VERSION ""

NS_ :

BS_:

BU_: WPC2 PSB SHVU_RR FCS EMCU SLB GW_APSU GW_DLBCU ARS RCM CGW_CCU GW_RLPSU ATS RLHV SGU PFSU ALBCU GW_RRPSU DSAU SWRC SHVU_FR RCS GW_DPSU BLTN_CAM SCM OHCL RWPC RRHV WPC HOD ASAU

BO_ 1941 GST_BLTN_CAM: 8 CGW_CCU
 SG_ GST_BLTN_CAM_Byte : 0|64@1+ (1,0) [0|0] ""  BLTN_CAM

BO_ 2015 GST_ALL: 8 CGW_CCU
 SG_ GST_ALL_Byte : 0|64@1+ (1,0) [0|0] ""  BLTN_CAM

BO_ 1949 BTLN_CAM_GST: 8 BLTN_CAM
 SG_ BLTN_CAM_GST_Byte : 0|64@1+ (1,0) [0|0] ""  CGW_CCU

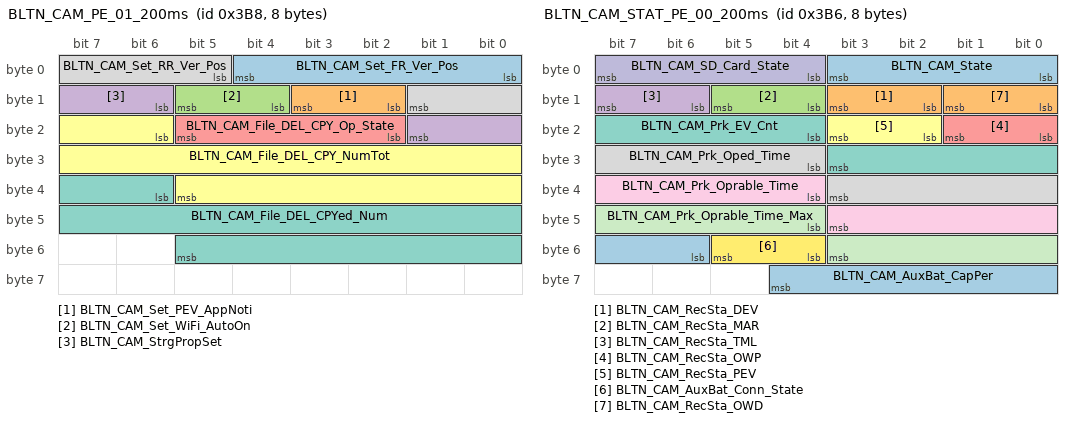
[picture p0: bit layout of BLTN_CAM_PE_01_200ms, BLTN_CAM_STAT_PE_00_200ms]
BO_ 952 BLTN_CAM_PE_01_200ms: 8 BLTN_CAM
 SG_ BLTN_CAM_Set_FR_Ver_Pos : 0|5@1+ (1,0) [0|0] ""  CGW_CCU
 SG_ BLTN_CAM_Set_PEV_AppNoti : 10|2@1+ (1,0) [0|0] ""  CGW_CCU
 SG_ BLTN_CAM_Set_WiFi_AutoOn : 12|2@1+ (1,0) [0|0] ""  CGW_CCU
 SG_ BLTN_CAM_StrgPropSet : 14|4@1+ (1,0) [0|0] ""  CGW_CCU
 SG_ BLTN_CAM_File_DEL_CPY_Op_State : 18|4@1+ (1,0) [0|0] ""  CGW_CCU
 SG_ BLTN_CAM_File_DEL_CPY_NumTot : 22|16@1+ (1,0) [0|0] ""  CGW_CCU
 SG_ BLTN_CAM_File_DEL_CPYed_Num : 38|16@1+ (1,0) [0|0] ""  CGW_CCU
 SG_ BLTN_CAM_Set_RR_Ver_Pos : 5|5@1+ (1,0) [0|0] ""  CGW_CCU

BO_ 1219 HU_BLTN_CAM_E_00: 8 CGW_CCU
 SG_ BLTN_CAM_Rec_OWD_NvalueSet : 0|2@1+ (1,0) [0|0] ""  BLTN_CAM
 SG_ BLTN_CAM_Time_Stm_NvalueSet : 10|2@1+ (1,0) [0|0] ""  BLTN_CAM
 SG_ BLTN_CAM_Spd_Stm_NvalueSet : 12|2@1+ (1,0) [0|0] ""  BLTN_CAM
 SG_ BLTN_CAM_Locatn_Stm_NvalueSet : 14|2@1+ (1,0) [0|0] ""  BLTN_CAM
 SG_ BLTN_CAM_TrnSig_Stm_NvalueSet : 16|2@1+ (1,0) [0|0] ""  BLTN_CAM
 SG_ BLTN_CAM_AclBrk_Stm_NvalueSet : 18|2@1+ (1,0) [0|0] ""  BLTN_CAM
 SG_ BLTN_CAM_Rec_DEV_NvalueSet : 2|2@1+ (1,0) [0|0] ""  BLTN_CAM
 SG_ BLTN_CAM_GearPos_Stm_NvalueSet : 20|2@1+ (1,0) [0|0] ""  BLTN_CAM
 SG_ BLTN_CAM_EVSen_Stm_NvalueSet : 22|2@1+ (1,0) [0|0] ""  BLTN_CAM
 SG_ BLTN_CAM_Strangl_Stm_NvalueSet : 24|2@1+ (1,0) [0|0] ""  BLTN_CAM
 SG_ BLTN_CAM_EV_RecMaxTime_NvalueSet : 26|2@1+ (1,0) [0|0] ""  BLTN_CAM
 SG_ BLTN_CAM_PrkTime_NvalueSet : 30|8@1+ (1,0) [0|0] "Hour"  BLTN_CAM
 SG_ BLTN_CAM_EV_BfrTime_NvalueSet : 38|5@1+ (1,0) [0|0] ""  BLTN_CAM
 SG_ BLTN_CAM_Rec_OWP_NvalueSet : 4|2@1+ (1,0) [0|0] ""  BLTN_CAM
 SG_ BLTN_CAM_EV_AftTime_NvalueSet : 43|5@1+ (1,0) [0|0] ""  BLTN_CAM
 SG_ BLTN_CAM_TML_Int_NvalueSet : 48|4@1+ (1,0) [0|0] ""  BLTN_CAM
 SG_ BLTN_CAM_Sen_DEV_NvalueSet : 52|4@1+ (1,0) [0|0] ""  BLTN_CAM
 SG_ BLTN_CAM_Sen_PEV_NvalueSet : 56|4@1+ (1,0) [0|0] ""  BLTN_CAM
 SG_ BLTN_CAM_Rec_PEV_NvalueSet : 6|2@1+ (1,0) [0|0] ""  BLTN_CAM
 SG_ BLTN_CAM_AudRec_NvalueSet : 8|2@1+ (1,0) [0|0] ""  BLTN_CAM

BO_ 950 BLTN_CAM_STAT_PE_00_200ms: 8 BLTN_CAM
 SG_ BLTN_CAM_State : 0|4@1+ (1,0) [0|0] ""  CGW_CCU
 SG_ BLTN_CAM_RecSta_DEV : 10|2@1+ (1,0) [0|0] ""  CGW_CCU
 SG_ BLTN_CAM_RecSta_MAR : 12|2@1+ (1,0) [0|0] ""  CGW_CCU
 SG_ BLTN_CAM_RecSta_TML : 14|2@1+ (1,0) [0|0] ""  CGW_CCU
 SG_ BLTN_CAM_RecSta_OWP : 16|2@1+ (1,0) [0|0] ""  CGW_CCU
 SG_ BLTN_CAM_RecSta_PEV : 18|2@1+ (1,0) [0|0] ""  CGW_CCU
 SG_ BLTN_CAM_Prk_EV_Cnt : 20|8@1+ (1,0) [0|0] ""  CGW_CCU
 SG_ BLTN_CAM_Prk_Oped_Time : 28|8@1+ (1,0) [0|0] "Hour"  CGW_CCU
 SG_ BLTN_CAM_Prk_Oprable_Time : 36|8@1+ (1,0) [0|0] "Hour"  CGW_CCU
 SG_ BLTN_CAM_SD_Card_State : 4|4@1+ (1,0) [0|0] ""  CGW_CCU
 SG_ BLTN_CAM_Prk_Oprable_Time_Max : 44|8@1+ (1,0) [0|0] "Hour"  CGW_CCU
 SG_ BLTN_CAM_AuxBat_Conn_State : 52|2@1+ (1,0) [0|0] ""  CGW_CCU
 SG_ BLTN_CAM_AuxBat_CapPer : 54|7@1+ (1,0) [0|0] "%"  CGW_CCU
 SG_ BLTN_CAM_RecSta_OWD : 8|2@1+ (1,0) [0|0] ""  CGW_CCU

BO_ 951 BLTN_CAM_PE_00_200ms: 8 BLTN_CAM
 SG_ BLTN_CAM_RecSet_OWD : 0|2@1+ (1,0) [0|0] ""  CGW_CCU
 SG_ BLTN_CAM_Set_Tim_Stm : 10|2@1+ (1,0) [0|0] ""  CGW_CCU
 SG_ BLTN_CAM_Set_Spd_Stm : 12|2@1+ (1,0) [0|0] ""  CGW_CCU
 SG_ BLTN_CAM_Set_Locatn_Stm : 14|2@1+ (1,0) [0|0] ""  CGW_CCU
 SG_ BLTN_CAM_Set_TrnSig_Stm : 16|2@1+ (1,0) [0|0] ""  CGW_CCU
 SG_ BLTN_CAM_Set_AclBrk_Stm : 18|2@1+ (1,0) [0|0] ""  CGW_CCU
 SG_ BLTN_CAM_RecSet_DEV : 2|2@1+ (1,0) [0|0] ""  CGW_CCU
 SG_ BLTN_CAM_Set_GearPos_Stm : 20|2@1+ (1,0) [0|0] ""  CGW_CCU
 SG_ BLTN_CAM_Set_EVSen_Stm : 22|2@1+ (1,0) [0|0] ""  CGW_CCU
 SG_ BLTN_CAM_Set_StrAngl_Stm : 24|2@1+ (1,0) [0|0] ""  CGW_CCU
 SG_ BLTN_CAM_Set_EV_RecMaxTime : 26|2@1+ (1,0) [0|0] ""  CGW_CCU
 SG_ BLTN_CAM_Set_PrkTime : 30|8@1+ (1,0) [0|0] "Hour"  CGW_CCU
 SG_ BLTN_CAM_Set_EV_BfrTime : 38|5@1+ (1,0) [0|0] ""  CGW_CCU
 SG_ BLTN_CAM_RecSet_OWP : 4|2@1+ (1,0) [0|0] ""  CGW_CCU
 SG_ BLTN_CAM_Set_EV_AftTime : 43|5@1+ (1,0) [0|0] ""  CGW_CCU
 SG_ BLTN_CAM_Set_Drv_TML_Int : 48|4@1+ (1,0) [0|0] ""  CGW_CCU
 SG_ BLTN_CAM_SenSet_DEV : 52|4@1+ (1,0) [0|0] ""  CGW_CCU
 SG_ BLTN_CAM_SenSet_PEV : 56|4@1+ (1,0) [0|0] ""  CGW_CCU
 SG_ BLTN_CAM_RecSet_PEV : 6|2@1+ (1,0) [0|0] ""  CGW_CCU
 SG_ BLTN_CAM_AudRec_Set : 8|2@1+ (1,0) [0|0] ""  CGW_CCU

BO_ 2307024129 EMS_08_100ms_1: 8 CGW_CCU
 SG_ HEV_BrkLtSwSta : 62|2@1+ (1,0) [0|0] ""  BLTN_CAM

BO_ 2176872449 HTCU_05_10ms_1: 8 CGW_CCU
 SG_ HDCT_GearSelDis : 60|4@1+ (1,0) [0|0] ""  SWRC,BLTN_CAM

BO_ 1239 HU_Car_PE_01: 8 CGW_CCU
 SG_ HU_PwrState : 16|4@1+ (1,0) [0|0] ""  BLTN_CAM
 SG_ HU_VehiclePwr : 4|4@1+ (1,0) [0|0] ""  BLTN_CAM,SGU

BO_ 1240 HU_GW_PE_01: 8 CGW_CCU
 SG_ HU_ThemeType : 10|6@1+ (1,0) [0|0] ""  ATS,BLTN_CAM
 SG_ CF_AVN_ProfileIDRValue : 40|4@1+ (1,0) [0|0] ""  BLTN_CAM,GW_DLBCU,GW_DPSU,RCM,RWPC,SGU,WPC,WPC2

BO_ 2214659330 EMS_07_10ms_2: 8 CGW_CCU
 SG_ HEV_AccelPdlVal : 39|10@1+ (0.09784,0) [0|0] "%"  BLTN_CAM

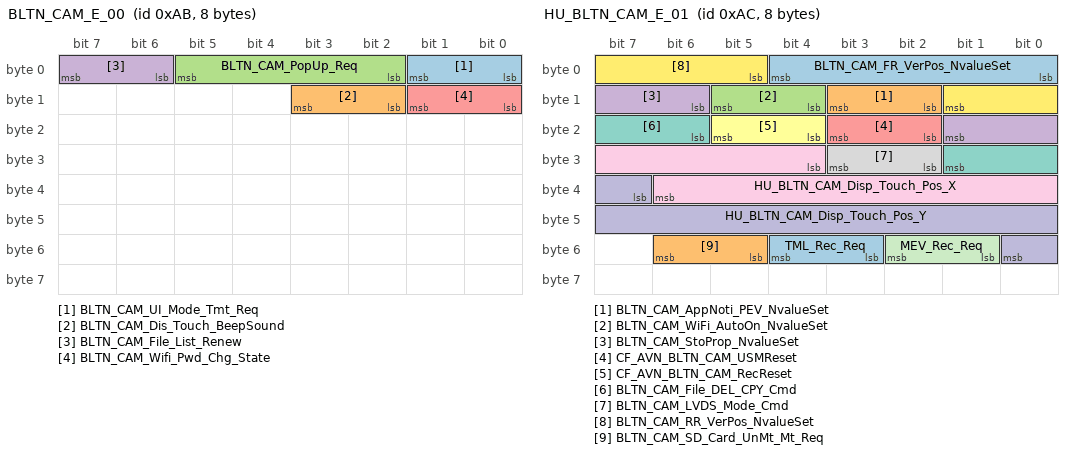
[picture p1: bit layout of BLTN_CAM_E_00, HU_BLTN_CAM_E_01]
BO_ 171 BLTN_CAM_E_00: 8 BLTN_CAM
 SG_ BLTN_CAM_UI_Mode_Tmt_Req : 0|2@1+ (1,0) [0|0] ""  CGW_CCU
 SG_ BLTN_CAM_Dis_Touch_BeepSound : 10|2@1+ (1,0) [0|0] ""  CGW_CCU
 SG_ BLTN_CAM_PopUp_Req : 2|4@1+ (1,0) [0|0] ""  CGW_CCU
 SG_ BLTN_CAM_File_List_Renew : 6|2@1+ (1,0) [0|0] ""  CGW_CCU
 SG_ BLTN_CAM_Wifi_Pwd_Chg_State : 8|2@1+ (1,0) [0|0] ""  CGW_CCU

BO_ 2164277249 TCU_01_10ms_1: 8 CGW_CCU
 SG_ TCU_GearSlctDis : 32|4@1+ (1,0) [0|0] ""  BLTN_CAM,GW_APSU,GW_RLPSU,GW_RRPSU,PFSU,RLHV,RRHV,SWRC

BO_ 2172675329 IEB_01_10ms_1: 8 CGW_CCU
 SG_ IEB_BrkActvSta : 56|2@1+ (1,0) [0|0] ""  BLTN_CAM

BO_ 172 HU_BLTN_CAM_E_01: 8 CGW_CCU
 SG_ BLTN_CAM_FR_VerPos_NvalueSet : 0|5@1+ (1,0) [0|0] ""  BLTN_CAM
 SG_ BLTN_CAM_AppNoti_PEV_NvalueSet : 10|2@1+ (1,0) [0|0] ""  BLTN_CAM
 SG_ BLTN_CAM_WiFi_AutoOn_NvalueSet : 12|2@1+ (1,0) [0|0] ""  BLTN_CAM
 SG_ BLTN_CAM_StoProp_NvalueSet : 14|4@1+ (1,0) [0|0] ""  BLTN_CAM
 SG_ CF_AVN_BLTN_CAM_USMReset : 18|2@1+ (1,0) [0|0] ""  BLTN_CAM
 SG_ CF_AVN_BLTN_CAM_RecReset : 20|2@1+ (1,0) [0|0] ""  BLTN_CAM
 SG_ BLTN_CAM_File_DEL_CPY_Cmd : 22|4@1+ (1,0) [0|0] ""  BLTN_CAM
 SG_ BLTN_CAM_LVDS_Mode_Cmd : 26|2@1+ (1,0) [0|0] ""  BLTN_CAM
 SG_ HU_BLTN_CAM_Disp_Touch_Pos_X : 28|11@1+ (1,0) [0|0] ""  BLTN_CAM
 SG_ HU_BLTN_CAM_Disp_Touch_Pos_Y : 39|10@1+ (1,0) [0|0] ""  BLTN_CAM
 SG_ MEV_Rec_Req : 49|2@1+ (1,0) [0|0] ""  BLTN_CAM
 SG_ BLTN_CAM_RR_VerPos_NvalueSet : 5|5@1+ (1,0) [0|0] ""  BLTN_CAM
 SG_ TML_Rec_Req : 51|2@1+ (1,0) [0|0] ""  BLTN_CAM
 SG_ BLTN_CAM_SD_Card_UnMt_Mt_Req : 53|2@1+ (1,0) [0|0] ""  BLTN_CAM

BO_ 799 SBCM_DRV_01_200ms: 8 CGW_CCU
 SG_ DRV_CrashUnlockCmd : 10|1@1+ (1,0) [0|0] ""  BLTN_CAM
 SG_ Warn_DrvDrSwSta_SBCM : 20|2@1+ (1,0) [0|0] ""  ATS,BLTN_CAM,GW_DPSU,PSB,RWPC,WPC,WPC2

BO_ 2227254529 BAT_01_10ms_1: 8 CGW_CCU
 SG_ BAT_SocVal : 40|8@1+ (1,0) [0|0] "%"  BLTN_CAM

BO_ 912 HU_BLTN_CAM_PE_00_200ms: 8 CGW_CCU
 SG_ HU_BLTN_CAM_UI_Mode : 0|4@1+ (1,0) [0|0] ""  BLTN_CAM
 SG_ HU_BLTN_CAM_Display : 4|3@1+ (1,0) [0|0] ""  BLTN_CAM

BO_ 1266 HU_CLU_PE_05: 8 CGW_CCU
 SG_ HU_LanguageInfo : 0|8@1+ (1,0) [0|0] ""  ATS,BLTN_CAM

BO_ 905 SBCM_RR_01_200ms: 8 CGW_CCU
 SG_ RR_CrashUnlockCmd : 10|1@1+ (1,0) [0|0] ""  BLTN_CAM
 SG_ Warn_RrRtDrSwSta_SBCM : 16|2@1+ (1,0) [0|0] ""  ATS,BLTN_CAM,GW_APSU,GW_RLPSU,GW_RRPSU,RWPC,WPC,WPC2

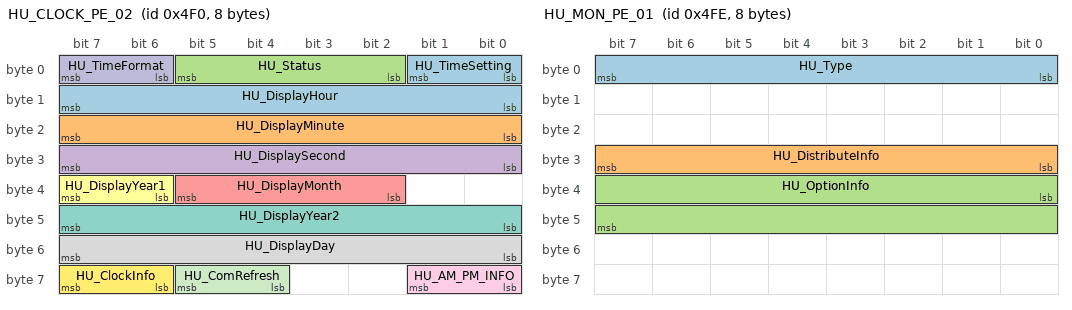
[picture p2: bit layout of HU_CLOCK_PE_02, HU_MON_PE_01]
BO_ 1264 HU_CLOCK_PE_02: 8 CGW_CCU
 SG_ HU_TimeSetting : 0|2@1+ (1,0) [0|0] ""  ATS,BLTN_CAM
 SG_ HU_DisplayMinute : 16|8@1+ (1,0) [0|0] ""  ATS,BLTN_CAM
 SG_ HU_Status : 2|4@1+ (1,0) [0|0] ""  ATS,BLTN_CAM
 SG_ HU_DisplaySecond : 24|8@1+ (1,0) [0|0] ""  ATS,BLTN_CAM
 SG_ HU_DisplayMonth : 34|4@1+ (1,0) [0|0] ""  ATS,BLTN_CAM
 SG_ HU_DisplayYear1 : 38|2@1+ (1,0) [0|0] ""  ATS,BLTN_CAM
 SG_ HU_DisplayYear2 : 40|8@1+ (1,0) [0|0] ""  ATS,BLTN_CAM
 SG_ HU_DisplayDay : 48|8@1+ (1,0) [0|0] ""  ATS,BLTN_CAM
 SG_ HU_AM_PM_INFO : 56|2@1+ (1,0) [0|0] ""  ATS,BLTN_CAM
 SG_ HU_TimeFormat : 6|2@1+ (1,0) [0|0] ""  ATS,BLTN_CAM
 SG_ HU_ComRefresh : 60|2@1+ (1,0) [0|0] ""  ATS,BLTN_CAM
 SG_ HU_ClockInfo : 62|2@1+ (1,0) [0|0] ""  ATS,BLTN_CAM
 SG_ HU_DisplayHour : 8|8@1+ (1,0) [0|0] ""  ATS,BLTN_CAM

BO_ 1265 HU_GW_PE_02: 8 CGW_CCU
 SG_ HU_Background : 18|3@1+ (1,0) [0|0] ""  ATS,BLTN_CAM
 SG_ HU_BackgroundFadeInOut : 24|10@1+ (0.1,0) [0|0] "%"  ATS,BLTN_CAM

BO_ 1278 HU_MON_PE_01: 8 CGW_CCU
 SG_ HU_Type : 0|8@1+ (1,0) [0|0] ""  BLTN_CAM
 SG_ HU_DistributeInfo : 24|8@1+ (1,0) [0|0] ""  BLTN_CAM
 SG_ HU_OptionInfo : 32|16@1+ (1,0) [0|0] ""  RCM,BLTN_CAM,WPC2

BO_ 2256644609 CLU_01_20ms_1: 8 CGW_CCU
 SG_ CLU_SpdUnitTyp : 30|2@1+ (1,0) [0|0] ""  BLTN_CAM,EMCU,GW_DPSU,WPC2
 SG_ CLU_DisSpdVal : 48|10@1+ (0.5,0) [0|0] "km/h or MPH"  BLTN_CAM,EMCU,GW_APSU,GW_DPSU,WPC2

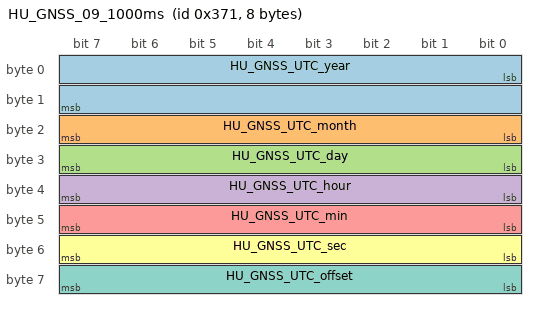
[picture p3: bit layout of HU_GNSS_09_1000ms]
BO_ 881 HU_GNSS_09_1000ms: 8 CGW_CCU
 SG_ HU_GNSS_UTC_year : 0|16@1+ (1,0) [0|0] ""  BLTN_CAM
 SG_ HU_GNSS_UTC_month : 16|8@1+ (1,0) [0|0] ""  BLTN_CAM
 SG_ HU_GNSS_UTC_day : 24|8@1+ (1,0) [0|0] ""  BLTN_CAM
 SG_ HU_GNSS_UTC_hour : 32|8@1+ (1,0) [0|0] ""  BLTN_CAM
 SG_ HU_GNSS_UTC_min : 40|8@1+ (1,0) [0|0] ""  BLTN_CAM
 SG_ HU_GNSS_UTC_sec : 48|8@1+ (1,0) [0|0] ""  BLTN_CAM
 SG_ HU_GNSS_UTC_offset : 56|8@1+ (1,0) [0|0] "Sec"  BLTN_CAM

BO_ 1016 HU_GNSS_14_1000ms: 8 CGW_CCU
 SG_ GNSS_MM_type : 0|4@1+ (1,0) [0|0] ""  BLTN_CAM

BO_ 883 HU_GNSS_11_1000ms: 8 CGW_CCU
 SG_ HU_GNSS_DST : 16|2@1+ (1,0) [0|0] ""  BLTN_CAM
 SG_ HU_GNSS_TimezoneOffset : 26|8@1- (15,0) [0|0] "minute"  BLTN_CAM

BO_ 2256644610 CLU_01_20ms_2: 8 CGW_CCU
 SG_ CLU_AutoBrightSta : 15|8@1+ (1,0) [0|0] ""  ASAU,ATS,BLTN_CAM,DSAU,FCS,GW_APSU,GW_DPSU,GW_RLPSU,GW_RRPSU,OHCL,RCS,RLHV,RRHV,RWPC,SHVU_FR,SHVU_RR,SWRC,WPC,WPC2

BO_ 2214658049 EMS_02_10ms_1: 8 CGW_CCU
 SG_ ENG_BrkSwSta : 32|2@1+ (1,0) [0|0] ""  BLTN_CAM
 SG_ ENG_EngSta : 61|3@1+ (1,0) [0|0] ""  BLTN_CAM,EMCU,GW_APSU,GW_DLBCU,GW_DPSU,GW_RLPSU,GW_RRPSU,HOD,PFSU,PSB,RCM,RLHV,RRHV,RWPC,SCM,SHVU_FR,SHVU_RR,SWRC,WPC,WPC2

BO_ 2223056129 SAS_01_10ms_1: 8 CGW_CCU
 SG_ SAS_AnglVal : 24|16@1- (0.1,0) [0|0] "Deg"  PSB,BLTN_CAM

BO_ 884 HU_GNSS_12_1000ms: 8 CGW_CCU
 SG_ HU_MM_Latitude : 0|32@1- (1E-006,0) [0|0] "˚"  BLTN_CAM
 SG_ HU_MM_Longitude : 32|32@1- (1E-006,0) [0|0] "˚"  BLTN_CAM

CM_ BO_ 952 "[PE] Periodic and On Event";
CM_ SG_ 952 BLTN_CAM_Set_FR_Ver_Pos "Front Camera Vertical position setting value.";
CM_ SG_ 952 BLTN_CAM_Set_PEV_AppNoti "Parked Event notification to Connectivity Phone App. On/Off";
CM_ SG_ 952 BLTN_CAM_Set_WiFi_AutoOn "Wifi On/Off User setting";
CM_ SG_ 952 BLTN_CAM_StrgPropSet "Propotion of built-in Cam SD card Propotion set of the Recording Categories";
CM_ SG_ 952 BLTN_CAM_File_DEL_CPY_Op_State "Bulil in Cam Fily copy and delete operating state.";
CM_ SG_ 952 BLTN_CAM_File_DEL_CPY_NumTot "Number of Copied or Deleted files.";
CM_ SG_ 952 BLTN_CAM_File_DEL_CPYed_Num "Total number of the copy or delete file.";
CM_ SG_ 952 BLTN_CAM_Set_RR_Ver_Pos "Rear Camera Vertical position setting value.";
CM_ BO_ 1219 "[EC] On Event and On Change";
CM_ SG_ 1219 BLTN_CAM_Rec_OWD_NvalueSet "Record On/Off Set of On While Driving";
CM_ SG_ 1219 BLTN_CAM_Time_Stm_NvalueSet "Record Set of Date and Time Stamp";
CM_ SG_ 1219 BLTN_CAM_Spd_Stm_NvalueSet "Record Set of Speed Stamp";
CM_ SG_ 1219 BLTN_CAM_Locatn_Stm_NvalueSet "Record Set of Location Stamp";
CM_ SG_ 1219 BLTN_CAM_TrnSig_Stm_NvalueSet "Record Set of Turn Signal Stamp";
CM_ SG_ 1219 BLTN_CAM_AclBrk_Stm_NvalueSet "Record Set of Accelerator Brake Stamp";
CM_ SG_ 1219 BLTN_CAM_Rec_DEV_NvalueSet "Record On/Off Set of Driving Event";
CM_ SG_ 1219 BLTN_CAM_GearPos_Stm_NvalueSet "Record Set of Gear Position Stamp";
CM_ SG_ 1219 BLTN_CAM_EVSen_Stm_NvalueSet "Record Set of Event Sensitivity Stamp";
CM_ SG_ 1219 BLTN_CAM_Strangl_Stm_NvalueSet "Record Set of Steering Angle Stamp";
CM_ SG_ 1219 BLTN_CAM_EV_RecMaxTime_NvalueSet "Record Set of  EV Parking Rec Max Time On/Off";
CM_ SG_ 1219 BLTN_CAM_PrkTime_NvalueSet "Parking Operation Setting Time, Resolution : hr";
CM_ SG_ 1219 BLTN_CAM_EV_BfrTime_NvalueSet "Driving Event Time Setting - Before, Resolution : sec";
CM_ SG_ 1219 BLTN_CAM_Rec_OWP_NvalueSet "Record On/Off Set of On While Parked, 0x0(Default) : Parking recording function not supported";
CM_ SG_ 1219 BLTN_CAM_EV_AftTime_NvalueSet "Driving Event Time Setting - After, Resolution : sec";
CM_ SG_ 1219 BLTN_CAM_TML_Int_NvalueSet "Record Set of Time-lapse Interval, Resolution : sec";
CM_ SG_ 1219 BLTN_CAM_Sen_DEV_NvalueSet "Set of Event  Detection Sensitivity of Driving Mode";
CM_ SG_ 1219 BLTN_CAM_Sen_PEV_NvalueSet "Set of Event  Detection Sensitivity of Parking Mode";
CM_ SG_ 1219 BLTN_CAM_Rec_PEV_NvalueSet "Record Set of Parked Event, 0x0(Default) : Parking recording function not supported";
CM_ SG_ 1219 BLTN_CAM_AudRec_NvalueSet "Audio Record On/Off Set";
CM_ BO_ 950 "[PE] Periodic and On Event";
CM_ SG_ 950 BLTN_CAM_State "This Signal is for cluster warning popup.";
CM_ SG_ 950 BLTN_CAM_RecSta_DEV "This Signal inform recording status of Driving Event.";
CM_ SG_ 950 BLTN_CAM_RecSta_MAR "This Signal inform recording status of Manual Recording.";
CM_ SG_ 950 BLTN_CAM_RecSta_TML "This Signal inform recording status of Time-lapse.";
CM_ SG_ 950 BLTN_CAM_RecSta_OWP "This Signal inform recording status of On While Parked.";
CM_ SG_ 950 BLTN_CAM_RecSta_PEV "This Signal inform recording status of Parked Event.";
CM_ SG_ 950 BLTN_CAM_Prk_EV_Cnt "The count number of a parked Event.";
CM_ SG_ 950 BLTN_CAM_Prk_Oped_Time "The Parked Opreated time ingormation";
CM_ SG_ 950 BLTN_CAM_Prk_Oprable_Time "The hours of Park Mode Operatable, the time is limited by user max oper. Set.";
CM_ SG_ 950 BLTN_CAM_SD_Card_State "This Signal is for SD card Status in Built-in App menu and CCS Phone App.";
CM_ SG_ 950 BLTN_CAM_Prk_Oprable_Time_Max "The hours of Park Mode Operatable, the time has no limit.";
CM_ SG_ 950 BLTN_CAM_AuxBat_Conn_State "0x0 : Default / 0x1 : Auxiliary Battery is connected.(P-LBM or B-LBM) / 0x2 : Auxiliary Battery Is not connected. - Auxiliary Battery applicable on this vehicle model / 0x3:  Auxiliary Battery is not connected. ? Auxiliary Battery not applicable on this vehicle model";
CM_ SG_ 950 BLTN_CAM_AuxBat_CapPer "The percentage of Aux. Bat.";
CM_ SG_ 950 BLTN_CAM_RecSta_OWD "This Signal inform recording status of On While Driving.";
CM_ BO_ 951 "[PE] Periodic and On Event";
CM_ SG_ 951 BLTN_CAM_RecSet_OWD "Record On/Off Set of On While Driving";
CM_ SG_ 951 BLTN_CAM_Set_Tim_Stm "Record Set of Date and Time Stamp";
CM_ SG_ 951 BLTN_CAM_Set_Spd_Stm "Record Set of Speed Stamp";
CM_ SG_ 951 BLTN_CAM_Set_Locatn_Stm "Record Set of Location Stamp";
CM_ SG_ 951 BLTN_CAM_Set_TrnSig_Stm "Record Set of Turn Signal Stamp";
CM_ SG_ 951 BLTN_CAM_Set_AclBrk_Stm "Record Set of Accelerator Brake Stamp";
CM_ SG_ 951 BLTN_CAM_RecSet_DEV "Record On/Off Set of Driving Event";
CM_ SG_ 951 BLTN_CAM_Set_GearPos_Stm "Record Set of Gear Position Stamp";
CM_ SG_ 951 BLTN_CAM_Set_EVSen_Stm "Record Set of Event Sensitivity Stamp";
CM_ SG_ 951 BLTN_CAM_Set_StrAngl_Stm "Record Set of Steering Angle Stamp";
CM_ SG_ 951 BLTN_CAM_Set_EV_RecMaxTime "Record Set of  EV Parking Rec Max Time On/Off";
CM_ SG_ 951 BLTN_CAM_Set_PrkTime "Parking Operation Setting Time, Resolution : hr";
CM_ SG_ 951 BLTN_CAM_Set_EV_BfrTime "Driving Event Time Setting - Before, Resolution : sec";
CM_ SG_ 951 BLTN_CAM_RecSet_OWP "Record On/Off Set of On While Parked, 0x0(Default) : Parking recording function not supported";
CM_ SG_ 951 BLTN_CAM_Set_EV_AftTime "Driving Event Time Setting - After, Resolution : sec";
CM_ SG_ 951 BLTN_CAM_Set_Drv_TML_Int "Record Set of Time-lapse Interval, Resolution : sec";
CM_ SG_ 951 BLTN_CAM_SenSet_DEV "Set of Event  Detection Sensitivity of Driving Mode";
CM_ SG_ 951 BLTN_CAM_SenSet_PEV "Set of Event  Detection Sensitivity of Parking Mode";
CM_ SG_ 951 BLTN_CAM_RecSet_PEV "Record Set of Parked Event, 0x0(Default) : Parking recording function not supported";
CM_ SG_ 951 BLTN_CAM_AudRec_Set "Audio Record On/Off Set";
CM_ BO_ 2307024129 "[P] Periodic";
CM_ SG_ 2307024129 HEV_BrkLtSwSta "HEV_BrakeLightSwitchStatus";
CM_ BO_ 2176872449 "[P] Periodic";
CM_ SG_ 2176872449 HDCT_GearSelDis "Gear Select Display ## TCU11 - CF_Tcu_GarSelDisp";
CM_ BO_ 1239 "[PE] Periodic and On Event";
CM_ SG_ 1239 HU_VehiclePwr "Information for the H/U power status for ADM(Accessary Delay Mode)";
CM_ BO_ 1240 "[PE] Periodic and On Event";
CM_ SG_ 1240 CF_AVN_ProfileIDRValue "This signal is User ID value in H/Unit.";
CM_ BO_ 2214659330 "[P] Periodic";
CM_ SG_ 2214659330 HEV_AccelPdlVal "HEV_AcceleratorPedalValue";
CM_ BO_ 171 "[EC] On Event and On Change";
CM_ SG_ 171 BLTN_CAM_UI_Mode_Tmt_Req "Built-in Cam UI Mode terminate request.";
CM_ SG_ 171 BLTN_CAM_Dis_Touch_BeepSound "Display Touch Beep Sound of valid space touch.";
CM_ SG_ 171 BLTN_CAM_PopUp_Req "Built-in Cam Operating and SD Card related Popup Request on HU Display.";
CM_ SG_ 171 BLTN_CAM_File_List_Renew "The Storage information is renewed inform to HU.";
CM_ SG_ 171 BLTN_CAM_Wifi_Pwd_Chg_State "The Response, when HU change Wifi Passowrd via SOME/IP";
CM_ BO_ 2164277249 "[P] Periodic";
CM_ SG_ 2164277249 TCU_GearSlctDis "TCU_GearSelectDisplay";
CM_ BO_ 2172675329 "[P] Periodic";
CM_ SG_ 2172675329 IEB_BrkActvSta "IEB_BrakeActiveStatus ##2G##ESC - AHB1 - CF_Esc_BrakeAct";
CM_ BO_ 172 "[EC] On Event and On Change";
CM_ SG_ 172 BLTN_CAM_FR_VerPos_NvalueSet "Front Camera Vertical position setting value.";
CM_ SG_ 172 BLTN_CAM_AppNoti_PEV_NvalueSet "Parked Event notification to Connectivity Phone App. On/Off";
CM_ SG_ 172 BLTN_CAM_WiFi_AutoOn_NvalueSet "Wifi On/Off User setting";
CM_ SG_ 172 BLTN_CAM_StoProp_NvalueSet "Propotion of built-in Cam SD card Propotion set of the Recording Categories";
CM_ SG_ 172 CF_AVN_BLTN_CAM_USMReset "Buit-in Cam USM Reset Request.";
CM_ SG_ 172 CF_AVN_BLTN_CAM_RecReset "Buit-in Cam format(all file delete/Reset) Request.";
CM_ SG_ 172 BLTN_CAM_File_DEL_CPY_Cmd "Buit-in Cam operation control of copying and deleting.";
CM_ SG_ 172 BLTN_CAM_LVDS_Mode_Cmd "This Signal is for LVDS output commend to BLTN_CAM";
CM_ SG_ 172 HU_BLTN_CAM_Disp_Touch_Pos_X "X position of touch of display when BLTN-in CAM Engineer mode in";
CM_ SG_ 172 HU_BLTN_CAM_Disp_Touch_Pos_Y "Y position of touch of display when BLTN-in CAM Engineer mode in";
CM_ SG_ 172 MEV_Rec_Req "0x1(On) : MEV Record Request.";
CM_ SG_ 172 BLTN_CAM_RR_VerPos_NvalueSet "Rear Camera Vertical position setting value.";
CM_ SG_ 172 TML_Rec_Req "0x1 : Start Request, 0x2 : End Request";
CM_ SG_ 172 BLTN_CAM_SD_Card_UnMt_Mt_Req "0x0(Default), 0x1(UnMount Request), 0x2(Mount Request), 0x3(Invalid)";
CM_ BO_ 799 "[PE] Periodic and On Event";
CM_ SG_ 799 Warn_DrvDrSwSta_SBCM "DoorLock_DriverDoorSwitchStatus ##2G## -  - C_DrvDrSw,CF_Gway_DrvDrSw,Warn_DrvDrSwSta";
CM_ BO_ 2227254529 "[P] Periodic";
CM_ SG_ 2227254529 BAT_SocVal "BAT_StateOfChargeValue";
CM_ BO_ 912 "[PE] Periodic and On Event";
CM_ SG_ 912 HU_BLTN_CAM_UI_Mode "Display control of Built-in Cam UI mode. This Signal for Ethernet Type Built-in Cam.";
CM_ SG_ 912 HU_BLTN_CAM_Display "Display control of Built-in Cam UI mode. This Signal for CAN Type Built-in Cam.(with Standard 5th Wide AVNT)";
CM_ BO_ 1266 "[PE] Periodic and On Event";
CM_ SG_ 1266 HU_LanguageInfo "Information for System Language (for Display Font)";
CM_ BO_ 905 "[PE] Periodic and On Event";
CM_ SG_ 905 RR_CrashUnlockCmd "Rear Right Crash Unlock Command";
CM_ SG_ 905 Warn_RrRtDrSwSta_SBCM "Warn_RearRightDoorSwitchStatus ##2G## -  - C_RRDrSw,CF_Gway_RRDrSw,Warn_RrRtDrSwSta";
CM_ BO_ 1264 "[PE] Periodic and On Event";
CM_ SG_ 1264 HU_TimeSetting "Information for current time setting";
CM_ SG_ 1264 HU_DisplayMinute "Information for time display in Minute unit";
CM_ SG_ 1264 HU_Status "Information for H/U status
Transmitted on H/U status changing";
CM_ SG_ 1264 HU_DisplaySecond "Information for time display in Second unit";
CM_ SG_ 1264 HU_DisplayMonth "Information for Month";
CM_ SG_ 1264 HU_DisplayYear1 "Information for Year (XXOO)
XX : HU_DisplayYear1
OO: HU_DisplayYear2";
CM_ SG_ 1264 HU_DisplayYear2 "Information for Year (XXOO)
XX : HU_DisplayYear1
OO: HU_DisplayYear2";
CM_ SG_ 1264 HU_DisplayDay "Information for Day";
CM_ SG_ 1264 HU_AM_PM_INFO "Information for AM/PM";
CM_ SG_ 1264 HU_TimeFormat "Information for time format
Digital CLOCK only";
CM_ SG_ 1264 HU_DisplayHour "Information for time display in Hour unit";
CM_ BO_ 1265 "[PE] Periodic and On Event";
CM_ SG_ 1265 HU_Background "HU Backgound image info";
CM_ SG_ 1265 HU_BackgroundFadeInOut "HU Background Fade in/out info - (HEX * Factor) %";
CM_ BO_ 1278 "[PE] Periodic and On Event";
CM_ SG_ 1278 HU_Type "Information for H/U Platform type
- Integrated AVN 1.0 use different value depends on development company (Mobis:0x68/LG:0x70)
- Integrated AVN 1.0 Mobis is developed based on Display Audio
- Integrated AVN 1.0 LG is developed based on Compact AVN

Information for China OPIO Platform
- 0xFC: China OPIO w/o CLU interface (most of phase1)
- 0xFD: China OPIO w/CLU interface (parts of phase1, phase2)

Information for Audio Platform Type
- 0x43 : Audio 4.0 Value";
CM_ SG_ 1278 HU_DistributeInfo "Region :Europe/North America/
Vehicle Type : RHD/LHD
Positionning information";
CM_ SG_ 1278 HU_OptionInfo "Information of H/U functions";
CM_ BO_ 2256644609 "[P] Periodic";
CM_ SG_ 2256644609 CLU_SpdUnitTyp "CLU_SpeedUnitType";
CM_ SG_ 2256644609 CLU_DisSpdVal "CLU_DisplaySpeedValue";
CM_ BO_ 881 "[P] Periodic";
CM_ SG_ 881 HU_GNSS_UTC_year "UTC year";
CM_ SG_ 881 HU_GNSS_UTC_hour "UTC_HOUR";
CM_ BO_ 1016 "[P] Periodic";
CM_ SG_ 1016 GNSS_MM_type "Map matching type info.";
CM_ BO_ 883 "[P] Periodic";
CM_ SG_ 883 HU_GNSS_DST "DST setting";
CM_ SG_ 883 HU_GNSS_TimezoneOffset "Timezone Offset";
CM_ BO_ 2256644610 "[P] Periodic";
CM_ SG_ 2256644610 CLU_AutoBrightSta "CLU_AutoBrightStatus";
CM_ BO_ 2214658049 "[P] Periodic";
CM_ SG_ 2214658049 ENG_BrkSwSta "ENG_BrakeSwitchStatus ##2G##EMS - EMS12 - BRAKE_ACT";
CM_ SG_ 2214658049 ENG_EngSta "ENG_EngineStatus ##2G##EMS - EMS16 - ENG_STAT";
CM_ BO_ 2223056129 "[P] Periodic";
CM_ SG_ 2223056129 SAS_AnglVal "SAS_AngleValue";
CM_ BO_ 884 "[P] Periodic";
CM_ SG_ 884 HU_MM_Latitude "Map matching Latitude";
CM_ SG_ 884 HU_MM_Longitude "Mapmatching Longitude";
BA_DEF_ BO_  "DiagState" ENUM  "No","Yes";
BA_DEF_ BO_  "DiagResponse" ENUM  "No","Yes";
BA_DEF_ BO_  "DiagRequest" ENUM  "No","Yes";
BA_DEF_ BO_  "TpMessage" ENUM  "No","Yes";
BA_DEF_ BO_  "UsrMsgIDSforwardDeviation" INT 0 100;
BA_DEF_ BO_  "UsrMsgIDSbackwardDeviation" INT 50 1000;
BA_DEF_  "BusType" STRING ;
BA_DEF_  "DBName" STRING ;
BA_DEF_  "Baudrate" INT 50000 1000000;
BA_DEF_  "GenEnvVarEndingDsp" STRING ;
BA_DEF_  "GenEnvVarEndingSnd" STRING ;
BA_DEF_  "GenEnvVarPrefix" STRING ;
BA_DEF_  "GenNWMApBusSleep" STRING ;
BA_DEF_  "GenNWMApCanNormal" STRING ;
BA_DEF_  "GenNWMApCanOff" STRING ;
BA_DEF_  "GenNWMApCanOn" STRING ;
BA_DEF_  "GenNWMApCanSleep" STRING ;
BA_DEF_  "GenNWMApCanWakeUp" STRING ;
BA_DEF_  "GenNWMGotoMode_Awake" STRING ;
BA_DEF_  "GenNWMGotoMode_BusSleep" STRING ;
BA_DEF_  "GenNWMSleepTime" INT 1375 1650;
BA_DEF_  "GenNWMTalkNM" STRING ;
BA_DEF_  "Manufacturer" STRING ;
BA_DEF_  "NmBaseAddress" HEX 0 2047;
BA_DEF_  "NmMessageCount" INT 0 128;
BA_DEF_  "NmType" STRING ;
BA_DEF_  "SamplePointMax" INT 50 85;
BA_DEF_  "SamplePointMin" INT 55 85;
BA_DEF_  "SyncJumpWidthMax" INT 1 8;
BA_DEF_  "SyncJumpWidthMin" INT 1 4;
BA_DEF_  "VersionDay" INT 1 31;
BA_DEF_  "VersionMonth" INT 1 12;
BA_DEF_  "VersionNumber" INT 0 999999;
BA_DEF_  "VersionNumberInternal" INT 0 9999;
BA_DEF_  "VersionWeek" INT 1 53;
BA_DEF_  "VersionYear" INT 0 9999;
BA_DEF_ BU_  "NmStationAddress" HEX 0 127;
BA_DEF_ BU_  "NmNode" ENUM  "No","Yes";
BA_DEF_ BU_  "GenNodSleepTime" INT 1375 1650;
BA_DEF_ BU_  "ILUsed" ENUM  "No","Yes";
BA_DEF_ BU_  "NmCAN" INT 1 2;
BA_DEF_ BU_  "NodeLayerModules" STRING ;
BA_DEF_ BU_  "NWM_Knoten" ENUM  "No","Yes";
BA_DEF_ BO_  "GenMsgCycleTime" INT 0 2000;
BA_DEF_ BO_  "GenMsgStartDelayTime" INT 0 2000;
BA_DEF_ BO_  "GenMsgSendType" ENUM  "Cyclic","NoMsgSendType";
BA_DEF_ BO_  "GenMsgCycleTimeFast" INT 0 500;
BA_DEF_ BO_  "GenMsgDelayTime" INT 0 20;
BA_DEF_ BO_  "GenMsgFastOnStart" INT 0 0;
BA_DEF_ BO_  "GenMsgILSupport" ENUM  "No","Yes";
BA_DEF_ BO_  "GenMsgNrOfRepetition" INT 0 3;
BA_DEF_ BO_  "NmMessage" ENUM  "No","Yes";
BA_DEF_ BO_  "NWM-Botschaft" ENUM  "No","Yes";
BA_DEF_ BO_  "TpTxIndex" INT 0 65535;
BA_DEF_ BO_  "VFrameFormat" ENUM  "StandardCAN","ExtendedCAN","reserved","reserved","reserved","reserved","reserved","reserved","reserved","reserved","reserved","reserved","reserved","reserved","StandardCAN_FD","ExtendedCAN_FD";
BA_DEF_ SG_  "UserSigValidity" ENUM  "B+","ACC","IG","IG1","IG2","IG3","IG1 or IG2","IG1 or IG3","Undef";
BA_DEF_ SG_  "UsrSigPurpose" ENUM  "Undef","FN","DIAG","DIAG(Req)","DIAG(Res)","DIAG(Phy)","DEV","CCP(Req)","CCP(Res)","NM","TP";
BA_DEF_ SG_  "GenSigStartValue" INT 0 1215752192;
BA_DEF_ SG_  "NetworkRequest" ENUM  "Yes","No";
BA_DEF_ SG_  "NetworkRequestHoldingTime" INT 0 65535;
BA_DEF_ SG_  "Description" STRING ;
BA_DEF_ SG_  "Version" STRING ;
BA_DEF_ SG_  "GenSigEnvVarType" ENUM  "Int","Float","Undef";
BA_DEF_ SG_  "GenSigSendType" ENUM  "Cyclic","OnWrite","OnWriteWithRepetition","OnChange","OnChangeWithRepetition","IfActive","IfActiveWithRepetition","NoSigSendType","OnChangeAndIfActive","OnChangeAndIfActiveWithRepetition";
BA_DEF_ SG_  "GwSigLatencyTime" INT 0 65536;
BA_DEF_ SG_  "GwSigMissingSourceType" ENUM  "Undef","OldValue","DefaultValue","InitialValue";
BA_DEF_ SG_  "NWM-WakeupAllowed" ENUM  "<n.a.>";
BA_DEF_ SG_  "RoutingFactor" INT 1 1215752192;
BA_DEF_REL_ BU_SG_REL_  "GenSigTimeoutTime" INT 0 7000;
BA_DEF_DEF_  "DiagState" "No";
BA_DEF_DEF_  "DiagResponse" "No";
BA_DEF_DEF_  "DiagRequest" "No";
BA_DEF_DEF_  "TpMessage" "No";
BA_DEF_DEF_  "UsrMsgIDSforwardDeviation" 10;
BA_DEF_DEF_  "UsrMsgIDSbackwardDeviation" 100;
BA_DEF_DEF_  "BusType" "CAN";
BA_DEF_DEF_  "DBName" "";
BA_DEF_DEF_  "Baudrate" 500000;
BA_DEF_DEF_  "GenEnvVarEndingDsp" "Dsp_";
BA_DEF_DEF_  "GenEnvVarEndingSnd" "_";
BA_DEF_DEF_  "GenEnvVarPrefix" "Env";
BA_DEF_DEF_  "GenNWMApBusSleep" "AppNmCanBusSleep()";
BA_DEF_DEF_  "GenNWMApCanNormal" "AppNmCanNormal()";
BA_DEF_DEF_  "GenNWMApCanOff" "ApplCanOffline()";
BA_DEF_DEF_  "GenNWMApCanOn" "ApplCanOnline()";
BA_DEF_DEF_  "GenNWMApCanSleep" "ApplNmCanSleep()";
BA_DEF_DEF_  "GenNWMApCanWakeUp" "ApplCanWakeUp()";
BA_DEF_DEF_  "GenNWMGotoMode_Awake" "GotoMode_Awake()";
BA_DEF_DEF_  "GenNWMGotoMode_BusSleep" "GotoMode_BusSleep()";
BA_DEF_DEF_  "GenNWMSleepTime" 1500;
BA_DEF_DEF_  "GenNWMTalkNM" "TalkNM()";
BA_DEF_DEF_  "Manufacturer" "HMC";
BA_DEF_DEF_  "NmBaseAddress" 1280;
BA_DEF_DEF_  "NmMessageCount" 128;
BA_DEF_DEF_  "NmType" "Vector";
BA_DEF_DEF_  "SamplePointMax" 80;
BA_DEF_DEF_  "SamplePointMin" 80;
BA_DEF_DEF_  "SyncJumpWidthMax" 3;
BA_DEF_DEF_  "SyncJumpWidthMin" 2;
BA_DEF_DEF_  "VersionDay" 1;
BA_DEF_DEF_  "VersionMonth" 1;
BA_DEF_DEF_  "VersionNumber" 0;
BA_DEF_DEF_  "VersionNumberInternal" 0;
BA_DEF_DEF_  "VersionWeek" 1;
BA_DEF_DEF_  "VersionYear" 0;
BA_DEF_DEF_  "NmStationAddress" 0;
BA_DEF_DEF_  "NmNode" "Yes";
BA_DEF_DEF_  "GenNodSleepTime" 1500;
BA_DEF_DEF_  "ILUsed" "Yes";
BA_DEF_DEF_  "NmCAN" 1;
BA_DEF_DEF_  "NodeLayerModules" "oseknm01.dll,CANoeILNLVector.dll";
BA_DEF_DEF_  "NWM_Knoten" "Yes";
BA_DEF_DEF_  "GenMsgCycleTime" 200;
BA_DEF_DEF_  "GenMsgStartDelayTime" 0;
BA_DEF_DEF_  "GenMsgSendType" "NoMsgSendType";
BA_DEF_DEF_  "GenMsgCycleTimeFast" 40;
BA_DEF_DEF_  "GenMsgDelayTime" 20;
BA_DEF_DEF_  "GenMsgFastOnStart" 0;
BA_DEF_DEF_  "GenMsgILSupport" "Yes";
BA_DEF_DEF_  "GenMsgNrOfRepetition" 3;
BA_DEF_DEF_  "NmMessage" "No";
BA_DEF_DEF_  "NWM-Botschaft" "No";
BA_DEF_DEF_  "TpTxIndex" 0;
BA_DEF_DEF_  "VFrameFormat" "StandardCAN";
BA_DEF_DEF_  "UserSigValidity" "IG";
BA_DEF_DEF_  "UsrSigPurpose" "FN";
BA_DEF_DEF_  "GenSigStartValue" 0;
BA_DEF_DEF_  "NetworkRequest" "No";
BA_DEF_DEF_  "NetworkRequestHoldingTime" 0;
BA_DEF_DEF_  "Description" "";
BA_DEF_DEF_  "Version" "";
BA_DEF_DEF_  "GenSigEnvVarType" "Undef";
BA_DEF_DEF_  "GenSigSendType" "NoSigSendType";
BA_DEF_DEF_  "GwSigLatencyTime" 40;
BA_DEF_DEF_  "GwSigMissingSourceType" "Undef";
BA_DEF_DEF_  "NWM-WakeupAllowed" "<n.a.>";
BA_DEF_DEF_  "RoutingFactor" 1;
BA_DEF_DEF_REL_ "GenSigTimeoutTime" 500;
BA_ "VersionNumber" 230501;
BA_ "VersionYear" 1;
BA_ "DBName" "HS_B2";
BA_ "NmStationAddress" BU_ WPC2 21;
BA_ "NmStationAddress" BU_ PSB 65;
BA_ "NmStationAddress" BU_ SHVU_RR 43;
BA_ "NmStationAddress" BU_ FCS 33;
BA_ "NmStationAddress" BU_ EMCU 17;
BA_ "NmStationAddress" BU_ SLB 27;
BA_ "NmStationAddress" BU_ GW_APSU 49;
BA_ "NmStationAddress" BU_ GW_DLBCU 64;
BA_ "NmStationAddress" BU_ ARS 10;
BA_ "NmStationAddress" BU_ RCM 61;
BA_ "NmStationAddress" BU_ CGW_CCU 112;
BA_ "NmStationAddress" BU_ GW_RLPSU 28;
BA_ "NmStationAddress" BU_ ATS 80;
BA_ "NmStationAddress" BU_ RLHV 52;
BA_ "NmStationAddress" BU_ SGU 62;
BA_ "NmStationAddress" BU_ PFSU 45;
BA_ "NmStationAddress" BU_ ALBCU 68;
BA_ "NmStationAddress" BU_ GW_RRPSU 29;
BA_ "NmStationAddress" BU_ DSAU 89;
BA_ "NmStationAddress" BU_ SWRC 8;
BA_ "NmStationAddress" BU_ SHVU_FR 42;
BA_ "NmStationAddress" BU_ RCS 70;
BA_ "NmStationAddress" BU_ GW_DPSU 56;
BA_ "NmStationAddress" BU_ BLTN_CAM 72;
BA_ "NmStationAddress" BU_ SCM 7;
BA_ "NmStationAddress" BU_ OHCL 84;
BA_ "NmStationAddress" BU_ RWPC 31;
BA_ "NmStationAddress" BU_ RRHV 53;
BA_ "NmStationAddress" BU_ WPC 30;
BA_ "NmStationAddress" BU_ HOD 74;
BA_ "NmStationAddress" BU_ ASAU 83;
BA_ "GenMsgNrOfRepetition" BO_ 1941 0;
BA_ "GenMsgILSupport" BO_ 1941 0;
BA_ "GenMsgCycleTimeFast" BO_ 1941 0;
BA_ "GenMsgCycleTime" BO_ 1941 0;
BA_ "TpMessage" BO_ 1941 1;
BA_ "DiagRequest" BO_ 1941 1;
BA_ "GenMsgNrOfRepetition" BO_ 2015 0;
BA_ "GenMsgILSupport" BO_ 2015 0;
BA_ "GenMsgCycleTimeFast" BO_ 2015 0;
BA_ "GenMsgCycleTime" BO_ 2015 0;
BA_ "TpMessage" BO_ 2015 1;
BA_ "DiagState" BO_ 2015 1;
BA_ "TpTxIndex" BO_ 1949 123;
BA_ "GenMsgNrOfRepetition" BO_ 1949 0;
BA_ "GenMsgILSupport" BO_ 1949 0;
BA_ "GenMsgCycleTimeFast" BO_ 1949 0;
BA_ "GenMsgCycleTime" BO_ 1949 0;
BA_ "TpMessage" BO_ 1949 1;
BA_ "DiagResponse" BO_ 1949 1;
BA_ "GenMsgSendType" BO_ 952 0;
BA_ "GenMsgCycleTime" BO_ 1219 0;
BA_ "GenMsgSendType" BO_ 950 0;
BA_ "GenMsgSendType" BO_ 951 0;
BA_ "VFrameFormat" BO_ 2307024129 1;
BA_ "GenMsgNrOfRepetition" BO_ 2307024129 0;
BA_ "GenMsgCycleTimeFast" BO_ 2307024129 0;
BA_ "GenMsgSendType" BO_ 2307024129 0;
BA_ "VFrameFormat" BO_ 2176872449 1;
BA_ "GenMsgNrOfRepetition" BO_ 2176872449 0;
BA_ "GenMsgCycleTimeFast" BO_ 2176872449 0;
BA_ "GenMsgCycleTime" BO_ 2176872449 50;
BA_ "GenMsgSendType" BO_ 2176872449 0;
BA_ "GenMsgSendType" BO_ 1239 0;
BA_ "GenMsgSendType" BO_ 1240 0;
BA_ "VFrameFormat" BO_ 2214659330 1;
BA_ "GenMsgNrOfRepetition" BO_ 2214659330 0;
BA_ "GenMsgCycleTimeFast" BO_ 2214659330 0;
BA_ "GenMsgCycleTime" BO_ 2214659330 50;
BA_ "GenMsgSendType" BO_ 2214659330 0;
BA_ "GenMsgCycleTime" BO_ 171 0;
BA_ "VFrameFormat" BO_ 2164277249 1;
BA_ "GenMsgNrOfRepetition" BO_ 2164277249 0;
BA_ "GenMsgCycleTimeFast" BO_ 2164277249 0;
BA_ "GenMsgCycleTime" BO_ 2164277249 50;
BA_ "GenMsgSendType" BO_ 2164277249 0;
BA_ "VFrameFormat" BO_ 2172675329 1;
BA_ "GenMsgNrOfRepetition" BO_ 2172675329 0;
BA_ "GenMsgCycleTimeFast" BO_ 2172675329 0;
BA_ "GenMsgCycleTime" BO_ 2172675329 50;
BA_ "GenMsgSendType" BO_ 2172675329 0;
BA_ "GenMsgCycleTime" BO_ 172 0;
BA_ "GenMsgSendType" BO_ 799 0;
BA_ "VFrameFormat" BO_ 2227254529 1;
BA_ "GenMsgNrOfRepetition" BO_ 2227254529 0;
BA_ "GenMsgCycleTimeFast" BO_ 2227254529 0;
BA_ "GenMsgCycleTime" BO_ 2227254529 50;
BA_ "GenMsgSendType" BO_ 2227254529 0;
BA_ "GenMsgSendType" BO_ 912 0;
BA_ "GenMsgCycleTime" BO_ 1266 1000;
BA_ "GenMsgSendType" BO_ 1266 0;
BA_ "GenMsgSendType" BO_ 905 0;
BA_ "GenMsgCycleTime" BO_ 1264 1000;
BA_ "GenMsgSendType" BO_ 1264 0;
BA_ "GenMsgCycleTime" BO_ 1265 1000;
BA_ "GenMsgSendType" BO_ 1265 0;
BA_ "GenMsgCycleTime" BO_ 1278 2000;
BA_ "GenMsgSendType" BO_ 1278 0;
BA_ "VFrameFormat" BO_ 2256644609 1;
BA_ "GenMsgNrOfRepetition" BO_ 2256644609 0;
BA_ "GenMsgCycleTimeFast" BO_ 2256644609 0;
BA_ "GenMsgCycleTime" BO_ 2256644609 100;
BA_ "GenMsgSendType" BO_ 2256644609 0;
BA_ "GenMsgNrOfRepetition" BO_ 881 0;
BA_ "GenMsgCycleTimeFast" BO_ 881 0;
BA_ "GenMsgCycleTime" BO_ 881 1000;
BA_ "GenMsgSendType" BO_ 881 0;
BA_ "GenMsgNrOfRepetition" BO_ 1016 0;
BA_ "GenMsgCycleTimeFast" BO_ 1016 0;
BA_ "GenMsgCycleTime" BO_ 1016 1000;
BA_ "GenMsgSendType" BO_ 1016 0;
BA_ "GenMsgNrOfRepetition" BO_ 883 0;
BA_ "GenMsgCycleTimeFast" BO_ 883 0;
BA_ "GenMsgCycleTime" BO_ 883 1000;
BA_ "GenMsgSendType" BO_ 883 0;
BA_ "VFrameFormat" BO_ 2256644610 1;
BA_ "GenMsgNrOfRepetition" BO_ 2256644610 0;
BA_ "GenMsgCycleTimeFast" BO_ 2256644610 0;
BA_ "GenMsgCycleTime" BO_ 2256644610 100;
BA_ "GenMsgSendType" BO_ 2256644610 0;
BA_ "VFrameFormat" BO_ 2214658049 1;
BA_ "GenMsgNrOfRepetition" BO_ 2214658049 0;
BA_ "GenMsgCycleTimeFast" BO_ 2214658049 0;
BA_ "GenMsgCycleTime" BO_ 2214658049 50;
BA_ "GenMsgSendType" BO_ 2214658049 0;
BA_ "VFrameFormat" BO_ 2223056129 1;
BA_ "GenMsgNrOfRepetition" BO_ 2223056129 0;
BA_ "GenMsgCycleTimeFast" BO_ 2223056129 0;
BA_ "GenMsgCycleTime" BO_ 2223056129 50;
BA_ "GenMsgSendType" BO_ 2223056129 0;
BA_ "GenMsgNrOfRepetition" BO_ 884 0;
BA_ "GenMsgCycleTimeFast" BO_ 884 0;
BA_ "GenMsgCycleTime" BO_ 884 1000;
BA_ "GenMsgSendType" BO_ 884 0;
BA_ "NetworkRequestHoldingTime" SG_ 1941 GST_BLTN_CAM_Byte 5000;
BA_ "NetworkRequest" SG_ 1941 GST_BLTN_CAM_Byte 0;
BA_ "UsrSigPurpose" SG_ 1941 GST_BLTN_CAM_Byte 3;
BA_ "UserSigValidity" SG_ 1941 GST_BLTN_CAM_Byte 0;
BA_ "NetworkRequestHoldingTime" SG_ 2015 GST_ALL_Byte 5000;
BA_ "UsrSigPurpose" SG_ 2015 GST_ALL_Byte 0;
BA_ "UserSigValidity" SG_ 2015 GST_ALL_Byte 0;
BA_ "NetworkRequestHoldingTime" SG_ 1949 BLTN_CAM_GST_Byte 5000;
BA_ "UsrSigPurpose" SG_ 1949 BLTN_CAM_GST_Byte 4;
BA_ "UserSigValidity" SG_ 1949 BLTN_CAM_GST_Byte 0;
BA_ "Version" SG_ 952 BLTN_CAM_Set_FR_Ver_Pos "22.07.06";
BA_ "RoutingFactor" SG_ 952 BLTN_CAM_Set_FR_Ver_Pos 0;
BA_ "UserSigValidity" SG_ 952 BLTN_CAM_Set_FR_Ver_Pos 0;
BA_ "GenSigSendType" SG_ 952 BLTN_CAM_Set_FR_Ver_Pos 4;
BA_ "Description" SG_ 952 BLTN_CAM_Set_FR_Ver_Pos "Front Camera Vertical position setting value.";
BA_ "Version" SG_ 952 BLTN_CAM_Set_PEV_AppNoti "21.05.02";
BA_ "RoutingFactor" SG_ 952 BLTN_CAM_Set_PEV_AppNoti 0;
BA_ "UserSigValidity" SG_ 952 BLTN_CAM_Set_PEV_AppNoti 0;
BA_ "GenSigSendType" SG_ 952 BLTN_CAM_Set_PEV_AppNoti 4;
BA_ "Description" SG_ 952 BLTN_CAM_Set_PEV_AppNoti "Parked Event notification to Connectivity Phone App. On/Off";
BA_ "Version" SG_ 952 BLTN_CAM_Set_WiFi_AutoOn "21.05.02";
BA_ "RoutingFactor" SG_ 952 BLTN_CAM_Set_WiFi_AutoOn 0;
BA_ "UserSigValidity" SG_ 952 BLTN_CAM_Set_WiFi_AutoOn 0;
BA_ "GenSigSendType" SG_ 952 BLTN_CAM_Set_WiFi_AutoOn 4;
BA_ "Description" SG_ 952 BLTN_CAM_Set_WiFi_AutoOn "Wifi On/Off User setting";
BA_ "Version" SG_ 952 BLTN_CAM_StrgPropSet "21.05.02";
BA_ "RoutingFactor" SG_ 952 BLTN_CAM_StrgPropSet 0;
BA_ "UserSigValidity" SG_ 952 BLTN_CAM_StrgPropSet 0;
BA_ "GenSigSendType" SG_ 952 BLTN_CAM_StrgPropSet 4;
BA_ "Description" SG_ 952 BLTN_CAM_StrgPropSet "Propotion of built-in Cam SD card Propotion set of the Recording Categories";
BA_ "Version" SG_ 952 BLTN_CAM_File_DEL_CPY_Op_State "21.05.02";
BA_ "RoutingFactor" SG_ 952 BLTN_CAM_File_DEL_CPY_Op_State 0;
BA_ "UserSigValidity" SG_ 952 BLTN_CAM_File_DEL_CPY_Op_State 0;
BA_ "GenSigSendType" SG_ 952 BLTN_CAM_File_DEL_CPY_Op_State 4;
BA_ "Description" SG_ 952 BLTN_CAM_File_DEL_CPY_Op_State "Bulil in Cam Fily copy and delete operating state.";
BA_ "Version" SG_ 952 BLTN_CAM_File_DEL_CPY_NumTot "21.05.02";
BA_ "RoutingFactor" SG_ 952 BLTN_CAM_File_DEL_CPY_NumTot 0;
BA_ "UserSigValidity" SG_ 952 BLTN_CAM_File_DEL_CPY_NumTot 0;
BA_ "GenSigSendType" SG_ 952 BLTN_CAM_File_DEL_CPY_NumTot 4;
BA_ "Description" SG_ 952 BLTN_CAM_File_DEL_CPY_NumTot "Number of Copied or Deleted files.";
BA_ "Version" SG_ 952 BLTN_CAM_File_DEL_CPYed_Num "21.05.02";
BA_ "RoutingFactor" SG_ 952 BLTN_CAM_File_DEL_CPYed_Num 0;
BA_ "UserSigValidity" SG_ 952 BLTN_CAM_File_DEL_CPYed_Num 0;
BA_ "GenSigSendType" SG_ 952 BLTN_CAM_File_DEL_CPYed_Num 4;
BA_ "Description" SG_ 952 BLTN_CAM_File_DEL_CPYed_Num "Total number of the copy or delete file.";
BA_ "Version" SG_ 952 BLTN_CAM_Set_RR_Ver_Pos "22.07.06";
BA_ "RoutingFactor" SG_ 952 BLTN_CAM_Set_RR_Ver_Pos 0;
BA_ "UserSigValidity" SG_ 952 BLTN_CAM_Set_RR_Ver_Pos 0;
BA_ "GenSigSendType" SG_ 952 BLTN_CAM_Set_RR_Ver_Pos 4;
BA_ "Description" SG_ 952 BLTN_CAM_Set_RR_Ver_Pos "Rear Camera Vertical position setting value.";
BA_ "Version" SG_ 1219 BLTN_CAM_Rec_OWD_NvalueSet "21.05.02";
BA_ "UserSigValidity" SG_ 1219 BLTN_CAM_Rec_OWD_NvalueSet 0;
BA_ "GenSigSendType" SG_ 1219 BLTN_CAM_Rec_OWD_NvalueSet 4;
BA_ "Description" SG_ 1219 BLTN_CAM_Rec_OWD_NvalueSet "Record On/Off Set of On While Driving";
BA_ "Version" SG_ 1219 BLTN_CAM_Time_Stm_NvalueSet "21.05.02";
BA_ "UserSigValidity" SG_ 1219 BLTN_CAM_Time_Stm_NvalueSet 0;
BA_ "GenSigSendType" SG_ 1219 BLTN_CAM_Time_Stm_NvalueSet 4;
BA_ "Description" SG_ 1219 BLTN_CAM_Time_Stm_NvalueSet "Record Set of Date and Time Stamp";
BA_ "Version" SG_ 1219 BLTN_CAM_Spd_Stm_NvalueSet "21.11.07";
BA_ "UserSigValidity" SG_ 1219 BLTN_CAM_Spd_Stm_NvalueSet 0;
BA_ "GenSigSendType" SG_ 1219 BLTN_CAM_Spd_Stm_NvalueSet 4;
BA_ "Description" SG_ 1219 BLTN_CAM_Spd_Stm_NvalueSet "Record Set of Speed Stamp";
BA_ "Version" SG_ 1219 BLTN_CAM_Locatn_Stm_NvalueSet "21.05.02";
BA_ "UserSigValidity" SG_ 1219 BLTN_CAM_Locatn_Stm_NvalueSet 0;
BA_ "GenSigSendType" SG_ 1219 BLTN_CAM_Locatn_Stm_NvalueSet 4;
BA_ "Description" SG_ 1219 BLTN_CAM_Locatn_Stm_NvalueSet "Record Set of Location Stamp";
BA_ "Version" SG_ 1219 BLTN_CAM_TrnSig_Stm_NvalueSet "21.05.02";
BA_ "UserSigValidity" SG_ 1219 BLTN_CAM_TrnSig_Stm_NvalueSet 0;
BA_ "GenSigSendType" SG_ 1219 BLTN_CAM_TrnSig_Stm_NvalueSet 4;
BA_ "Description" SG_ 1219 BLTN_CAM_TrnSig_Stm_NvalueSet "Record Set of Turn Signal Stamp";
BA_ "Version" SG_ 1219 BLTN_CAM_AclBrk_Stm_NvalueSet "21.11.07";
BA_ "UserSigValidity" SG_ 1219 BLTN_CAM_AclBrk_Stm_NvalueSet 0;
BA_ "GenSigSendType" SG_ 1219 BLTN_CAM_AclBrk_Stm_NvalueSet 4;
BA_ "Description" SG_ 1219 BLTN_CAM_AclBrk_Stm_NvalueSet "Record Set of Accelerator Brake Stamp";
BA_ "Version" SG_ 1219 BLTN_CAM_Rec_DEV_NvalueSet "21.05.02";
BA_ "UserSigValidity" SG_ 1219 BLTN_CAM_Rec_DEV_NvalueSet 0;
BA_ "GenSigSendType" SG_ 1219 BLTN_CAM_Rec_DEV_NvalueSet 4;
BA_ "Description" SG_ 1219 BLTN_CAM_Rec_DEV_NvalueSet "Record On/Off Set of Driving Event";
BA_ "Version" SG_ 1219 BLTN_CAM_GearPos_Stm_NvalueSet "21.11.07";
BA_ "UserSigValidity" SG_ 1219 BLTN_CAM_GearPos_Stm_NvalueSet 0;
BA_ "GenSigSendType" SG_ 1219 BLTN_CAM_GearPos_Stm_NvalueSet 4;
BA_ "Description" SG_ 1219 BLTN_CAM_GearPos_Stm_NvalueSet "Record Set of Gear Position Stamp";
BA_ "Version" SG_ 1219 BLTN_CAM_EVSen_Stm_NvalueSet "21.05.02";
BA_ "UserSigValidity" SG_ 1219 BLTN_CAM_EVSen_Stm_NvalueSet 0;
BA_ "GenSigSendType" SG_ 1219 BLTN_CAM_EVSen_Stm_NvalueSet 4;
BA_ "Description" SG_ 1219 BLTN_CAM_EVSen_Stm_NvalueSet "Record Set of Event Sensitivity Stamp";
BA_ "Version" SG_ 1219 BLTN_CAM_Strangl_Stm_NvalueSet "21.07.05";
BA_ "UserSigValidity" SG_ 1219 BLTN_CAM_Strangl_Stm_NvalueSet 0;
BA_ "GenSigSendType" SG_ 1219 BLTN_CAM_Strangl_Stm_NvalueSet 4;
BA_ "Description" SG_ 1219 BLTN_CAM_Strangl_Stm_NvalueSet "Record Set of Steering Angle Stamp";
BA_ "Version" SG_ 1219 BLTN_CAM_EV_RecMaxTime_NvalueSet "23.02.02";
BA_ "UserSigValidity" SG_ 1219 BLTN_CAM_EV_RecMaxTime_NvalueSet 0;
BA_ "GenSigSendType" SG_ 1219 BLTN_CAM_EV_RecMaxTime_NvalueSet 4;
BA_ "Description" SG_ 1219 BLTN_CAM_EV_RecMaxTime_NvalueSet "BLTN_CAM EV Parking Rec Max Time NvalueSet";
BA_ "Version" SG_ 1219 BLTN_CAM_PrkTime_NvalueSet "21.11.07";
BA_ "UserSigValidity" SG_ 1219 BLTN_CAM_PrkTime_NvalueSet 0;
BA_ "GenSigSendType" SG_ 1219 BLTN_CAM_PrkTime_NvalueSet 4;
BA_ "Description" SG_ 1219 BLTN_CAM_PrkTime_NvalueSet "Parking Operation Setting Time, Resolution : hr";
BA_ "Version" SG_ 1219 BLTN_CAM_EV_BfrTime_NvalueSet "23.04.02";
BA_ "UserSigValidity" SG_ 1219 BLTN_CAM_EV_BfrTime_NvalueSet 0;
BA_ "GenSigStartValue" SG_ 1219 BLTN_CAM_EV_BfrTime_NvalueSet 31;
BA_ "GenSigSendType" SG_ 1219 BLTN_CAM_EV_BfrTime_NvalueSet 4;
BA_ "Description" SG_ 1219 BLTN_CAM_EV_BfrTime_NvalueSet "Driving Event Time Setting - Before, Resolution : sec";
BA_ "Version" SG_ 1219 BLTN_CAM_Rec_OWP_NvalueSet "21.05.02";
BA_ "UserSigValidity" SG_ 1219 BLTN_CAM_Rec_OWP_NvalueSet 0;
BA_ "GenSigSendType" SG_ 1219 BLTN_CAM_Rec_OWP_NvalueSet 4;
BA_ "Description" SG_ 1219 BLTN_CAM_Rec_OWP_NvalueSet "Record On/Off Set of On While Parked, 0x0(Default) : Parking recording function not supported";
BA_ "Version" SG_ 1219 BLTN_CAM_EV_AftTime_NvalueSet "23.04.02";
BA_ "UserSigValidity" SG_ 1219 BLTN_CAM_EV_AftTime_NvalueSet 0;
BA_ "GenSigStartValue" SG_ 1219 BLTN_CAM_EV_AftTime_NvalueSet 31;
BA_ "GenSigSendType" SG_ 1219 BLTN_CAM_EV_AftTime_NvalueSet 4;
BA_ "Description" SG_ 1219 BLTN_CAM_EV_AftTime_NvalueSet "Driving Event Time Setting - After, Resolution : sec";
BA_ "Version" SG_ 1219 BLTN_CAM_TML_Int_NvalueSet "21.05.02";
BA_ "UserSigValidity" SG_ 1219 BLTN_CAM_TML_Int_NvalueSet 0;
BA_ "GenSigSendType" SG_ 1219 BLTN_CAM_TML_Int_NvalueSet 4;
BA_ "Description" SG_ 1219 BLTN_CAM_TML_Int_NvalueSet "Record Set of Time-lapse Interval, Resolution : sec";
BA_ "Version" SG_ 1219 BLTN_CAM_Sen_DEV_NvalueSet "21.05.02";
BA_ "UserSigValidity" SG_ 1219 BLTN_CAM_Sen_DEV_NvalueSet 0;
BA_ "GenSigSendType" SG_ 1219 BLTN_CAM_Sen_DEV_NvalueSet 4;
BA_ "Description" SG_ 1219 BLTN_CAM_Sen_DEV_NvalueSet "Set of Event  Detection Sensitivity of Driving Mode";
BA_ "Version" SG_ 1219 BLTN_CAM_Sen_PEV_NvalueSet "21.05.02";
BA_ "UserSigValidity" SG_ 1219 BLTN_CAM_Sen_PEV_NvalueSet 0;
BA_ "GenSigSendType" SG_ 1219 BLTN_CAM_Sen_PEV_NvalueSet 4;
BA_ "Description" SG_ 1219 BLTN_CAM_Sen_PEV_NvalueSet "Set of Event  Detection Sensitivity of Parking Mode";
BA_ "Version" SG_ 1219 BLTN_CAM_Rec_PEV_NvalueSet "21.05.02";
BA_ "UserSigValidity" SG_ 1219 BLTN_CAM_Rec_PEV_NvalueSet 0;
BA_ "GenSigSendType" SG_ 1219 BLTN_CAM_Rec_PEV_NvalueSet 4;
BA_ "Description" SG_ 1219 BLTN_CAM_Rec_PEV_NvalueSet "Record Set of Parked Event, 0x0(Default) : Parking recording function not supported";
BA_ "Version" SG_ 1219 BLTN_CAM_AudRec_NvalueSet "21.06.10";
BA_ "UserSigValidity" SG_ 1219 BLTN_CAM_AudRec_NvalueSet 0;
BA_ "GenSigSendType" SG_ 1219 BLTN_CAM_AudRec_NvalueSet 4;
BA_ "Description" SG_ 1219 BLTN_CAM_AudRec_NvalueSet "Audio Record On/Off Set";
BA_ "Version" SG_ 950 BLTN_CAM_State "21.05.02";
BA_ "RoutingFactor" SG_ 950 BLTN_CAM_State 0;
BA_ "UserSigValidity" SG_ 950 BLTN_CAM_State 1;
BA_ "GenSigSendType" SG_ 950 BLTN_CAM_State 4;
BA_ "UsrSigPurpose" SG_ 950 BLTN_CAM_State 0;
BA_ "Description" SG_ 950 BLTN_CAM_State "This Signal is for cluster warning popup.";
BA_ "Version" SG_ 950 BLTN_CAM_RecSta_DEV "21.05.02";
BA_ "RoutingFactor" SG_ 950 BLTN_CAM_RecSta_DEV 0;
BA_ "UserSigValidity" SG_ 950 BLTN_CAM_RecSta_DEV 1;
BA_ "GenSigSendType" SG_ 950 BLTN_CAM_RecSta_DEV 4;
BA_ "UsrSigPurpose" SG_ 950 BLTN_CAM_RecSta_DEV 0;
BA_ "Description" SG_ 950 BLTN_CAM_RecSta_DEV "This Signal inform recording status of Driving Event.";
BA_ "Version" SG_ 950 BLTN_CAM_RecSta_MAR "21.05.02";
BA_ "RoutingFactor" SG_ 950 BLTN_CAM_RecSta_MAR 0;
BA_ "UserSigValidity" SG_ 950 BLTN_CAM_RecSta_MAR 1;
BA_ "GenSigSendType" SG_ 950 BLTN_CAM_RecSta_MAR 4;
BA_ "UsrSigPurpose" SG_ 950 BLTN_CAM_RecSta_MAR 0;
BA_ "Description" SG_ 950 BLTN_CAM_RecSta_MAR "This Signal inform recording status of Manual Recording.";
BA_ "Version" SG_ 950 BLTN_CAM_RecSta_TML "21.05.02";
BA_ "RoutingFactor" SG_ 950 BLTN_CAM_RecSta_TML 0;
BA_ "UserSigValidity" SG_ 950 BLTN_CAM_RecSta_TML 1;
BA_ "GenSigSendType" SG_ 950 BLTN_CAM_RecSta_TML 4;
BA_ "UsrSigPurpose" SG_ 950 BLTN_CAM_RecSta_TML 0;
BA_ "Description" SG_ 950 BLTN_CAM_RecSta_TML "This Signal inform recording status of Time-lapse.";
BA_ "Version" SG_ 950 BLTN_CAM_RecSta_OWP "21.05.02";
BA_ "RoutingFactor" SG_ 950 BLTN_CAM_RecSta_OWP 0;
BA_ "UserSigValidity" SG_ 950 BLTN_CAM_RecSta_OWP 1;
BA_ "GenSigSendType" SG_ 950 BLTN_CAM_RecSta_OWP 4;
BA_ "UsrSigPurpose" SG_ 950 BLTN_CAM_RecSta_OWP 0;
BA_ "Description" SG_ 950 BLTN_CAM_RecSta_OWP "This Signal inform recording status of On While Parked.";
BA_ "Version" SG_ 950 BLTN_CAM_RecSta_PEV "21.05.02";
BA_ "RoutingFactor" SG_ 950 BLTN_CAM_RecSta_PEV 0;
BA_ "UserSigValidity" SG_ 950 BLTN_CAM_RecSta_PEV 1;
BA_ "GenSigSendType" SG_ 950 BLTN_CAM_RecSta_PEV 4;
BA_ "UsrSigPurpose" SG_ 950 BLTN_CAM_RecSta_PEV 0;
BA_ "Description" SG_ 950 BLTN_CAM_RecSta_PEV "This Signal inform recording status of Parked Event.";
BA_ "Version" SG_ 950 BLTN_CAM_Prk_EV_Cnt "21.05.02";
BA_ "RoutingFactor" SG_ 950 BLTN_CAM_Prk_EV_Cnt 0;
BA_ "UserSigValidity" SG_ 950 BLTN_CAM_Prk_EV_Cnt 1;
BA_ "GenSigSendType" SG_ 950 BLTN_CAM_Prk_EV_Cnt 4;
BA_ "UsrSigPurpose" SG_ 950 BLTN_CAM_Prk_EV_Cnt 0;
BA_ "Description" SG_ 950 BLTN_CAM_Prk_EV_Cnt "The count number of a parked Event.";
BA_ "Version" SG_ 950 BLTN_CAM_Prk_Oped_Time "22.07.05";
BA_ "RoutingFactor" SG_ 950 BLTN_CAM_Prk_Oped_Time 0;
BA_ "UserSigValidity" SG_ 950 BLTN_CAM_Prk_Oped_Time 1;
BA_ "GenSigSendType" SG_ 950 BLTN_CAM_Prk_Oped_Time 4;
BA_ "UsrSigPurpose" SG_ 950 BLTN_CAM_Prk_Oped_Time 0;
BA_ "Description" SG_ 950 BLTN_CAM_Prk_Oped_Time "The Parked Opreated time ingormation";
BA_ "Version" SG_ 950 BLTN_CAM_Prk_Oprable_Time "22.07.05";
BA_ "RoutingFactor" SG_ 950 BLTN_CAM_Prk_Oprable_Time 0;
BA_ "UserSigValidity" SG_ 950 BLTN_CAM_Prk_Oprable_Time 1;
BA_ "GenSigSendType" SG_ 950 BLTN_CAM_Prk_Oprable_Time 4;
BA_ "UsrSigPurpose" SG_ 950 BLTN_CAM_Prk_Oprable_Time 0;
BA_ "Description" SG_ 950 BLTN_CAM_Prk_Oprable_Time "The hours of Park Mode Operatable, the time is limited by user max oper. Set.";
BA_ "Version" SG_ 950 BLTN_CAM_SD_Card_State "22.05.02";
BA_ "RoutingFactor" SG_ 950 BLTN_CAM_SD_Card_State 0;
BA_ "NetworkRequestHoldingTime" SG_ 950 BLTN_CAM_SD_Card_State 1000;
BA_ "NetworkRequest" SG_ 950 BLTN_CAM_SD_Card_State 0;
BA_ "UserSigValidity" SG_ 950 BLTN_CAM_SD_Card_State 0;
BA_ "GenSigSendType" SG_ 950 BLTN_CAM_SD_Card_State 4;
BA_ "UsrSigPurpose" SG_ 950 BLTN_CAM_SD_Card_State 0;
BA_ "Description" SG_ 950 BLTN_CAM_SD_Card_State "This Signal is for SD card Status in Built-in App menu and CCS Phone App.";
BA_ "Version" SG_ 950 BLTN_CAM_Prk_Oprable_Time_Max "22.07.05";
BA_ "RoutingFactor" SG_ 950 BLTN_CAM_Prk_Oprable_Time_Max 0;
BA_ "UserSigValidity" SG_ 950 BLTN_CAM_Prk_Oprable_Time_Max 1;
BA_ "GenSigSendType" SG_ 950 BLTN_CAM_Prk_Oprable_Time_Max 4;
BA_ "UsrSigPurpose" SG_ 950 BLTN_CAM_Prk_Oprable_Time_Max 0;
BA_ "Description" SG_ 950 BLTN_CAM_Prk_Oprable_Time_Max "The hours of Park Mode Operatable, the time has no limit.";
BA_ "Version" SG_ 950 BLTN_CAM_AuxBat_Conn_State "21.07.04";
BA_ "RoutingFactor" SG_ 950 BLTN_CAM_AuxBat_Conn_State 0;
BA_ "UserSigValidity" SG_ 950 BLTN_CAM_AuxBat_Conn_State 0;
BA_ "GenSigSendType" SG_ 950 BLTN_CAM_AuxBat_Conn_State 4;
BA_ "UsrSigPurpose" SG_ 950 BLTN_CAM_AuxBat_Conn_State 0;
BA_ "Description" SG_ 950 BLTN_CAM_AuxBat_Conn_State "The auxiliary Battery conntction information.";
BA_ "Version" SG_ 950 BLTN_CAM_AuxBat_CapPer "21.05.02";
BA_ "RoutingFactor" SG_ 950 BLTN_CAM_AuxBat_CapPer 0;
BA_ "UserSigValidity" SG_ 950 BLTN_CAM_AuxBat_CapPer 1;
BA_ "GenSigSendType" SG_ 950 BLTN_CAM_AuxBat_CapPer 4;
BA_ "UsrSigPurpose" SG_ 950 BLTN_CAM_AuxBat_CapPer 0;
BA_ "Description" SG_ 950 BLTN_CAM_AuxBat_CapPer "The percentage of Aux. Bat.";
BA_ "Version" SG_ 950 BLTN_CAM_RecSta_OWD "21.05.02";
BA_ "RoutingFactor" SG_ 950 BLTN_CAM_RecSta_OWD 0;
BA_ "UserSigValidity" SG_ 950 BLTN_CAM_RecSta_OWD 1;
BA_ "GenSigSendType" SG_ 950 BLTN_CAM_RecSta_OWD 4;
BA_ "UsrSigPurpose" SG_ 950 BLTN_CAM_RecSta_OWD 0;
BA_ "Description" SG_ 950 BLTN_CAM_RecSta_OWD "This Signal inform recording status of On While Driving.";
BA_ "Version" SG_ 951 BLTN_CAM_RecSet_OWD "21.05.02";
BA_ "UserSigValidity" SG_ 951 BLTN_CAM_RecSet_OWD 0;
BA_ "GenSigSendType" SG_ 951 BLTN_CAM_RecSet_OWD 4;
BA_ "Description" SG_ 951 BLTN_CAM_RecSet_OWD "Record On/Off Set of On While Driving";
BA_ "Version" SG_ 951 BLTN_CAM_Set_Tim_Stm "21.05.02";
BA_ "UserSigValidity" SG_ 951 BLTN_CAM_Set_Tim_Stm 0;
BA_ "GenSigSendType" SG_ 951 BLTN_CAM_Set_Tim_Stm 4;
BA_ "Description" SG_ 951 BLTN_CAM_Set_Tim_Stm "Record Set of Date and Time Stamp";
BA_ "Version" SG_ 951 BLTN_CAM_Set_Spd_Stm "21.11.07";
BA_ "UserSigValidity" SG_ 951 BLTN_CAM_Set_Spd_Stm 0;
BA_ "GenSigSendType" SG_ 951 BLTN_CAM_Set_Spd_Stm 4;
BA_ "Description" SG_ 951 BLTN_CAM_Set_Spd_Stm "Record Set of Speed Stamp";
BA_ "Version" SG_ 951 BLTN_CAM_Set_Locatn_Stm "21.05.02";
BA_ "UserSigValidity" SG_ 951 BLTN_CAM_Set_Locatn_Stm 0;
BA_ "GenSigSendType" SG_ 951 BLTN_CAM_Set_Locatn_Stm 4;
BA_ "Description" SG_ 951 BLTN_CAM_Set_Locatn_Stm "Record Set of Location Stamp";
BA_ "Version" SG_ 951 BLTN_CAM_Set_TrnSig_Stm "21.05.02";
BA_ "UserSigValidity" SG_ 951 BLTN_CAM_Set_TrnSig_Stm 0;
BA_ "GenSigSendType" SG_ 951 BLTN_CAM_Set_TrnSig_Stm 4;
BA_ "Description" SG_ 951 BLTN_CAM_Set_TrnSig_Stm "Record Set of Turn Signal Stamp";
BA_ "Version" SG_ 951 BLTN_CAM_Set_AclBrk_Stm "21.11.07";
BA_ "UserSigValidity" SG_ 951 BLTN_CAM_Set_AclBrk_Stm 0;
BA_ "GenSigSendType" SG_ 951 BLTN_CAM_Set_AclBrk_Stm 4;
BA_ "Description" SG_ 951 BLTN_CAM_Set_AclBrk_Stm "Record Set of Accelerator Brake Stamp";
BA_ "Version" SG_ 951 BLTN_CAM_RecSet_DEV "21.05.02";
BA_ "UserSigValidity" SG_ 951 BLTN_CAM_RecSet_DEV 0;
BA_ "GenSigSendType" SG_ 951 BLTN_CAM_RecSet_DEV 4;
BA_ "Description" SG_ 951 BLTN_CAM_RecSet_DEV "Record On/Off Set of Driving Event";
BA_ "Version" SG_ 951 BLTN_CAM_Set_GearPos_Stm "21.05.02";
BA_ "UserSigValidity" SG_ 951 BLTN_CAM_Set_GearPos_Stm 0;
BA_ "GenSigSendType" SG_ 951 BLTN_CAM_Set_GearPos_Stm 4;
BA_ "Description" SG_ 951 BLTN_CAM_Set_GearPos_Stm "Record Set of Gear Position Stamp";
BA_ "Version" SG_ 951 BLTN_CAM_Set_EVSen_Stm "21.05.02";
BA_ "UserSigValidity" SG_ 951 BLTN_CAM_Set_EVSen_Stm 0;
BA_ "GenSigSendType" SG_ 951 BLTN_CAM_Set_EVSen_Stm 4;
BA_ "Description" SG_ 951 BLTN_CAM_Set_EVSen_Stm "Record Set of Event Sensitivity Stamp";
BA_ "Version" SG_ 951 BLTN_CAM_Set_StrAngl_Stm "21.07.05";
BA_ "UserSigValidity" SG_ 951 BLTN_CAM_Set_StrAngl_Stm 0;
BA_ "GenSigSendType" SG_ 951 BLTN_CAM_Set_StrAngl_Stm 4;
BA_ "Description" SG_ 951 BLTN_CAM_Set_StrAngl_Stm "Record Set of Steering Angle Stamp";
BA_ "Version" SG_ 951 BLTN_CAM_Set_EV_RecMaxTime "23.02.02";
BA_ "UserSigValidity" SG_ 951 BLTN_CAM_Set_EV_RecMaxTime 0;
BA_ "GenSigSendType" SG_ 951 BLTN_CAM_Set_EV_RecMaxTime 4;
BA_ "Description" SG_ 951 BLTN_CAM_Set_EV_RecMaxTime "BLTN_CAM Set EV Parking Rec Max Time";
BA_ "Version" SG_ 951 BLTN_CAM_Set_PrkTime "21.11.07";
BA_ "UserSigValidity" SG_ 951 BLTN_CAM_Set_PrkTime 0;
BA_ "GenSigSendType" SG_ 951 BLTN_CAM_Set_PrkTime 4;
BA_ "Description" SG_ 951 BLTN_CAM_Set_PrkTime "Parking Operation Setting Time, Resolution : hr";
BA_ "Version" SG_ 951 BLTN_CAM_Set_EV_BfrTime "21.05.02";
BA_ "UserSigValidity" SG_ 951 BLTN_CAM_Set_EV_BfrTime 0;
BA_ "GenSigSendType" SG_ 951 BLTN_CAM_Set_EV_BfrTime 4;
BA_ "Description" SG_ 951 BLTN_CAM_Set_EV_BfrTime "Driving Event Time Setting - Before, Resolution : sec";
BA_ "Version" SG_ 951 BLTN_CAM_RecSet_OWP "21.05.02";
BA_ "UserSigValidity" SG_ 951 BLTN_CAM_RecSet_OWP 0;
BA_ "GenSigSendType" SG_ 951 BLTN_CAM_RecSet_OWP 4;
BA_ "Description" SG_ 951 BLTN_CAM_RecSet_OWP "Record On/Off Set of On While Parked, 0x0(Default) : Parking recording function not supported";
BA_ "Version" SG_ 951 BLTN_CAM_Set_EV_AftTime "21.05.02";
BA_ "UserSigValidity" SG_ 951 BLTN_CAM_Set_EV_AftTime 0;
BA_ "GenSigSendType" SG_ 951 BLTN_CAM_Set_EV_AftTime 4;
BA_ "Description" SG_ 951 BLTN_CAM_Set_EV_AftTime "Driving Event Time Setting - After, Resolution : sec";
BA_ "Version" SG_ 951 BLTN_CAM_Set_Drv_TML_Int "21.05.02";
BA_ "UserSigValidity" SG_ 951 BLTN_CAM_Set_Drv_TML_Int 0;
BA_ "GenSigSendType" SG_ 951 BLTN_CAM_Set_Drv_TML_Int 4;
BA_ "Description" SG_ 951 BLTN_CAM_Set_Drv_TML_Int "Record Set of Time-lapse Interval, Resolution : sec";
BA_ "Version" SG_ 951 BLTN_CAM_SenSet_DEV "21.05.02";
BA_ "UserSigValidity" SG_ 951 BLTN_CAM_SenSet_DEV 0;
BA_ "GenSigSendType" SG_ 951 BLTN_CAM_SenSet_DEV 4;
BA_ "Description" SG_ 951 BLTN_CAM_SenSet_DEV "Set of Event  Detection Sensitivity of Driving Mode";
BA_ "Version" SG_ 951 BLTN_CAM_SenSet_PEV "21.05.02";
BA_ "UserSigValidity" SG_ 951 BLTN_CAM_SenSet_PEV 0;
BA_ "GenSigSendType" SG_ 951 BLTN_CAM_SenSet_PEV 4;
BA_ "Description" SG_ 951 BLTN_CAM_SenSet_PEV "Set of Event  Detection Sensitivity of Parking Mode";
BA_ "Version" SG_ 951 BLTN_CAM_RecSet_PEV "21.05.02";
BA_ "UserSigValidity" SG_ 951 BLTN_CAM_RecSet_PEV 0;
BA_ "GenSigSendType" SG_ 951 BLTN_CAM_RecSet_PEV 4;
BA_ "Description" SG_ 951 BLTN_CAM_RecSet_PEV "Record Set of Parked Event, 0x0(Default) : Parking recording function not supported";
BA_ "Version" SG_ 951 BLTN_CAM_AudRec_Set "21.05.02";
BA_ "UserSigValidity" SG_ 951 BLTN_CAM_AudRec_Set 0;
BA_ "GenSigSendType" SG_ 951 BLTN_CAM_AudRec_Set 4;
BA_ "Description" SG_ 951 BLTN_CAM_AudRec_Set "Audio Record On/Off Set";
BA_ "Version" SG_ 2307024129 HEV_BrkLtSwSta "17.11.00";
BA_ "RoutingFactor" SG_ 2307024129 HEV_BrkLtSwSta 2;
BA_ "UserSigValidity" SG_ 2307024129 HEV_BrkLtSwSta 3;
BA_ "Description" SG_ 2307024129 HEV_BrkLtSwSta "Brake light Switch";
BA_ "Version" SG_ 2176872449 HDCT_GearSelDis "19.10.01";
BA_ "RoutingFactor" SG_ 2176872449 HDCT_GearSelDis 5;
BA_ "UserSigValidity" SG_ 2176872449 HDCT_GearSelDis 3;
BA_ "GenSigStartValue" SG_ 2176872449 HDCT_GearSelDis 9;
BA_ "Description" SG_ 2176872449 HDCT_GearSelDis "Position (P, R, N..), which was identified by the gear selector.

In case the gear selector is in a intermediate position, the last clear recognized position is used.

There is no specific phase relationship between the output and any other signal.";
BA_ "Version" SG_ 1239 HU_PwrState "22.05.02";
BA_ "UserSigValidity" SG_ 1239 HU_PwrState 0;
BA_ "GenSigSendType" SG_ 1239 HU_PwrState 4;
BA_ "Description" SG_ 1239 HU_PwrState "Information for the H/U power status



* Do not use HU_VehiclePwr (@HU_Car_PE_01) in new ECU or Logic related with HU power state";
BA_ "Version" SG_ 1239 HU_VehiclePwr "22.05.02";
BA_ "NetworkRequestHoldingTime" SG_ 1239 HU_VehiclePwr 5000;
BA_ "NetworkRequest" SG_ 1239 HU_VehiclePwr 0;
BA_ "UserSigValidity" SG_ 1239 HU_VehiclePwr 0;
BA_ "GenSigSendType" SG_ 1239 HU_VehiclePwr 4;
BA_ "Description" SG_ 1239 HU_VehiclePwr "* Use HU_PwrState (@HU_Car_PE_01) in new ECU or Logic related with HU power state";
BA_ "Version" SG_ 1240 HU_ThemeType "22.06.01";
BA_ "UserSigValidity" SG_ 1240 HU_ThemeType 0;
BA_ "GenSigStartValue" SG_ 1240 HU_ThemeType 15;
BA_ "GenSigSendType" SG_ 1240 HU_ThemeType 4;
BA_ "Description" SG_ 1240 HU_ThemeType "This signal indicates current H/Unit GUI theme value. 

 

Detail value -GUI Theme matching table, refer to attachement and ES SPEC";
BA_ "Version" SG_ 1240 CF_AVN_ProfileIDRValue "22.11.24";
BA_ "UserSigValidity" SG_ 1240 CF_AVN_ProfileIDRValue 0;
BA_ "GenSigStartValue" SG_ 1240 CF_AVN_ProfileIDRValue 15;
BA_ "GenSigSendType" SG_ 1240 CF_AVN_ProfileIDRValue 4;
BA_ "Description" SG_ 1240 CF_AVN_ProfileIDRValue "Profile 3~Profile9 value is only used from Vehicle Architecture 2.0 (STD_DB_CAR_R2, SV 24.6~) vehicle models

Vehicle Architecture 1.0 (STD_DB_CAR) vehicle models can use Guest, Profile1, Profile 2 only.";
BA_ "Version" SG_ 2214659330 HEV_AccelPdlVal "19.11.11";
BA_ "RoutingFactor" SG_ 2214659330 HEV_AccelPdlVal 5;
BA_ "UserSigValidity" SG_ 2214659330 HEV_AccelPdlVal 3;
BA_ "Description" SG_ 2214659330 HEV_AccelPdlVal "The signal is a measure of the Accelerator Pedal value.

The accelerator pedal value is determined via 2 pedal sensors, which are connected mechanically to the accelerator pedal. If the EMS-ECU recognizes that the accelerator pedal is not activated, then";
BA_ "Version" SG_ 171 BLTN_CAM_UI_Mode_Tmt_Req "21.05.02";
BA_ "UserSigValidity" SG_ 171 BLTN_CAM_UI_Mode_Tmt_Req 1;
BA_ "GenSigSendType" SG_ 171 BLTN_CAM_UI_Mode_Tmt_Req 4;
BA_ "Description" SG_ 171 BLTN_CAM_UI_Mode_Tmt_Req "Built-in Cam UI Mode terminate request.";
BA_ "Version" SG_ 171 BLTN_CAM_Dis_Touch_BeepSound "21.09.05";
BA_ "UserSigValidity" SG_ 171 BLTN_CAM_Dis_Touch_BeepSound 1;
BA_ "GenSigSendType" SG_ 171 BLTN_CAM_Dis_Touch_BeepSound 4;
BA_ "Description" SG_ 171 BLTN_CAM_Dis_Touch_BeepSound "Display Touch Beep Sound of valid space touch.";
BA_ "Version" SG_ 171 BLTN_CAM_PopUp_Req "23.02.02";
BA_ "UserSigValidity" SG_ 171 BLTN_CAM_PopUp_Req 0;
BA_ "GenSigSendType" SG_ 171 BLTN_CAM_PopUp_Req 4;
BA_ "Description" SG_ 171 BLTN_CAM_PopUp_Req "Built-in Cam Operating and SD Card related Popup Request on HU Display.";
BA_ "Version" SG_ 171 BLTN_CAM_File_List_Renew "21.05.02";
BA_ "UserSigValidity" SG_ 171 BLTN_CAM_File_List_Renew 1;
BA_ "GenSigSendType" SG_ 171 BLTN_CAM_File_List_Renew 4;
BA_ "Description" SG_ 171 BLTN_CAM_File_List_Renew "The Storage information is renewed inform to HU.";
BA_ "Version" SG_ 171 BLTN_CAM_Wifi_Pwd_Chg_State "21.05.04";
BA_ "UserSigValidity" SG_ 171 BLTN_CAM_Wifi_Pwd_Chg_State 1;
BA_ "GenSigSendType" SG_ 171 BLTN_CAM_Wifi_Pwd_Chg_State 4;
BA_ "Description" SG_ 171 BLTN_CAM_Wifi_Pwd_Chg_State "The Response, when HU change Wifi Passowrd via SOME/IP";
BA_ "Version" SG_ 2164277249 TCU_GearSlctDis "17.11.00";
BA_ "RoutingFactor" SG_ 2164277249 TCU_GearSlctDis 5;
BA_ "UserSigValidity" SG_ 2164277249 TCU_GearSlctDis 3;
BA_ "GenSigStartValue" SG_ 2164277249 TCU_GearSlctDis 9;
BA_ "Description" SG_ 2164277249 TCU_GearSlctDis "Position (P, R, N..), which was identified by the gear selector.

In case the gear selector is in a intermediate position, the last clear recognized position is used.

There is no specific phase relationship between the output and any other signal.";
BA_ "Version" SG_ 2172675329 IEB_BrkActvSta "19.05.05";
BA_ "RoutingFactor" SG_ 2172675329 IEB_BrkActvSta 5;
BA_ "UserSigValidity" SG_ 2172675329 IEB_BrkActvSta 3;
BA_ "Description" SG_ 2172675329 IEB_BrkActvSta "This signal indicates that a brake switch is activated or not. When the brake switch is activated(pressed) its value is 02H otherwise its value is 01H.

If the ECU does not support this signal the value is 00H.



이 신호는 EV, FCEV 에서만 사용될 수 있음";
BA_ "Version" SG_ 172 BLTN_CAM_FR_VerPos_NvalueSet "23.04.02";
BA_ "UserSigValidity" SG_ 172 BLTN_CAM_FR_VerPos_NvalueSet 0;
BA_ "GenSigStartValue" SG_ 172 BLTN_CAM_FR_VerPos_NvalueSet 31;
BA_ "GenSigSendType" SG_ 172 BLTN_CAM_FR_VerPos_NvalueSet 4;
BA_ "Description" SG_ 172 BLTN_CAM_FR_VerPos_NvalueSet "Front Camera Vertical position setting value.";
BA_ "Version" SG_ 172 BLTN_CAM_AppNoti_PEV_NvalueSet "21.05.02";
BA_ "UserSigValidity" SG_ 172 BLTN_CAM_AppNoti_PEV_NvalueSet 0;
BA_ "GenSigSendType" SG_ 172 BLTN_CAM_AppNoti_PEV_NvalueSet 4;
BA_ "Description" SG_ 172 BLTN_CAM_AppNoti_PEV_NvalueSet "Parked Event notification to Connectivity Phone App. On/Off";
BA_ "Version" SG_ 172 BLTN_CAM_WiFi_AutoOn_NvalueSet "21.05.02";
BA_ "UserSigValidity" SG_ 172 BLTN_CAM_WiFi_AutoOn_NvalueSet 0;
BA_ "GenSigSendType" SG_ 172 BLTN_CAM_WiFi_AutoOn_NvalueSet 4;
BA_ "Description" SG_ 172 BLTN_CAM_WiFi_AutoOn_NvalueSet "Wifi On/Off User setting";
BA_ "Version" SG_ 172 BLTN_CAM_StoProp_NvalueSet "21.05.02";
BA_ "UserSigValidity" SG_ 172 BLTN_CAM_StoProp_NvalueSet 0;
BA_ "GenSigSendType" SG_ 172 BLTN_CAM_StoProp_NvalueSet 4;
BA_ "Description" SG_ 172 BLTN_CAM_StoProp_NvalueSet "Propotion of built-in Cam SD card Propotion set of the Recording Categories";
BA_ "Version" SG_ 172 CF_AVN_BLTN_CAM_USMReset "21.05.02";
BA_ "UserSigValidity" SG_ 172 CF_AVN_BLTN_CAM_USMReset 0;
BA_ "GenSigSendType" SG_ 172 CF_AVN_BLTN_CAM_USMReset 4;
BA_ "Description" SG_ 172 CF_AVN_BLTN_CAM_USMReset "Buit-in Cam USM Reset Request.";
BA_ "Version" SG_ 172 CF_AVN_BLTN_CAM_RecReset "21.05.02";
BA_ "UserSigValidity" SG_ 172 CF_AVN_BLTN_CAM_RecReset 0;
BA_ "GenSigSendType" SG_ 172 CF_AVN_BLTN_CAM_RecReset 4;
BA_ "Description" SG_ 172 CF_AVN_BLTN_CAM_RecReset "Buit-in Cam format(all file delete/Reset) Request.";
BA_ "Version" SG_ 172 BLTN_CAM_File_DEL_CPY_Cmd "21.05.02";
BA_ "UserSigValidity" SG_ 172 BLTN_CAM_File_DEL_CPY_Cmd 0;
BA_ "GenSigSendType" SG_ 172 BLTN_CAM_File_DEL_CPY_Cmd 4;
BA_ "Description" SG_ 172 BLTN_CAM_File_DEL_CPY_Cmd "Buit-in Cam operation control of copying and deleting.";
BA_ "Version" SG_ 172 BLTN_CAM_LVDS_Mode_Cmd "21.05.02";
BA_ "UserSigValidity" SG_ 172 BLTN_CAM_LVDS_Mode_Cmd 0;
BA_ "GenSigSendType" SG_ 172 BLTN_CAM_LVDS_Mode_Cmd 4;
BA_ "Description" SG_ 172 BLTN_CAM_LVDS_Mode_Cmd "This Signal is for LVDS output commend to BLTN_CAM";
BA_ "Version" SG_ 172 HU_BLTN_CAM_Disp_Touch_Pos_X "21.05.02";
BA_ "UserSigValidity" SG_ 172 HU_BLTN_CAM_Disp_Touch_Pos_X 0;
BA_ "GenSigSendType" SG_ 172 HU_BLTN_CAM_Disp_Touch_Pos_X 4;
BA_ "Description" SG_ 172 HU_BLTN_CAM_Disp_Touch_Pos_X "X position of touch of display when BLTN-in CAM Engineer mode in";
BA_ "Version" SG_ 172 HU_BLTN_CAM_Disp_Touch_Pos_Y "21.05.02";
BA_ "UserSigValidity" SG_ 172 HU_BLTN_CAM_Disp_Touch_Pos_Y 0;
BA_ "GenSigSendType" SG_ 172 HU_BLTN_CAM_Disp_Touch_Pos_Y 4;
BA_ "Description" SG_ 172 HU_BLTN_CAM_Disp_Touch_Pos_Y "Y position of touch of display when BLTN-in CAM Engineer mode in";
BA_ "Version" SG_ 172 MEV_Rec_Req "22.04.02";
BA_ "UserSigValidity" SG_ 172 MEV_Rec_Req 0;
BA_ "GenSigSendType" SG_ 172 MEV_Rec_Req 4;
BA_ "Description" SG_ 172 MEV_Rec_Req "HU → BLTN_CAM Manual Event Record request.";
BA_ "Version" SG_ 172 BLTN_CAM_RR_VerPos_NvalueSet "23.04.02";
BA_ "UserSigValidity" SG_ 172 BLTN_CAM_RR_VerPos_NvalueSet 0;
BA_ "GenSigStartValue" SG_ 172 BLTN_CAM_RR_VerPos_NvalueSet 31;
BA_ "GenSigSendType" SG_ 172 BLTN_CAM_RR_VerPos_NvalueSet 4;
BA_ "Description" SG_ 172 BLTN_CAM_RR_VerPos_NvalueSet "Rear Camera Vertical position setting value.";
BA_ "Version" SG_ 172 TML_Rec_Req "22.04.02";
BA_ "UserSigValidity" SG_ 172 TML_Rec_Req 0;
BA_ "GenSigSendType" SG_ 172 TML_Rec_Req 4;
BA_ "Description" SG_ 172 TML_Rec_Req "HU → BLTN_CAM Time lapse Start and End Request.";
BA_ "Version" SG_ 172 BLTN_CAM_SD_Card_UnMt_Mt_Req "22.05.02";
BA_ "UserSigValidity" SG_ 172 BLTN_CAM_SD_Card_UnMt_Mt_Req 0;
BA_ "GenSigSendType" SG_ 172 BLTN_CAM_SD_Card_UnMt_Mt_Req 4;
BA_ "Description" SG_ 172 BLTN_CAM_SD_Card_UnMt_Mt_Req "Built-in Cam Unmount and Mount Request.";
BA_ "Version" SG_ 799 DRV_CrashUnlockCmd "21.07.07";
BA_ "NetworkRequest" SG_ 799 DRV_CrashUnlockCmd 0;
BA_ "UserSigValidity" SG_ 799 DRV_CrashUnlockCmd 0;
BA_ "GenSigSendType" SG_ 799 DRV_CrashUnlockCmd 4;
BA_ "Description" SG_ 799 DRV_CrashUnlockCmd "Drive Crash Unlock Command";
BA_ "Version" SG_ 799 Warn_DrvDrSwSta_SBCM "21.09.05";
BA_ "NetworkRequest" SG_ 799 Warn_DrvDrSwSta_SBCM 0;
BA_ "UserSigValidity" SG_ 799 Warn_DrvDrSwSta_SBCM 0;
BA_ "GenSigSendType" SG_ 799 Warn_DrvDrSwSta_SBCM 4;
BA_ "Description" SG_ 799 Warn_DrvDrSwSta_SBCM "Warning Drive Door Switch State";
BA_ "Version" SG_ 2227254529 BAT_SocVal "19.01.00";
BA_ "RoutingFactor" SG_ 2227254529 BAT_SocVal 5;
BA_ "UserSigValidity" SG_ 2227254529 BAT_SocVal 7;
BA_ "Description" SG_ 2227254529 BAT_SocVal "[For 12V Lithium Battery vehicle model]

This signal is battery State of Charge as calculated by battery sensor.";
BA_ "Version" SG_ 912 HU_BLTN_CAM_UI_Mode "22.07.05";
BA_ "RoutingFactor" SG_ 912 HU_BLTN_CAM_UI_Mode 0;
BA_ "UserSigValidity" SG_ 912 HU_BLTN_CAM_UI_Mode 0;
BA_ "GenSigSendType" SG_ 912 HU_BLTN_CAM_UI_Mode 4;
BA_ "Description" SG_ 912 HU_BLTN_CAM_UI_Mode "Display control of Built-in Cam UI mode. This Signal for Ethernet Type Built-in Cam.";
BA_ "Version" SG_ 912 HU_BLTN_CAM_Display "22.07.05";
BA_ "RoutingFactor" SG_ 912 HU_BLTN_CAM_Display 0;
BA_ "UserSigValidity" SG_ 912 HU_BLTN_CAM_Display 1;
BA_ "GenSigSendType" SG_ 912 HU_BLTN_CAM_Display 4;
BA_ "Description" SG_ 912 HU_BLTN_CAM_Display "Display control of Built-in Cam UI mode. This Signal for CAN Type Built-in Cam.(with Standard 5th Wide AVNT)";
BA_ "Version" SG_ 1266 HU_LanguageInfo "22.06.01";
BA_ "NetworkRequestHoldingTime" SG_ 1266 HU_LanguageInfo 5000;
BA_ "NetworkRequest" SG_ 1266 HU_LanguageInfo 0;
BA_ "UserSigValidity" SG_ 1266 HU_LanguageInfo 1;
BA_ "GenSigStartValue" SG_ 1266 HU_LanguageInfo 255;
BA_ "GenSigSendType" SG_ 1266 HU_LanguageInfo 4;
BA_ "Version" SG_ 905 RR_CrashUnlockCmd "21.07.07";
BA_ "NetworkRequest" SG_ 905 RR_CrashUnlockCmd 0;
BA_ "UserSigValidity" SG_ 905 RR_CrashUnlockCmd 0;
BA_ "GenSigSendType" SG_ 905 RR_CrashUnlockCmd 4;
BA_ "Description" SG_ 905 RR_CrashUnlockCmd "RearRightCrashUnlockCommand";
BA_ "Version" SG_ 905 Warn_RrRtDrSwSta_SBCM "21.09.05";
BA_ "NetworkRequest" SG_ 905 Warn_RrRtDrSwSta_SBCM 0;
BA_ "UserSigValidity" SG_ 905 Warn_RrRtDrSwSta_SBCM 0;
BA_ "GenSigSendType" SG_ 905 Warn_RrRtDrSwSta_SBCM 4;
BA_ "Description" SG_ 905 Warn_RrRtDrSwSta_SBCM "Warning Rear Right Door Switch Status";
BA_ "Version" SG_ 1264 HU_TimeSetting "18.09.02";
BA_ "NetworkRequest" SG_ 1264 HU_TimeSetting 0;
BA_ "UserSigValidity" SG_ 1264 HU_TimeSetting 0;
BA_ "GenSigStartValue" SG_ 1264 HU_TimeSetting 3;
BA_ "GenSigSendType" SG_ 1264 HU_TimeSetting 4;
BA_ "Description" SG_ 1264 HU_TimeSetting "18.08.09_";
BA_ "Version" SG_ 1264 HU_DisplayMinute "21.07.07";
BA_ "NetworkRequestHoldingTime" SG_ 1264 HU_DisplayMinute 200;
BA_ "NetworkRequest" SG_ 1264 HU_DisplayMinute 0;
BA_ "UserSigValidity" SG_ 1264 HU_DisplayMinute 0;
BA_ "GenSigStartValue" SG_ 1264 HU_DisplayMinute 255;
BA_ "GenSigSendType" SG_ 1264 HU_DisplayMinute 4;
BA_ "Version" SG_ 1264 HU_Status "21.07.07";
BA_ "NetworkRequestHoldingTime" SG_ 1264 HU_Status 200;
BA_ "NetworkRequest" SG_ 1264 HU_Status 0;
BA_ "UserSigValidity" SG_ 1264 HU_Status 0;
BA_ "GenSigStartValue" SG_ 1264 HU_Status 15;
BA_ "GenSigSendType" SG_ 1264 HU_Status 4;
BA_ "Version" SG_ 1264 HU_DisplaySecond "21.07.07";
BA_ "NetworkRequestHoldingTime" SG_ 1264 HU_DisplaySecond 200;
BA_ "NetworkRequest" SG_ 1264 HU_DisplaySecond 0;
BA_ "UserSigValidity" SG_ 1264 HU_DisplaySecond 0;
BA_ "GenSigStartValue" SG_ 1264 HU_DisplaySecond 255;
BA_ "GenSigSendType" SG_ 1264 HU_DisplaySecond 4;
BA_ "Version" SG_ 1264 HU_DisplayMonth "21.07.07";
BA_ "NetworkRequestHoldingTime" SG_ 1264 HU_DisplayMonth 200;
BA_ "NetworkRequest" SG_ 1264 HU_DisplayMonth 0;
BA_ "UserSigValidity" SG_ 1264 HU_DisplayMonth 0;
BA_ "GenSigStartValue" SG_ 1264 HU_DisplayMonth 15;
BA_ "GenSigSendType" SG_ 1264 HU_DisplayMonth 4;
BA_ "Version" SG_ 1264 HU_DisplayYear1 "18.09.02";
BA_ "NetworkRequest" SG_ 1264 HU_DisplayYear1 0;
BA_ "UserSigValidity" SG_ 1264 HU_DisplayYear1 0;
BA_ "GenSigStartValue" SG_ 1264 HU_DisplayYear1 3;
BA_ "GenSigSendType" SG_ 1264 HU_DisplayYear1 4;
BA_ "Description" SG_ 1264 HU_DisplayYear1 "18.08.09_";
BA_ "Version" SG_ 1264 HU_DisplayYear2 "21.07.07";
BA_ "NetworkRequestHoldingTime" SG_ 1264 HU_DisplayYear2 200;
BA_ "NetworkRequest" SG_ 1264 HU_DisplayYear2 0;
BA_ "UserSigValidity" SG_ 1264 HU_DisplayYear2 0;
BA_ "GenSigStartValue" SG_ 1264 HU_DisplayYear2 255;
BA_ "GenSigSendType" SG_ 1264 HU_DisplayYear2 4;
BA_ "Version" SG_ 1264 HU_DisplayDay "21.07.07";
BA_ "NetworkRequestHoldingTime" SG_ 1264 HU_DisplayDay 200;
BA_ "NetworkRequest" SG_ 1264 HU_DisplayDay 0;
BA_ "UserSigValidity" SG_ 1264 HU_DisplayDay 0;
BA_ "GenSigStartValue" SG_ 1264 HU_DisplayDay 255;
BA_ "GenSigSendType" SG_ 1264 HU_DisplayDay 4;
BA_ "Version" SG_ 1264 HU_AM_PM_INFO "18.09.02";
BA_ "NetworkRequest" SG_ 1264 HU_AM_PM_INFO 0;
BA_ "UserSigValidity" SG_ 1264 HU_AM_PM_INFO 0;
BA_ "GenSigStartValue" SG_ 1264 HU_AM_PM_INFO 3;
BA_ "GenSigSendType" SG_ 1264 HU_AM_PM_INFO 4;
BA_ "Description" SG_ 1264 HU_AM_PM_INFO "18.08.09_";
BA_ "Version" SG_ 1264 HU_TimeFormat "18.09.02";
BA_ "NetworkRequest" SG_ 1264 HU_TimeFormat 0;
BA_ "UserSigValidity" SG_ 1264 HU_TimeFormat 0;
BA_ "GenSigStartValue" SG_ 1264 HU_TimeFormat 3;
BA_ "GenSigSendType" SG_ 1264 HU_TimeFormat 4;
BA_ "Description" SG_ 1264 HU_TimeFormat "18.08.09_";
BA_ "Version" SG_ 1264 HU_ComRefresh "18.09.02";
BA_ "NetworkRequest" SG_ 1264 HU_ComRefresh 0;
BA_ "UserSigValidity" SG_ 1264 HU_ComRefresh 0;
BA_ "GenSigStartValue" SG_ 1264 HU_ComRefresh 3;
BA_ "GenSigSendType" SG_ 1264 HU_ComRefresh 4;
BA_ "Description" SG_ 1264 HU_ComRefresh "18.08.09_";
BA_ "Version" SG_ 1264 HU_ClockInfo "18.09.02";
BA_ "NetworkRequest" SG_ 1264 HU_ClockInfo 0;
BA_ "UserSigValidity" SG_ 1264 HU_ClockInfo 0;
BA_ "GenSigStartValue" SG_ 1264 HU_ClockInfo 3;
BA_ "GenSigSendType" SG_ 1264 HU_ClockInfo 4;
BA_ "Description" SG_ 1264 HU_ClockInfo "18.08.09_";
BA_ "Version" SG_ 1264 HU_DisplayHour "21.07.07";
BA_ "NetworkRequestHoldingTime" SG_ 1264 HU_DisplayHour 200;
BA_ "NetworkRequest" SG_ 1264 HU_DisplayHour 0;
BA_ "UserSigValidity" SG_ 1264 HU_DisplayHour 0;
BA_ "GenSigStartValue" SG_ 1264 HU_DisplayHour 255;
BA_ "GenSigSendType" SG_ 1264 HU_DisplayHour 4;
BA_ "Version" SG_ 1265 HU_Background "22.11.03";
BA_ "UserSigValidity" SG_ 1265 HU_Background 1;
BA_ "GenSigStartValue" SG_ 1265 HU_Background 7;
BA_ "GenSigSendType" SG_ 1265 HU_Background 4;
BA_ "Description" SG_ 1265 HU_Background "HU Backgound image info";
BA_ "Version" SG_ 1265 HU_BackgroundFadeInOut "22.07.05";
BA_ "UserSigValidity" SG_ 1265 HU_BackgroundFadeInOut 1;
BA_ "GenSigStartValue" SG_ 1265 HU_BackgroundFadeInOut 1023;
BA_ "GenSigSendType" SG_ 1265 HU_BackgroundFadeInOut 4;
BA_ "Description" SG_ 1265 HU_BackgroundFadeInOut "HU Background Fade in/out info

(HEX * Factor) %";
BA_ "Version" SG_ 1278 HU_Type "21.09.02";
BA_ "NetworkRequestHoldingTime" SG_ 1278 HU_Type 7000;
BA_ "NetworkRequest" SG_ 1278 HU_Type 0;
BA_ "UserSigValidity" SG_ 1278 HU_Type 1;
BA_ "GenSigStartValue" SG_ 1278 HU_Type 255;
BA_ "GenSigSendType" SG_ 1278 HU_Type 4;
BA_ "Version" SG_ 1278 HU_DistributeInfo "20.09.00";
BA_ "NetworkRequestHoldingTime" SG_ 1278 HU_DistributeInfo 7000;
BA_ "NetworkRequest" SG_ 1278 HU_DistributeInfo 0;
BA_ "UserSigValidity" SG_ 1278 HU_DistributeInfo 1;
BA_ "GenSigStartValue" SG_ 1278 HU_DistributeInfo 255;
BA_ "GenSigSendType" SG_ 1278 HU_DistributeInfo 4;
BA_ "Version" SG_ 1278 HU_OptionInfo "21.09.05";
BA_ "UserSigValidity" SG_ 1278 HU_OptionInfo 0;
BA_ "GenSigStartValue" SG_ 1278 HU_OptionInfo 32768;
BA_ "GenSigSendType" SG_ 1278 HU_OptionInfo 4;
BA_ "Description" SG_ 1278 HU_OptionInfo "Bit0 : Navi (0: Not Support / 1: Support)

Bit1 : USM (0: Not Support / 1: Support)

Bit2 : TMS (0: Not Support / 1: Support)

Bit3 : Multi Profile (0: Not Support(No Profile or Single Profile)  / 1: Support)

Bit4 : Camera Guideline (0: Displayed by Cam";
BA_ "Version" SG_ 2256644609 CLU_SpdUnitTyp "17.11.00";
BA_ "RoutingFactor" SG_ 2256644609 CLU_SpdUnitTyp 5;
BA_ "UserSigValidity" SG_ 2256644609 CLU_SpdUnitTyp 3;
BA_ "Description" SG_ 2256644609 CLU_SpdUnitTyp "This signal indicates the unit of the speed displayed in the speedometer.";
BA_ "Version" SG_ 2256644609 CLU_DisSpdVal "17.12.03";
BA_ "RoutingFactor" SG_ 2256644609 CLU_DisSpdVal 5;
BA_ "UserSigValidity" SG_ 2256644609 CLU_DisSpdVal 3;
BA_ "Description" SG_ 2256644609 CLU_DisSpdVal "The vehicle speed which is indicated in the speedmeter has to be sent to SCC. This value is used for evalution of SCC command values instead of the vehicle velocity in order to avoid significant difference between the speedmeter indicator and the set spe";
BA_ "Version" SG_ 881 HU_GNSS_UTC_year "22.07.05";
BA_ "UserSigValidity" SG_ 881 HU_GNSS_UTC_year 1;
BA_ "Description" SG_ 881 HU_GNSS_UTC_year "2000+";
BA_ "Version" SG_ 881 HU_GNSS_UTC_month "22.07.05";
BA_ "UserSigValidity" SG_ 881 HU_GNSS_UTC_month 1;
BA_ "Description" SG_ 881 HU_GNSS_UTC_month "range : [1, 12]";
BA_ "Version" SG_ 881 HU_GNSS_UTC_day "22.07.05";
BA_ "UserSigValidity" SG_ 881 HU_GNSS_UTC_day 1;
BA_ "Description" SG_ 881 HU_GNSS_UTC_day "range : [1, 31]";
BA_ "Version" SG_ 881 HU_GNSS_UTC_hour "22.07.05";
BA_ "UserSigValidity" SG_ 881 HU_GNSS_UTC_hour 1;
BA_ "Description" SG_ 881 HU_GNSS_UTC_hour "range : [0, 23]";
BA_ "Version" SG_ 881 HU_GNSS_UTC_min "22.07.05";
BA_ "UserSigValidity" SG_ 881 HU_GNSS_UTC_min 1;
BA_ "Description" SG_ 881 HU_GNSS_UTC_min "range : [0,59]";
BA_ "Version" SG_ 881 HU_GNSS_UTC_sec "22.07.05";
BA_ "UserSigValidity" SG_ 881 HU_GNSS_UTC_sec 1;
BA_ "Description" SG_ 881 HU_GNSS_UTC_sec "ragne : [0, 60]  /  60 only for the leap second";
BA_ "Version" SG_ 881 HU_GNSS_UTC_offset "22.07.05";
BA_ "UserSigValidity" SG_ 881 HU_GNSS_UTC_offset 1;
BA_ "Description" SG_ 881 HU_GNSS_UTC_offset "GPS = UTC + offset";
BA_ "Version" SG_ 1016 GNSS_MM_type "22.07.05";
BA_ "UserSigValidity" SG_ 1016 GNSS_MM_type 1;
BA_ "GenSigStartValue" SG_ 1016 GNSS_MM_type 15;
BA_ "Version" SG_ 883 HU_GNSS_DST "22.07.05";
BA_ "UserSigValidity" SG_ 883 HU_GNSS_DST 1;
BA_ "GenSigStartValue" SG_ 883 HU_GNSS_DST 3;
BA_ "Description" SG_ 883 HU_GNSS_DST "DST setting";
BA_ "Version" SG_ 883 HU_GNSS_TimezoneOffset "22.07.05";
BA_ "UserSigValidity" SG_ 883 HU_GNSS_TimezoneOffset 1;
BA_ "Description" SG_ 883 HU_GNSS_TimezoneOffset "offset = [ value * factor(15) ] min.";
BA_ "Version" SG_ 2256644610 CLU_AutoBrightSta "20.12.05";
BA_ "RoutingFactor" SG_ 2256644610 CLU_AutoBrightSta 5;
BA_ "UserSigValidity" SG_ 2256644610 CLU_AutoBrightSta 0;
BA_ "Description" SG_ 2256644610 CLU_AutoBrightSta "This signal is used for a auto bright level of CLUSTER from 1step to 200step for a Unified Illumination system.



※ Start Value : Current value";
BA_ "Version" SG_ 2214658049 ENG_BrkSwSta "18.11.00";
BA_ "RoutingFactor" SG_ 2214658049 ENG_BrkSwSta 5;
BA_ "UserSigValidity" SG_ 2214658049 ENG_BrkSwSta 3;
BA_ "GenSigStartValue" SG_ 2214658049 ENG_BrkSwSta 1;
BA_ "Description" SG_ 2214658049 ENG_BrkSwSta "This signal indicates that a brake switch is activated or not. When the brake switch is activated(pressed) its value is 01H otherwise its value is 00H.

If the EMS does not support this signal the value is 02H.



Physical range : 0 ... 100

Conversion :";
BA_ "Version" SG_ 2214658049 ENG_EngSta "17.12.00";
BA_ "RoutingFactor" SG_ 2214658049 ENG_EngSta 5;
BA_ "UserSigValidity" SG_ 2214658049 ENG_EngSta 3;
BA_ "Description" SG_ 2214658049 ENG_EngSta "This signal indicates that a status of engine.";
BA_ "Version" SG_ 2223056129 SAS_AnglVal "21.07.05";
BA_ "RoutingFactor" SG_ 2223056129 SAS_AnglVal 5;
BA_ "UserSigValidity" SG_ 2223056129 SAS_AnglVal 3;
BA_ "GenSigStartValue" SG_ 2223056129 SAS_AnglVal 32767;
BA_ "Description" SG_ 2223056129 SAS_AnglVal "Information regarding the steering wheel angle.  (PH) = (HEX) * 0.1 (0 <  HEX < 7FFFH) or (PH) = (HEX - 65536) * 0.1 (HEX > 7FFFH)



this signal has direction information.

'+' Value means Counter clock wise rotation.

'-' value means Clock wise rotatio";
BA_ "Version" SG_ 884 HU_MM_Latitude "22.07.05";
BA_ "UserSigValidity" SG_ 884 HU_MM_Latitude 1;
BA_ "Description" SG_ 884 HU_MM_Latitude "range = -90*1,000,000 <= Value <=90*1,000,000

unit = degree*1,000,000";
BA_ "Version" SG_ 884 HU_MM_Longitude "22.07.05";
BA_ "UserSigValidity" SG_ 884 HU_MM_Longitude 1;
BA_ "Description" SG_ 884 HU_MM_Longitude "range = -180*1,000,000 <= Value <= 180*1,000,000

unit = degree*1,000,000";
BA_REL_ "GenSigTimeoutTime" BU_SG_REL_ CGW_CCU SG_ 952 BLTN_CAM_Set_FR_Ver_Pos 1500;
BA_REL_ "GenSigTimeoutTime" BU_SG_REL_ CGW_CCU SG_ 952 BLTN_CAM_Set_PEV_AppNoti 1500;
BA_REL_ "GenSigTimeoutTime" BU_SG_REL_ CGW_CCU SG_ 952 BLTN_CAM_Set_WiFi_AutoOn 1500;
BA_REL_ "GenSigTimeoutTime" BU_SG_REL_ CGW_CCU SG_ 952 BLTN_CAM_StrgPropSet 1500;
BA_REL_ "GenSigTimeoutTime" BU_SG_REL_ CGW_CCU SG_ 952 BLTN_CAM_File_DEL_CPY_Op_State 1500;
BA_REL_ "GenSigTimeoutTime" BU_SG_REL_ CGW_CCU SG_ 952 BLTN_CAM_File_DEL_CPY_NumTot 1500;
BA_REL_ "GenSigTimeoutTime" BU_SG_REL_ CGW_CCU SG_ 952 BLTN_CAM_File_DEL_CPYed_Num 1500;
BA_REL_ "GenSigTimeoutTime" BU_SG_REL_ CGW_CCU SG_ 952 BLTN_CAM_Set_RR_Ver_Pos 1500;
BA_REL_ "GenSigTimeoutTime" BU_SG_REL_ BLTN_CAM SG_ 1219 BLTN_CAM_Rec_OWD_NvalueSet 0;
BA_REL_ "GenSigTimeoutTime" BU_SG_REL_ BLTN_CAM SG_ 1219 BLTN_CAM_Time_Stm_NvalueSet 0;
BA_REL_ "GenSigTimeoutTime" BU_SG_REL_ BLTN_CAM SG_ 1219 BLTN_CAM_Spd_Stm_NvalueSet 0;
BA_REL_ "GenSigTimeoutTime" BU_SG_REL_ BLTN_CAM SG_ 1219 BLTN_CAM_Locatn_Stm_NvalueSet 0;
BA_REL_ "GenSigTimeoutTime" BU_SG_REL_ BLTN_CAM SG_ 1219 BLTN_CAM_TrnSig_Stm_NvalueSet 0;
BA_REL_ "GenSigTimeoutTime" BU_SG_REL_ BLTN_CAM SG_ 1219 BLTN_CAM_AclBrk_Stm_NvalueSet 0;
BA_REL_ "GenSigTimeoutTime" BU_SG_REL_ BLTN_CAM SG_ 1219 BLTN_CAM_Rec_DEV_NvalueSet 0;
BA_REL_ "GenSigTimeoutTime" BU_SG_REL_ BLTN_CAM SG_ 1219 BLTN_CAM_GearPos_Stm_NvalueSet 0;
BA_REL_ "GenSigTimeoutTime" BU_SG_REL_ BLTN_CAM SG_ 1219 BLTN_CAM_EVSen_Stm_NvalueSet 0;
BA_REL_ "GenSigTimeoutTime" BU_SG_REL_ BLTN_CAM SG_ 1219 BLTN_CAM_Strangl_Stm_NvalueSet 0;
BA_REL_ "GenSigTimeoutTime" BU_SG_REL_ BLTN_CAM SG_ 1219 BLTN_CAM_EV_RecMaxTime_NvalueSet 0;
BA_REL_ "GenSigTimeoutTime" BU_SG_REL_ BLTN_CAM SG_ 1219 BLTN_CAM_PrkTime_NvalueSet 0;
BA_REL_ "GenSigTimeoutTime" BU_SG_REL_ BLTN_CAM SG_ 1219 BLTN_CAM_EV_BfrTime_NvalueSet 0;
BA_REL_ "GenSigTimeoutTime" BU_SG_REL_ BLTN_CAM SG_ 1219 BLTN_CAM_Rec_OWP_NvalueSet 0;
BA_REL_ "GenSigTimeoutTime" BU_SG_REL_ BLTN_CAM SG_ 1219 BLTN_CAM_EV_AftTime_NvalueSet 0;
BA_REL_ "GenSigTimeoutTime" BU_SG_REL_ BLTN_CAM SG_ 1219 BLTN_CAM_TML_Int_NvalueSet 0;
BA_REL_ "GenSigTimeoutTime" BU_SG_REL_ BLTN_CAM SG_ 1219 BLTN_CAM_Sen_DEV_NvalueSet 0;
BA_REL_ "GenSigTimeoutTime" BU_SG_REL_ BLTN_CAM SG_ 1219 BLTN_CAM_Sen_PEV_NvalueSet 0;
BA_REL_ "GenSigTimeoutTime" BU_SG_REL_ BLTN_CAM SG_ 1219 BLTN_CAM_Rec_PEV_NvalueSet 0;
BA_REL_ "GenSigTimeoutTime" BU_SG_REL_ BLTN_CAM SG_ 1219 BLTN_CAM_AudRec_NvalueSet 0;
BA_REL_ "GenSigTimeoutTime" BU_SG_REL_ CGW_CCU SG_ 950 BLTN_CAM_State 1500;
BA_REL_ "GenSigTimeoutTime" BU_SG_REL_ CGW_CCU SG_ 950 BLTN_CAM_RecSta_DEV 1500;
BA_REL_ "GenSigTimeoutTime" BU_SG_REL_ CGW_CCU SG_ 950 BLTN_CAM_RecSta_MAR 1500;
BA_REL_ "GenSigTimeoutTime" BU_SG_REL_ CGW_CCU SG_ 950 BLTN_CAM_RecSta_TML 1500;
BA_REL_ "GenSigTimeoutTime" BU_SG_REL_ CGW_CCU SG_ 950 BLTN_CAM_RecSta_OWP 1500;
BA_REL_ "GenSigTimeoutTime" BU_SG_REL_ CGW_CCU SG_ 950 BLTN_CAM_RecSta_PEV 1500;
BA_REL_ "GenSigTimeoutTime" BU_SG_REL_ CGW_CCU SG_ 950 BLTN_CAM_Prk_EV_Cnt 1500;
BA_REL_ "GenSigTimeoutTime" BU_SG_REL_ CGW_CCU SG_ 950 BLTN_CAM_Prk_Oped_Time 1500;
BA_REL_ "GenSigTimeoutTime" BU_SG_REL_ CGW_CCU SG_ 950 BLTN_CAM_Prk_Oprable_Time 1500;
BA_REL_ "GenSigTimeoutTime" BU_SG_REL_ CGW_CCU SG_ 950 BLTN_CAM_SD_Card_State 1500;
BA_REL_ "GenSigTimeoutTime" BU_SG_REL_ CGW_CCU SG_ 950 BLTN_CAM_Prk_Oprable_Time_Max 1500;
BA_REL_ "GenSigTimeoutTime" BU_SG_REL_ CGW_CCU SG_ 950 BLTN_CAM_AuxBat_Conn_State 1500;
BA_REL_ "GenSigTimeoutTime" BU_SG_REL_ CGW_CCU SG_ 950 BLTN_CAM_AuxBat_CapPer 1500;
BA_REL_ "GenSigTimeoutTime" BU_SG_REL_ CGW_CCU SG_ 950 BLTN_CAM_RecSta_OWD 1500;
BA_REL_ "GenSigTimeoutTime" BU_SG_REL_ CGW_CCU SG_ 951 BLTN_CAM_RecSet_OWD 1500;
BA_REL_ "GenSigTimeoutTime" BU_SG_REL_ CGW_CCU SG_ 951 BLTN_CAM_Set_Tim_Stm 1500;
BA_REL_ "GenSigTimeoutTime" BU_SG_REL_ CGW_CCU SG_ 951 BLTN_CAM_Set_Spd_Stm 1500;
BA_REL_ "GenSigTimeoutTime" BU_SG_REL_ CGW_CCU SG_ 951 BLTN_CAM_Set_Locatn_Stm 1500;
BA_REL_ "GenSigTimeoutTime" BU_SG_REL_ CGW_CCU SG_ 951 BLTN_CAM_Set_TrnSig_Stm 1500;
BA_REL_ "GenSigTimeoutTime" BU_SG_REL_ CGW_CCU SG_ 951 BLTN_CAM_Set_AclBrk_Stm 1500;
BA_REL_ "GenSigTimeoutTime" BU_SG_REL_ CGW_CCU SG_ 951 BLTN_CAM_RecSet_DEV 1500;
BA_REL_ "GenSigTimeoutTime" BU_SG_REL_ CGW_CCU SG_ 951 BLTN_CAM_Set_GearPos_Stm 1500;
BA_REL_ "GenSigTimeoutTime" BU_SG_REL_ CGW_CCU SG_ 951 BLTN_CAM_Set_EVSen_Stm 1500;
BA_REL_ "GenSigTimeoutTime" BU_SG_REL_ CGW_CCU SG_ 951 BLTN_CAM_Set_StrAngl_Stm 1500;
BA_REL_ "GenSigTimeoutTime" BU_SG_REL_ CGW_CCU SG_ 951 BLTN_CAM_Set_EV_RecMaxTime 1500;
BA_REL_ "GenSigTimeoutTime" BU_SG_REL_ CGW_CCU SG_ 951 BLTN_CAM_Set_PrkTime 1500;
BA_REL_ "GenSigTimeoutTime" BU_SG_REL_ CGW_CCU SG_ 951 BLTN_CAM_Set_EV_BfrTime 1500;
BA_REL_ "GenSigTimeoutTime" BU_SG_REL_ CGW_CCU SG_ 951 BLTN_CAM_RecSet_OWP 1500;
BA_REL_ "GenSigTimeoutTime" BU_SG_REL_ CGW_CCU SG_ 951 BLTN_CAM_Set_EV_AftTime 1500;
BA_REL_ "GenSigTimeoutTime" BU_SG_REL_ CGW_CCU SG_ 951 BLTN_CAM_Set_Drv_TML_Int 1500;
BA_REL_ "GenSigTimeoutTime" BU_SG_REL_ CGW_CCU SG_ 951 BLTN_CAM_SenSet_DEV 1500;
BA_REL_ "GenSigTimeoutTime" BU_SG_REL_ CGW_CCU SG_ 951 BLTN_CAM_SenSet_PEV 1500;
BA_REL_ "GenSigTimeoutTime" BU_SG_REL_ CGW_CCU SG_ 951 BLTN_CAM_RecSet_PEV 1500;
BA_REL_ "GenSigTimeoutTime" BU_SG_REL_ CGW_CCU SG_ 951 BLTN_CAM_AudRec_Set 1500;
BA_REL_ "GenSigTimeoutTime" BU_SG_REL_ BLTN_CAM SG_ 2307024129 HEV_BrkLtSwSta 1500;
BA_REL_ "GenSigTimeoutTime" BU_SG_REL_ BLTN_CAM SG_ 1239 HU_PwrState 1500;
BA_REL_ "GenSigTimeoutTime" BU_SG_REL_ BLTN_CAM SG_ 1239 HU_VehiclePwr 1500;
BA_REL_ "GenSigTimeoutTime" BU_SG_REL_ SGU SG_ 1239 HU_VehiclePwr 1500;
BA_REL_ "GenSigTimeoutTime" BU_SG_REL_ ATS SG_ 1240 HU_ThemeType 1500;
BA_REL_ "GenSigTimeoutTime" BU_SG_REL_ BLTN_CAM SG_ 1240 HU_ThemeType 1500;
BA_REL_ "GenSigTimeoutTime" BU_SG_REL_ BLTN_CAM SG_ 1240 CF_AVN_ProfileIDRValue 1500;
BA_REL_ "GenSigTimeoutTime" BU_SG_REL_ GW_DLBCU SG_ 1240 CF_AVN_ProfileIDRValue 1500;
BA_REL_ "GenSigTimeoutTime" BU_SG_REL_ GW_DPSU SG_ 1240 CF_AVN_ProfileIDRValue 1500;
BA_REL_ "GenSigTimeoutTime" BU_SG_REL_ RCM SG_ 1240 CF_AVN_ProfileIDRValue 1500;
BA_REL_ "GenSigTimeoutTime" BU_SG_REL_ RWPC SG_ 1240 CF_AVN_ProfileIDRValue 1500;
BA_REL_ "GenSigTimeoutTime" BU_SG_REL_ SGU SG_ 1240 CF_AVN_ProfileIDRValue 1500;
BA_REL_ "GenSigTimeoutTime" BU_SG_REL_ WPC SG_ 1240 CF_AVN_ProfileIDRValue 1500;
BA_REL_ "GenSigTimeoutTime" BU_SG_REL_ WPC2 SG_ 1240 CF_AVN_ProfileIDRValue 1500;
BA_REL_ "GenSigTimeoutTime" BU_SG_REL_ CGW_CCU SG_ 171 BLTN_CAM_UI_Mode_Tmt_Req 0;
BA_REL_ "GenSigTimeoutTime" BU_SG_REL_ CGW_CCU SG_ 171 BLTN_CAM_Dis_Touch_BeepSound 0;
BA_REL_ "GenSigTimeoutTime" BU_SG_REL_ CGW_CCU SG_ 171 BLTN_CAM_PopUp_Req 0;
BA_REL_ "GenSigTimeoutTime" BU_SG_REL_ CGW_CCU SG_ 171 BLTN_CAM_File_List_Renew 0;
BA_REL_ "GenSigTimeoutTime" BU_SG_REL_ CGW_CCU SG_ 171 BLTN_CAM_Wifi_Pwd_Chg_State 0;
BA_REL_ "GenSigTimeoutTime" BU_SG_REL_ BLTN_CAM SG_ 172 BLTN_CAM_FR_VerPos_NvalueSet 0;
BA_REL_ "GenSigTimeoutTime" BU_SG_REL_ BLTN_CAM SG_ 172 BLTN_CAM_AppNoti_PEV_NvalueSet 0;
BA_REL_ "GenSigTimeoutTime" BU_SG_REL_ BLTN_CAM SG_ 172 BLTN_CAM_WiFi_AutoOn_NvalueSet 0;
BA_REL_ "GenSigTimeoutTime" BU_SG_REL_ BLTN_CAM SG_ 172 BLTN_CAM_StoProp_NvalueSet 0;
BA_REL_ "GenSigTimeoutTime" BU_SG_REL_ BLTN_CAM SG_ 172 CF_AVN_BLTN_CAM_USMReset 0;
BA_REL_ "GenSigTimeoutTime" BU_SG_REL_ BLTN_CAM SG_ 172 CF_AVN_BLTN_CAM_RecReset 0;
BA_REL_ "GenSigTimeoutTime" BU_SG_REL_ BLTN_CAM SG_ 172 BLTN_CAM_File_DEL_CPY_Cmd 0;
BA_REL_ "GenSigTimeoutTime" BU_SG_REL_ BLTN_CAM SG_ 172 BLTN_CAM_LVDS_Mode_Cmd 0;
BA_REL_ "GenSigTimeoutTime" BU_SG_REL_ BLTN_CAM SG_ 172 HU_BLTN_CAM_Disp_Touch_Pos_X 0;
BA_REL_ "GenSigTimeoutTime" BU_SG_REL_ BLTN_CAM SG_ 172 HU_BLTN_CAM_Disp_Touch_Pos_Y 0;
BA_REL_ "GenSigTimeoutTime" BU_SG_REL_ BLTN_CAM SG_ 172 MEV_Rec_Req 0;
BA_REL_ "GenSigTimeoutTime" BU_SG_REL_ BLTN_CAM SG_ 172 BLTN_CAM_RR_VerPos_NvalueSet 0;
BA_REL_ "GenSigTimeoutTime" BU_SG_REL_ BLTN_CAM SG_ 172 TML_Rec_Req 0;
BA_REL_ "GenSigTimeoutTime" BU_SG_REL_ BLTN_CAM SG_ 172 BLTN_CAM_SD_Card_UnMt_Mt_Req 0;
BA_REL_ "GenSigTimeoutTime" BU_SG_REL_ BLTN_CAM SG_ 799 DRV_CrashUnlockCmd 1500;
BA_REL_ "GenSigTimeoutTime" BU_SG_REL_ ATS SG_ 799 Warn_DrvDrSwSta_SBCM 1500;
BA_REL_ "GenSigTimeoutTime" BU_SG_REL_ BLTN_CAM SG_ 799 Warn_DrvDrSwSta_SBCM 1500;
BA_REL_ "GenSigTimeoutTime" BU_SG_REL_ GW_DPSU SG_ 799 Warn_DrvDrSwSta_SBCM 1500;
BA_REL_ "GenSigTimeoutTime" BU_SG_REL_ PSB SG_ 799 Warn_DrvDrSwSta_SBCM 1500;
BA_REL_ "GenSigTimeoutTime" BU_SG_REL_ RWPC SG_ 799 Warn_DrvDrSwSta_SBCM 1500;
BA_REL_ "GenSigTimeoutTime" BU_SG_REL_ WPC SG_ 799 Warn_DrvDrSwSta_SBCM 1500;
BA_REL_ "GenSigTimeoutTime" BU_SG_REL_ WPC2 SG_ 799 Warn_DrvDrSwSta_SBCM 1500;
BA_REL_ "GenSigTimeoutTime" BU_SG_REL_ BLTN_CAM SG_ 912 HU_BLTN_CAM_UI_Mode 1500;
BA_REL_ "GenSigTimeoutTime" BU_SG_REL_ BLTN_CAM SG_ 912 HU_BLTN_CAM_Display 1500;
BA_REL_ "GenSigTimeoutTime" BU_SG_REL_ ATS SG_ 1266 HU_LanguageInfo 5000;
BA_REL_ "GenSigTimeoutTime" BU_SG_REL_ BLTN_CAM SG_ 1266 HU_LanguageInfo 5000;
BA_REL_ "GenSigTimeoutTime" BU_SG_REL_ BLTN_CAM SG_ 905 RR_CrashUnlockCmd 1500;
BA_REL_ "GenSigTimeoutTime" BU_SG_REL_ ATS SG_ 905 Warn_RrRtDrSwSta_SBCM 1500;
BA_REL_ "GenSigTimeoutTime" BU_SG_REL_ BLTN_CAM SG_ 905 Warn_RrRtDrSwSta_SBCM 1500;
BA_REL_ "GenSigTimeoutTime" BU_SG_REL_ GW_APSU SG_ 905 Warn_RrRtDrSwSta_SBCM 1500;
BA_REL_ "GenSigTimeoutTime" BU_SG_REL_ GW_RLPSU SG_ 905 Warn_RrRtDrSwSta_SBCM 1500;
BA_REL_ "GenSigTimeoutTime" BU_SG_REL_ GW_RRPSU SG_ 905 Warn_RrRtDrSwSta_SBCM 1500;
BA_REL_ "GenSigTimeoutTime" BU_SG_REL_ RWPC SG_ 905 Warn_RrRtDrSwSta_SBCM 1500;
BA_REL_ "GenSigTimeoutTime" BU_SG_REL_ WPC SG_ 905 Warn_RrRtDrSwSta_SBCM 1500;
BA_REL_ "GenSigTimeoutTime" BU_SG_REL_ WPC2 SG_ 905 Warn_RrRtDrSwSta_SBCM 1500;
BA_REL_ "GenSigTimeoutTime" BU_SG_REL_ ATS SG_ 1264 HU_TimeSetting 5000;
BA_REL_ "GenSigTimeoutTime" BU_SG_REL_ BLTN_CAM SG_ 1264 HU_TimeSetting 5000;
BA_REL_ "GenSigTimeoutTime" BU_SG_REL_ ATS SG_ 1264 HU_DisplayMinute 5000;
BA_REL_ "GenSigTimeoutTime" BU_SG_REL_ BLTN_CAM SG_ 1264 HU_DisplayMinute 5000;
BA_REL_ "GenSigTimeoutTime" BU_SG_REL_ ATS SG_ 1264 HU_Status 5000;
BA_REL_ "GenSigTimeoutTime" BU_SG_REL_ BLTN_CAM SG_ 1264 HU_Status 5000;
BA_REL_ "GenSigTimeoutTime" BU_SG_REL_ ATS SG_ 1264 HU_DisplaySecond 5000;
BA_REL_ "GenSigTimeoutTime" BU_SG_REL_ BLTN_CAM SG_ 1264 HU_DisplaySecond 5000;
BA_REL_ "GenSigTimeoutTime" BU_SG_REL_ ATS SG_ 1264 HU_DisplayMonth 5000;
BA_REL_ "GenSigTimeoutTime" BU_SG_REL_ BLTN_CAM SG_ 1264 HU_DisplayMonth 5000;
BA_REL_ "GenSigTimeoutTime" BU_SG_REL_ ATS SG_ 1264 HU_DisplayYear1 5000;
BA_REL_ "GenSigTimeoutTime" BU_SG_REL_ BLTN_CAM SG_ 1264 HU_DisplayYear1 5000;
BA_REL_ "GenSigTimeoutTime" BU_SG_REL_ ATS SG_ 1264 HU_DisplayYear2 5000;
BA_REL_ "GenSigTimeoutTime" BU_SG_REL_ BLTN_CAM SG_ 1264 HU_DisplayYear2 5000;
BA_REL_ "GenSigTimeoutTime" BU_SG_REL_ ATS SG_ 1264 HU_DisplayDay 5000;
BA_REL_ "GenSigTimeoutTime" BU_SG_REL_ BLTN_CAM SG_ 1264 HU_DisplayDay 5000;
BA_REL_ "GenSigTimeoutTime" BU_SG_REL_ ATS SG_ 1264 HU_AM_PM_INFO 5000;
BA_REL_ "GenSigTimeoutTime" BU_SG_REL_ BLTN_CAM SG_ 1264 HU_AM_PM_INFO 5000;
BA_REL_ "GenSigTimeoutTime" BU_SG_REL_ ATS SG_ 1264 HU_TimeFormat 5000;
BA_REL_ "GenSigTimeoutTime" BU_SG_REL_ BLTN_CAM SG_ 1264 HU_TimeFormat 5000;
BA_REL_ "GenSigTimeoutTime" BU_SG_REL_ ATS SG_ 1264 HU_ComRefresh 5000;
BA_REL_ "GenSigTimeoutTime" BU_SG_REL_ BLTN_CAM SG_ 1264 HU_ComRefresh 5000;
BA_REL_ "GenSigTimeoutTime" BU_SG_REL_ ATS SG_ 1264 HU_ClockInfo 5000;
BA_REL_ "GenSigTimeoutTime" BU_SG_REL_ BLTN_CAM SG_ 1264 HU_ClockInfo 5000;
BA_REL_ "GenSigTimeoutTime" BU_SG_REL_ ATS SG_ 1264 HU_DisplayHour 5000;
BA_REL_ "GenSigTimeoutTime" BU_SG_REL_ BLTN_CAM SG_ 1264 HU_DisplayHour 5000;
BA_REL_ "GenSigTimeoutTime" BU_SG_REL_ ATS SG_ 1265 HU_Background 5000;
BA_REL_ "GenSigTimeoutTime" BU_SG_REL_ BLTN_CAM SG_ 1265 HU_Background 5000;
BA_REL_ "GenSigTimeoutTime" BU_SG_REL_ ATS SG_ 1265 HU_BackgroundFadeInOut 5000;
BA_REL_ "GenSigTimeoutTime" BU_SG_REL_ BLTN_CAM SG_ 1265 HU_BackgroundFadeInOut 5000;
BA_REL_ "GenSigTimeoutTime" BU_SG_REL_ BLTN_CAM SG_ 1278 HU_Type 5000;
BA_REL_ "GenSigTimeoutTime" BU_SG_REL_ BLTN_CAM SG_ 1278 HU_DistributeInfo 5000;
BA_REL_ "GenSigTimeoutTime" BU_SG_REL_ RCM SG_ 1278 HU_OptionInfo 5000;
BA_REL_ "GenSigTimeoutTime" BU_SG_REL_ BLTN_CAM SG_ 1278 HU_OptionInfo 5000;
BA_REL_ "GenSigTimeoutTime" BU_SG_REL_ WPC2 SG_ 1278 HU_OptionInfo 5000;
BA_REL_ "GenSigTimeoutTime" BU_SG_REL_ BLTN_CAM SG_ 2256644609 CLU_SpdUnitTyp 1500;
BA_REL_ "GenSigTimeoutTime" BU_SG_REL_ EMCU SG_ 2256644609 CLU_SpdUnitTyp 1500;
BA_REL_ "GenSigTimeoutTime" BU_SG_REL_ GW_DPSU SG_ 2256644609 CLU_SpdUnitTyp 1500;
BA_REL_ "GenSigTimeoutTime" BU_SG_REL_ WPC2 SG_ 2256644609 CLU_SpdUnitTyp 1500;
BA_REL_ "GenSigTimeoutTime" BU_SG_REL_ BLTN_CAM SG_ 2256644609 CLU_DisSpdVal 1500;
BA_REL_ "GenSigTimeoutTime" BU_SG_REL_ EMCU SG_ 2256644609 CLU_DisSpdVal 1500;
BA_REL_ "GenSigTimeoutTime" BU_SG_REL_ GW_APSU SG_ 2256644609 CLU_DisSpdVal 1500;
BA_REL_ "GenSigTimeoutTime" BU_SG_REL_ GW_DPSU SG_ 2256644609 CLU_DisSpdVal 1500;
BA_REL_ "GenSigTimeoutTime" BU_SG_REL_ WPC2 SG_ 2256644609 CLU_DisSpdVal 1500;
BA_REL_ "GenSigTimeoutTime" BU_SG_REL_ BLTN_CAM SG_ 881 HU_GNSS_UTC_year 5000;
BA_REL_ "GenSigTimeoutTime" BU_SG_REL_ BLTN_CAM SG_ 881 HU_GNSS_UTC_month 5000;
BA_REL_ "GenSigTimeoutTime" BU_SG_REL_ BLTN_CAM SG_ 881 HU_GNSS_UTC_day 5000;
BA_REL_ "GenSigTimeoutTime" BU_SG_REL_ BLTN_CAM SG_ 881 HU_GNSS_UTC_hour 5000;
BA_REL_ "GenSigTimeoutTime" BU_SG_REL_ BLTN_CAM SG_ 881 HU_GNSS_UTC_min 5000;
BA_REL_ "GenSigTimeoutTime" BU_SG_REL_ BLTN_CAM SG_ 881 HU_GNSS_UTC_sec 5000;
BA_REL_ "GenSigTimeoutTime" BU_SG_REL_ BLTN_CAM SG_ 881 HU_GNSS_UTC_offset 5000;
BA_REL_ "GenSigTimeoutTime" BU_SG_REL_ BLTN_CAM SG_ 1016 GNSS_MM_type 5000;
BA_REL_ "GenSigTimeoutTime" BU_SG_REL_ BLTN_CAM SG_ 883 HU_GNSS_DST 5000;
BA_REL_ "GenSigTimeoutTime" BU_SG_REL_ BLTN_CAM SG_ 883 HU_GNSS_TimezoneOffset 5000;
BA_REL_ "GenSigTimeoutTime" BU_SG_REL_ ASAU SG_ 2256644610 CLU_AutoBrightSta 1500;
BA_REL_ "GenSigTimeoutTime" BU_SG_REL_ ATS SG_ 2256644610 CLU_AutoBrightSta 1500;
BA_REL_ "GenSigTimeoutTime" BU_SG_REL_ BLTN_CAM SG_ 2256644610 CLU_AutoBrightSta 1500;
BA_REL_ "GenSigTimeoutTime" BU_SG_REL_ DSAU SG_ 2256644610 CLU_AutoBrightSta 1500;
BA_REL_ "GenSigTimeoutTime" BU_SG_REL_ FCS SG_ 2256644610 CLU_AutoBrightSta 1500;
BA_REL_ "GenSigTimeoutTime" BU_SG_REL_ GW_APSU SG_ 2256644610 CLU_AutoBrightSta 1500;
BA_REL_ "GenSigTimeoutTime" BU_SG_REL_ GW_DPSU SG_ 2256644610 CLU_AutoBrightSta 1500;
BA_REL_ "GenSigTimeoutTime" BU_SG_REL_ GW_RLPSU SG_ 2256644610 CLU_AutoBrightSta 1500;
BA_REL_ "GenSigTimeoutTime" BU_SG_REL_ GW_RRPSU SG_ 2256644610 CLU_AutoBrightSta 1500;
BA_REL_ "GenSigTimeoutTime" BU_SG_REL_ OHCL SG_ 2256644610 CLU_AutoBrightSta 1500;
BA_REL_ "GenSigTimeoutTime" BU_SG_REL_ RCS SG_ 2256644610 CLU_AutoBrightSta 1500;
BA_REL_ "GenSigTimeoutTime" BU_SG_REL_ RLHV SG_ 2256644610 CLU_AutoBrightSta 1500;
BA_REL_ "GenSigTimeoutTime" BU_SG_REL_ RRHV SG_ 2256644610 CLU_AutoBrightSta 1500;
BA_REL_ "GenSigTimeoutTime" BU_SG_REL_ RWPC SG_ 2256644610 CLU_AutoBrightSta 1500;
BA_REL_ "GenSigTimeoutTime" BU_SG_REL_ SHVU_FR SG_ 2256644610 CLU_AutoBrightSta 1500;
BA_REL_ "GenSigTimeoutTime" BU_SG_REL_ SHVU_RR SG_ 2256644610 CLU_AutoBrightSta 1500;
BA_REL_ "GenSigTimeoutTime" BU_SG_REL_ SWRC SG_ 2256644610 CLU_AutoBrightSta 1500;
BA_REL_ "GenSigTimeoutTime" BU_SG_REL_ WPC SG_ 2256644610 CLU_AutoBrightSta 1500;
BA_REL_ "GenSigTimeoutTime" BU_SG_REL_ WPC2 SG_ 2256644610 CLU_AutoBrightSta 1500;
BA_REL_ "GenSigTimeoutTime" BU_SG_REL_ BLTN_CAM SG_ 884 HU_MM_Latitude 5000;
BA_REL_ "GenSigTimeoutTime" BU_SG_REL_ BLTN_CAM SG_ 884 HU_MM_Longitude 5000;
VAL_ 952 BLTN_CAM_Set_FR_Ver_Pos 0 "Mid" 1 "Upper Level (1 ~ 10)" 2 "Upper Level (1 ~ 10)" 3 "Upper Level (1 ~ 10)" 4 "Upper Level (1 ~ 10)" 5 "Upper Level (1 ~ 10)" 6 "Upper Level (1 ~ 10)" 7 "Upper Level (1 ~ 10)" 8 "Upper Level (1 ~ 10)" 9 "Upper Level (1 ~ 10)" 10 "Upper Level (1 ~ 10)" 11 "Reserved" 12 "Reserved" 13 "Reserved" 14 "Reserved" 15 "Reserved" 16 "Reserved" 17 "Lower Level (-1 ~ -10)" 18 "Lower Level (-1 ~ -10)" 19 "Lower Level (-1 ~ -10)" 20 "Lower Level (-1 ~ -10)" 21 "Lower Level (-1 ~ -10)" 22 "Lower Level (-1 ~ -10)" 23 "Lower Level (-1 ~ -10)" 24 "Lower Level (-1 ~ -10)" 25 "Lower Level (-1 ~ -10)" 26 "Lower Level (-1 ~ -10)" 27 "Reserved" 28 "Reserved" 29 "Reserved" 30 "Reserved" 31 "Invalid" ;
VAL_ 952 BLTN_CAM_Set_PEV_AppNoti 0 "Default" 1 "Off" 2 "On" 3 "Invalid" ;
VAL_ 952 BLTN_CAM_Set_WiFi_AutoOn 0 "Default" 1 "Off" 2 "On" 3 "Invalid" ;
VAL_ 952 BLTN_CAM_StrgPropSet 0 "Normal" 1 "On While Recordings" 2 "On While Parked" 3 "Driving Events" 4 "Parked Events" 5 "Reserved" 6 "Reserved" 7 "Reserved" 8 "Reserved" 9 "Reserved" 10 "Reserved" 11 "Reserved" 12 "Reserved" 13 "Reserved" 14 "Reserved" 15 "Invalid" ;
VAL_ 952 BLTN_CAM_File_DEL_CPY_Op_State 0 "Default" 1 "On Deleting" 2 "On Copying" 3 "operation completed" 4 "pausing the operation" 5 "operation canceled" 6 "Reserved" 7 "Reserved" 8 "Reserved" 9 "Reserved" 10 "Delete Error, No file(s)" 11 "Copy Error, No file(s)" 12 "Copy Error, Not enough target stroage space." 13 "The space not existed(not mounted)" 14 "the commend file is wrong." 15 "Invalid" ;
VAL_ 952 BLTN_CAM_File_DEL_CPY_NumTot 0 "Default" 1 "0x001~0xFFFB:Number of files" 65531 "0x001~0xFFFB:Number of files" 65532 "not operated" 65533 "The space not existed(not mounted)" 65534 "Not enough space" 65535 "Invalid" ;
VAL_ 952 BLTN_CAM_File_DEL_CPYed_Num 0 "Default" 1 "0x001~0xFFFB:Number of files" 65531 "0x001~0xFFFB:Number of files" 65532 "not operated" 65533 "The space not existed(not mounted)" 65534 "Not enough space" 65535 "Invalid" ;
VAL_ 952 BLTN_CAM_Set_RR_Ver_Pos 0 "Mid" 1 "Upper Level (1 ~ 10)" 2 "Upper Level (1 ~ 10)" 3 "Upper Level (1 ~ 10)" 4 "Upper Level (1 ~ 10)" 5 "Upper Level (1 ~ 10)" 6 "Upper Level (1 ~ 10)" 7 "Upper Level (1 ~ 10)" 8 "Upper Level (1 ~ 10)" 9 "Upper Level (1 ~ 10)" 10 "Upper Level (1 ~ 10)" 11 "Reserved" 12 "Reserved" 13 "Reserved" 14 "Reserved" 15 "Reserved" 16 "Reserved" 17 "Lower Level (-1 ~ -10)" 18 "Lower Level (-1 ~ -10)" 19 "Lower Level (-1 ~ -10)" 20 "Lower Level (-1 ~ -10)" 21 "Lower Level (-1 ~ -10)" 22 "Lower Level (-1 ~ -10)" 23 "Lower Level (-1 ~ -10)" 24 "Lower Level (-1 ~ -10)" 25 "Lower Level (-1 ~ -10)" 26 "Lower Level (-1 ~ -10)" 27 "Reserved" 28 "Reserved" 29 "Reserved" 30 "Reserved" 31 "Invalid" ;
VAL_ 1219 BLTN_CAM_Rec_OWD_NvalueSet 0 "Default" 1 "Off" 2 "On" 3 "Invalid" ;
VAL_ 1219 BLTN_CAM_Time_Stm_NvalueSet 0 "Default" 1 "Off" 2 "On" 3 "Invalid" ;
VAL_ 1219 BLTN_CAM_Spd_Stm_NvalueSet 0 "Default" 1 "Off" 2 "On" 3 "Invalid" ;
VAL_ 1219 BLTN_CAM_Locatn_Stm_NvalueSet 0 "Default" 1 "Off" 2 "On" 3 "Invalid" ;
VAL_ 1219 BLTN_CAM_TrnSig_Stm_NvalueSet 0 "Default" 1 "Off" 2 "On" 3 "Invalid" ;
VAL_ 1219 BLTN_CAM_AclBrk_Stm_NvalueSet 0 "Default" 1 "Off" 2 "On" 3 "Invalid" ;
VAL_ 1219 BLTN_CAM_Rec_DEV_NvalueSet 0 "Default" 1 "Off" 2 "On" 3 "Invalid" ;
VAL_ 1219 BLTN_CAM_GearPos_Stm_NvalueSet 0 "Default" 1 "Off" 2 "On" 3 "Invalid" ;
VAL_ 1219 BLTN_CAM_EVSen_Stm_NvalueSet 0 "Default" 1 "Off" 2 "On" 3 "Invalid" ;
VAL_ 1219 BLTN_CAM_Strangl_Stm_NvalueSet 0 "Default" 1 "Off" 2 "On" 3 "Invalid" ;
VAL_ 1219 BLTN_CAM_EV_RecMaxTime_NvalueSet 0 "Default" 1 "Off" 2 "On" 3 "Invalid" ;
VAL_ 1219 BLTN_CAM_PrkTime_NvalueSet 0 "Default" 1 "0x01~0xFB:1~ 251  hr" 251 "0x01~0xFB:1~ 251  hr" 252 "RESERVED" 253 "RESERVED" 254 "Not Supported" 255 "Invalid" ;
VAL_ 1219 BLTN_CAM_EV_BfrTime_NvalueSet 0 "10~20 sec" 1 "10~20 sec" 2 "10~20 sec" 3 "10~20 sec" 4 "10~20 sec" 5 "10~20 sec" 6 "10~20 sec" 7 "10~20 sec" 8 "10~20 sec" 9 "10~20 sec" 10 "10~20 sec" 11 "RESERVED" 12 "RESERVED" 13 "RESERVED" 14 "RESERVED" 15 "RESERVED" 16 "RESERVED" 17 "RESERVED" 18 "RESERVED" 19 "RESERVED" 20 "RESERVED" 21 "RESERVED" 22 "RESERVED" 23 "RESERVED" 24 "RESERVED" 25 "RESERVED" 26 "RESERVED" 27 "RESERVED" 28 "RESERVED" 29 "RESERVED" 30 "RESERVED" 31 "Invalid" ;
VAL_ 1219 BLTN_CAM_Rec_OWP_NvalueSet 0 "Default" 1 "Off" 2 "On" 3 "Invalid" ;
VAL_ 1219 BLTN_CAM_EV_AftTime_NvalueSet 0 "10~20 sec" 1 "10~20 sec" 2 "10~20 sec" 3 "10~20 sec" 4 "10~20 sec" 5 "10~20 sec" 6 "10~20 sec" 7 "10~20 sec" 8 "10~20 sec" 9 "10~20 sec" 10 "10~20 sec" 11 "RESERVED" 12 "RESERVED" 13 "RESERVED" 14 "RESERVED" 15 "RESERVED" 16 "RESERVED" 17 "RESERVED" 18 "RESERVED" 19 "RESERVED" 20 "RESERVED" 21 "RESERVED" 22 "RESERVED" 23 "RESERVED" 24 "RESERVED" 25 "RESERVED" 26 "RESERVED" 27 "RESERVED" 28 "RESERVED" 29 "RESERVED" 30 "RESERVED" 31 "Invalid" ;
VAL_ 1219 BLTN_CAM_TML_Int_NvalueSet 0 "Default" 1 "1~ 10 sec" 2 "1~ 10 sec" 3 "1~ 10 sec" 4 "1~ 10 sec" 5 "1~ 10 sec" 6 "1~ 10 sec" 7 "1~ 10 sec" 8 "1~ 10 sec" 9 "1~ 10 sec" 10 "1~ 10 sec" 11 "Reserved" 12 "Reserved" 13 "Reserved" 14 "Reserved" 15 "Invalid" ;
VAL_ 1219 BLTN_CAM_Sen_DEV_NvalueSet 0 "Default" 1 "Level 1" 2 "Level 2" 3 "Level 3" 4 "Level 4" 5 "Level 5" 6 "Reserved" 7 "Reserved" 8 "Reserved" 9 "Reserved" 10 "Reserved" 11 "Reserved" 12 "Reserved" 13 "Reserved" 14 "Reserved" 15 "Invalid" ;
VAL_ 1219 BLTN_CAM_Sen_PEV_NvalueSet 0 "Default" 1 "Level 1" 2 "Level 2" 3 "Level 3" 4 "Level 4" 5 "Level 5" 6 "Reserved" 7 "Reserved" 8 "Reserved" 9 "Reserved" 10 "Reserved" 11 "Reserved" 12 "Reserved" 13 "Reserved" 14 "Reserved" 15 "Invalid" ;
VAL_ 1219 BLTN_CAM_Rec_PEV_NvalueSet 0 "Default" 1 "Off" 2 "On" 3 "Invalid" ;
VAL_ 1219 BLTN_CAM_AudRec_NvalueSet 0 "Default" 1 "Off" 2 "On" 3 "Invalid" ;
VAL_ 950 BLTN_CAM_State 0 "BLTN_CAM Valid" 1 "BLTN_CAM Front Camera Invalid" 2 "BLTN_CAM Rear Camera Invalid" 3 "BLTN_CAM Front/Rear Camera Inavlid" 4 "BLTN_CAM Record Invalid" 5 "Reserved" 6 "Reserved" 7 "Reserved" 8 "Reserved" 9 "Reserved" 10 "Reserved" 11 "Reserved" 12 "Reserved" 13 "Reserved" 14 "Reserved" 15 "Invalid" ;
VAL_ 950 BLTN_CAM_RecSta_DEV 0 "Off" 1 "Recording" 2 "Reserved" 3 "invalid" ;
VAL_ 950 BLTN_CAM_RecSta_MAR 0 "Off" 1 "Recording" 2 "Reserved" 3 "invalid" ;
VAL_ 950 BLTN_CAM_RecSta_TML 0 "Off" 1 "Recording" 2 "Reserved" 3 "invalid" ;
VAL_ 950 BLTN_CAM_RecSta_OWP 0 "Off" 1 "Recording" 2 "Reserved" 3 "invalid" ;
VAL_ 950 BLTN_CAM_RecSta_PEV 0 "Off" 1 "Recording" 2 "Reserved" 3 "invalid" ;
VAL_ 950 BLTN_CAM_Prk_EV_Cnt 0 "0x0x0~0xC8:the number of the Park Event Record(0~200)" 200 "0x0x0~0xC8:the number of the Park Event Record(0~200)" 201 "Reserved" 202 "Reserved" 203 "Reserved" 204 "Reserved" 205 "Reserved" 206 "Reserved" 207 "Reserved" 208 "Reserved" 209 "Reserved" 210 "Reserved" 211 "Reserved" 212 "Reserved" 213 "Reserved" 214 "Reserved" 215 "Reserved" 216 "Reserved" 217 "Reserved" 218 "Reserved" 219 "Reserved" 220 "Reserved" 221 "Reserved" 222 "Reserved" 223 "Reserved" 224 "Reserved" 225 "Reserved" 226 "Reserved" 227 "Reserved" 228 "Reserved" 229 "Reserved" 230 "Reserved" 231 "Reserved" 232 "Reserved" 233 "Reserved" 234 "Reserved" 235 "Reserved" 236 "Reserved" 237 "Reserved" 238 "Reserved" 239 "Reserved" 240 "Reserved" 241 "Reserved" 242 "Reserved" 243 "Reserved" 244 "Reserved" 245 "Reserved" 246 "Reserved" 247 "Reserved" 248 "Reserved" 249 "Reserved" 250 "Reserved" 251 "Reserved" 252 "Over than 200 count" 253 "Park Mode was not Excuted" 254 "Park Mode was not Supported" 255 "invalid" ;
VAL_ 950 BLTN_CAM_Prk_Oped_Time 0 "Park Mode was not Excuted" 1 "0x1~0xFB:the hours of Park Mode Operated" 251 "0x1~0xFB:the hours of Park Mode Operated" 252 "RESERVED" 253 "RESERVED" 254 "RESERVED" 255 "invalid" ;
VAL_ 950 BLTN_CAM_Prk_Oprable_Time 0 "0x0x0~0xFB:the hours of Park Mode Operatable" 251 "0x0x0~0xFB:the hours of Park Mode Operatable" 252 "RESERVED" 253 "Auxiliary Battery is not connected. - Auxiliary Battery applicable on this vehicle model" 254 "Auxiliary Battery is not connected. ? Auxiliary Battery not applicable on this vehicle model" 255 "Invalid" ;
VAL_ 950 BLTN_CAM_SD_Card_State 0 "Good, SD card is OK.(Green State)" 1 "SD card replacement recommend.(Yallow State)" 2 "SD card replacement required.(Red State)" 3 "SD card unrecognizable or No SD card found." 4 "SD card total capacity spec less than 64GByte (Built-in Cam Support 64GByte or higher)" 5 "SD card file system is not for Built-in Cam(Built-in CAM only support exFAT filesystem)" 6 "SD card not enough free space, need more free space for built-in Cam(less than 32GByte, must be 32GB" 7 "SD card recognized but Health State is not available (Gray State)" 8 "SD card Unmounted" 9 "RESERVED" 10 "RESERVED" 11 "RESERVED" 12 "RESERVED" 13 "RESERVED" 14 "RESERVED" 15 "Invalid(Red State)" ;
VAL_ 950 BLTN_CAM_Prk_Oprable_Time_Max 0 "0x0x0~0xFB:the hours of Park Mode Operatable" 251 "0x0x0~0xFB:the hours of Park Mode Operatable" 252 "RESERVED" 253 "Auxiliary Battery is not connected. - Auxiliary Battery applicable on this vehicle model" 254 "Auxiliary Battery is not connected. ? Auxiliary Battery not applicable on this vehicle model" 255 "Invalid" ;
VAL_ 950 BLTN_CAM_AuxBat_Conn_State 0 "Default" 1 "Auxiliary Battery is connected.(P-LBM or B-LBM)" 2 "Auxiliary Battery is not connected. - Auxiliary Battery applicable on this vehicle model" 3 "Auxiliary Battery is not connected. ? Auxiliary Battery not applicable on this vehicle model" ;
VAL_ 950 BLTN_CAM_AuxBat_CapPer 0 "0x0x0~0x64: Aux Bat Capacity Percent(0~100%)" 100 "0x0x0~0x64: Aux Bat Capacity Percent(0~100%)" 100 "Reserved" 101 "Reserved" 102 "Reserved" 103 "Reserved" 104 "Reserved" 105 "Reserved" 106 "Reserved" 107 "Reserved" 108 "Reserved" 109 "Reserved" 110 "Reserved" 111 "Reserved" 112 "Reserved" 113 "Reserved" 114 "Reserved" 115 "Reserved" 116 "Reserved" 117 "Reserved" 118 "Reserved" 119 "Reserved" 120 "Reserved" 121 "Reserved" 122 "Reserved" 123 "Reserved" 124 "Reserved" 125 "Reserved" 126 "Reserved" 127 "Invalid" ;
VAL_ 950 BLTN_CAM_RecSta_OWD 0 "Off" 1 "Recording" 2 "Reserved" 3 "invalid" ;
VAL_ 951 BLTN_CAM_RecSet_OWD 0 "Default" 1 "Off" 2 "On" 3 "Invalid" ;
VAL_ 951 BLTN_CAM_Set_Tim_Stm 0 "Default" 1 "Off" 2 "On" 3 "Invalid" ;
VAL_ 951 BLTN_CAM_Set_Spd_Stm 0 "Default" 1 "Off" 2 "On" 3 "Invalid" ;
VAL_ 951 BLTN_CAM_Set_Locatn_Stm 0 "Default" 1 "Off" 2 "On" 3 "Invalid" ;
VAL_ 951 BLTN_CAM_Set_TrnSig_Stm 0 "Default" 1 "Off" 2 "On" 3 "Invalid" ;
VAL_ 951 BLTN_CAM_Set_AclBrk_Stm 0 "Default" 1 "Off" 2 "On" 3 "Invalid" ;
VAL_ 951 BLTN_CAM_RecSet_DEV 0 "Default" 1 "Off" 2 "On" 3 "Invalid" ;
VAL_ 951 BLTN_CAM_Set_GearPos_Stm 0 "Default" 1 "Off" 2 "On" 3 "Invalid" ;
VAL_ 951 BLTN_CAM_Set_EVSen_Stm 0 "Default" 1 "Off" 2 "On" 3 "Invalid" ;
VAL_ 951 BLTN_CAM_Set_StrAngl_Stm 0 "Default" 1 "Off" 2 "On" 3 "Invalid" ;
VAL_ 951 BLTN_CAM_Set_EV_RecMaxTime 0 "Default" 1 "Off" 2 "On" 3 "Default" ;
VAL_ 951 BLTN_CAM_Set_PrkTime 0 "Default" 1 "0x01~0xFB: 1~ 251 hr" 251 "0x01~0xFB: 1~ 251 hr" 252 "RESERVED" 253 "RESERVED" 254 "Not Supported" 255 "Invalid" ;
VAL_ 951 BLTN_CAM_Set_EV_BfrTime 0 "10~20 sec" 1 "10~20 sec" 2 "10~20 sec" 3 "10~20 sec" 4 "10~20 sec" 5 "10~20 sec" 6 "10~20 sec" 7 "10~20 sec" 8 "10~20 sec" 9 "10~20 sec" 10 "10~20 sec" 11 "Reserved" 12 "Reserved" 13 "Reserved" 14 "Reserved" 15 "Reserved" 16 "Reserved" 17 "Reserved" 18 "Reserved" 19 "Reserved" 20 "Reserved" 21 "Reserved" 22 "Reserved" 23 "Reserved" 24 "Reserved" 25 "Reserved" 26 "Reserved" 27 "Reserved" 28 "Reserved" 29 "Reserved" 30 "Reserved" 31 "Invalid" ;
VAL_ 951 BLTN_CAM_RecSet_OWP 0 "Default" 1 "Off" 2 "On" 3 "Invalid" ;
VAL_ 951 BLTN_CAM_Set_EV_AftTime 0 "10~20 sec" 1 "10~20 sec" 2 "10~20 sec" 3 "10~20 sec" 4 "10~20 sec" 5 "10~20 sec" 6 "10~20 sec" 7 "10~20 sec" 8 "10~20 sec" 9 "10~20 sec" 10 "10~20 sec" 11 "Reserved" 12 "Reserved" 13 "Reserved" 14 "Reserved" 15 "Reserved" 16 "Reserved" 17 "Reserved" 18 "Reserved" 19 "Reserved" 20 "Reserved" 21 "Reserved" 22 "Reserved" 23 "Reserved" 24 "Reserved" 25 "Reserved" 26 "Reserved" 27 "Reserved" 28 "Reserved" 29 "Reserved" 30 "Reserved" 31 "Invalid" ;
VAL_ 951 BLTN_CAM_Set_Drv_TML_Int 0 "Default" 1 "1~ 10 sec" 2 "1~ 10 sec" 3 "1~ 10 sec" 4 "1~ 10 sec" 5 "1~ 10 sec" 6 "1~ 10 sec" 7 "1~ 10 sec" 8 "1~ 10 sec" 9 "1~ 10 sec" 10 "1~ 10 sec" 11 "Reserved" 12 "Reserved" 13 "Reserved" 14 "Reserved" 15 "Invalid" ;
VAL_ 951 BLTN_CAM_SenSet_DEV 0 "Default" 1 "Level 1" 2 "Level 2" 3 "Level 3" 4 "Level 4" 5 "Level 5" 6 "Reserved" 7 "Reserved" 8 "Reserved" 9 "Reserved" 10 "Reserved" 11 "Reserved" 12 "Reserved" 13 "Reserved" 14 "Reserved" 15 "Invalid" ;
VAL_ 951 BLTN_CAM_SenSet_PEV 0 "Default" 1 "Level 1" 2 "Level 2" 3 "Level 3" 4 "Level 4" 5 "Level 5" 6 "Reserved" 7 "Reserved" 8 "Reserved" 9 "Reserved" 10 "Reserved" 11 "Reserved" 12 "Reserved" 13 "Reserved" 14 "Reserved" 15 "Invalid" ;
VAL_ 951 BLTN_CAM_RecSet_PEV 0 "Default" 1 "Off" 2 "On" 3 "Invalid" ;
VAL_ 951 BLTN_CAM_AudRec_Set 0 "Default" 1 "Off" 2 "On" 3 "Invalid" ;
VAL_ 2307024129 HEV_BrkLtSwSta 0 "Not Support" 1 "Off" 2 "On" 3 "failure" ;
VAL_ 2176872449 HDCT_GearSelDis 0 "P" 1 "L" 2 "2" 3 "3" 4 "DS Mode (by TGS lever)" 5 "D" 6 "N" 7 "R" 8 "Sports/Manual Mode" 9 "Not display at Cluster" 10 "DS Mode (by Drive Mode button)" 11 "Reserved" 12 "Paddle shift" 13 "Reserved" 14 "Intermediate Position" 15 "Fault" ;
VAL_ 1239 HU_PwrState 0 "Default" 1 "Normal On" 2 "ADM" 3 "Wait for door open" 4 "Logic Off" 5 "Remote Engine On" 6 "Reserved" 7 "Reserved" 8 "Reserved" 9 "Reserved" 10 "Reserved" 11 "Reserved" 12 "Reserved" 13 "Reserved" 14 "Reserved" 15 "Invalid" ;
VAL_ 1239 HU_VehiclePwr 0 "Key out or Audio OFF" 1 "Not used" 2 "ACC or Audio ON" 3 "KBD Wake-up" 4 "Waiting for Good-Bye (Key out or Audio OFF)" 5 "Not used" 6 "Not used" 7 "Not used" 8 "Not used" 9 "Not used" 10 "Not used" 11 "Not used" 12 "Not used" 13 "Not used" 14 "Not used" 15 "Invalid" ;
VAL_ 1240 HU_ThemeType 0 "Default" 1 "Aqua(Hyundai)" 2 "Magenta(Kia)" 3 "Eco White" 4 "Eco Black" 5 "Genesis(IKPE)" 6 "Magenta White" 7 "RESERVED" 8 "RESERVED" 9 "RESERVED" 10 "RESERVED" 11 "RESERVED" 12 "RESERVED" 13 "RESERVED" 14 "RESERVED" 15 "Invalid" 16 "Copper" 17 "Copper Rust" 18 "RESERVED" 19 "RESERVED" 20 "RESERVED" 21 "RESERVED" 22 "RESERVED" 23 "RESERVED" 24 "RESERVED" 25 "RESERVED" 26 "RESERVED" 27 "RESERVED" 28 "RESERVED" 29 "RESERVED" 30 "RESERVED" 31 "RESERVED" 32 "ccIC Light" 33 "ccIC Dark" 34 "RESERVED" 35 "RESERVED" 36 "RESERVED" 37 "RESERVED" 38 "RESERVED" 39 "RESERVED" 40 "RESERVED" 41 "RESERVED" 42 "RESERVED" 43 "RESERVED" 44 "RESERVED" 45 "RESERVED" 46 "RESERVED" 47 "RESERVED" 48 "RESERVED" 49 "RESERVED" 50 "RESERVED" 51 "RESERVED" 52 "RESERVED" 53 "RESERVED" 54 "RESERVED" 55 "RESERVED" 56 "RESERVED" 57 "RESERVED" 58 "RESERVED" 59 "RESERVED" 60 "RESERVED" 61 "RESERVED" 62 "RESERVED" 63 "RESERVED" ;
VAL_ 1240 CF_AVN_ProfileIDRValue 0 "Default" 1 "Guest" 2 "Profile 1" 3 "Profile 2" 4 "Profile 3" 5 "Profile 4" 6 "Profile 5" 7 "Profile 6" 8 "Profile 7" 9 "Profile 8" 10 "Profile 9" 11 "RESERVED" 12 "RESERVED" 13 "RESERVED" 14 "RESERVED" 15 "Invalid" ;
VAL_ 2214659330 HEV_AccelPdlVal 0 "Accelerator Pedal not activated" 1022 "Accelerator Pedal fully activated" 1023 "Accelerator Pedal is defective (fail state) or Non-ETC system (APS is not installed)" ;
VAL_ 171 BLTN_CAM_UI_Mode_Tmt_Req 0 "Default" 1 "BLTN_CAM UI Terminate Request" 2 "Reserved" 3 "invalid" ;
VAL_ 171 BLTN_CAM_Dis_Touch_BeepSound 0 "Off" 1 "ON" 2 "Keyboard On" 3 "invalid" ;
VAL_ 171 BLTN_CAM_PopUp_Req 0 "Default" 1 "Event Video Record On by manual switch" 2 "Time Lapse Record Started" 3 "Time Lapse Record Ended" 4 "micro SD card inserted" 5 "micro SD card removed" 6 "SD Card has problem(format required or need to be replaced)" 7 "Start Parking recording" 8 "Can not Start Parking recording (SD card is removed, not recognizable, or has problem)" 9 "Can not Record Event Video (SD card is removed, not recognizable, or has problem)" 10 "SD Card Unmounted" 11 "Time Lapse Record Ended without recorded file(Record frames are not enough to save.)" 12 "RESERVED" 13 "RESERVED" 14 "RESERVED" 15 "Invalid" ;
VAL_ 171 BLTN_CAM_File_List_Renew 0 "Defalut" 1 "the file list and storage space are renewed." 2 "reserved" 3 "Invalid" ;
VAL_ 171 BLTN_CAM_Wifi_Pwd_Chg_State 0 "Default" 1 "the password is changed" 2 "Failed, wrong password, can't change password" 3 "Invalid" ;
VAL_ 2164277249 TCU_GearSlctDis 0 "P" 1 "L" 2 "2" 3 "3" 4 "DS Mode" 5 "D" 6 "N" 7 "R" 8 "sports mode / manual shift / paddle shift" 9 "Not Display at Cluster" 10 "Sub-Rom Communication" 11 "Sub-Rom Communication Error" 12 "Paddle shift (D-position)" 13 "Reserved" 14 "Intermediate Position" 15 "fault" ;
VAL_ 2172675329 IEB_BrkActvSta 0 "ECU does not support this function." 1 "Brake switch is not pressed (OFF)" 2 "Brake switch is pressed (ON)" 3 "Brake switch failure" ;
VAL_ 172 BLTN_CAM_FR_VerPos_NvalueSet 0 "Mid" 1 "Upper Level (1 ~ 10)" 2 "Upper Level (1 ~ 10)" 3 "Upper Level (1 ~ 10)" 4 "Upper Level (1 ~ 10)" 5 "Upper Level (1 ~ 10)" 6 "Upper Level (1 ~ 10)" 7 "Upper Level (1 ~ 10)" 8 "Upper Level (1 ~ 10)" 9 "Upper Level (1 ~ 10)" 10 "Upper Level (1 ~ 10)" 11 "RESERVED" 12 "RESERVED" 13 "RESERVED" 14 "RESERVED" 15 "RESERVED" 16 "RESERVED" 17 "Lower Level (-1 ~ -10)" 18 "Lower Level (-1 ~ -10)" 19 "Lower Level (-1 ~ -10)" 20 "Lower Level (-1 ~ -10)" 21 "Lower Level (-1 ~ -10)" 22 "Lower Level (-1 ~ -10)" 23 "Lower Level (-1 ~ -10)" 24 "Lower Level (-1 ~ -10)" 25 "Lower Level (-1 ~ -10)" 26 "Lower Level (-1 ~ -10)" 27 "RESERVED" 28 "RESERVED" 29 "RESERVED" 30 "RESERVED" 31 "Invalid" ;
VAL_ 172 BLTN_CAM_AppNoti_PEV_NvalueSet 0 "Default" 1 "Off" 2 "On" 3 "Invalid" ;
VAL_ 172 BLTN_CAM_WiFi_AutoOn_NvalueSet 0 "Default" 1 "Off" 2 "On" 3 "Invalid" ;
VAL_ 172 BLTN_CAM_StoProp_NvalueSet 0 "Normal" 1 "On While Recordings" 2 "On While Parked" 3 "Driving Events" 4 "Parked Events" 5 "Reserved" 6 "Reserved" 7 "Reserved" 8 "Reserved" 9 "Reserved" 10 "Reserved" 11 "Reserved" 12 "Reserved" 13 "Reserved" 14 "Reserved" 15 "Invalid" ;
VAL_ 172 CF_AVN_BLTN_CAM_USMReset 0 "Default" 1 "Built-in CAM USM Reset" 2 "Reserved" 3 "Invalid" ;
VAL_ 172 CF_AVN_BLTN_CAM_RecReset 0 "Default" 1 "Record Data Reset(format)" 2 "Reserved" 3 "Invalid" ;
VAL_ 172 BLTN_CAM_File_DEL_CPY_Cmd 0 "Default" 1 "Pause the operation" 2 "Cancel the operation" 3 "Continue operation" 4 "Reserved" 5 "Reserved" 6 "Reserved" 7 "Reserved" 8 "Reserved" 9 "Reserved" 10 "Reserved" 11 "Reserved" 12 "Reserved" 13 "Reserved" 14 "Reserved" 15 "Invalid" ;
VAL_ 172 BLTN_CAM_LVDS_Mode_Cmd 0 "Front and Rear Camera" 1 "Front Camera for AR Navi." 2 "Built-In Cam Engineer Mode" 3 "Reserved" ;
VAL_ 172 HU_BLTN_CAM_Disp_Touch_Pos_X 0 "0x0x0~0x77F:X position of the touch(Pixel)" 1919 "0x0x0~0x77F:X position of the touch(Pixel)" 2046 "Default" 2047 "Invalid" ;
VAL_ 172 HU_BLTN_CAM_Disp_Touch_Pos_Y 0 "0x0x0~0x3FD:Y position of the touch(Pixel)" 1021 "0x0x0~0x3FD:Y position of the touch(Pixel)" 1022 "Default" 1023 "Invalid" ;
VAL_ 172 MEV_Rec_Req 0 "Default" 1 "On" 2 "RESERVED" 3 "Invalid" ;
VAL_ 172 BLTN_CAM_RR_VerPos_NvalueSet 0 "Mid" 1 "Upper Level (1 ~ 10)" 2 "Upper Level (1 ~ 10)" 3 "Upper Level (1 ~ 10)" 4 "Upper Level (1 ~ 10)" 5 "Upper Level (1 ~ 10)" 6 "Upper Level (1 ~ 10)" 7 "Upper Level (1 ~ 10)" 8 "Upper Level (1 ~ 10)" 9 "Upper Level (1 ~ 10)" 10 "Upper Level (1 ~ 10)" 11 "RESERVED" 12 "RESERVED" 13 "RESERVED" 14 "RESERVED" 15 "RESERVED" 16 "RESERVED" 17 "Lower Level (-1 ~ -10)" 18 "Lower Level (-1 ~ -10)" 19 "Lower Level (-1 ~ -10)" 20 "Lower Level (-1 ~ -10)" 21 "Lower Level (-1 ~ -10)" 22 "Lower Level (-1 ~ -10)" 23 "Lower Level (-1 ~ -10)" 24 "Lower Level (-1 ~ -10)" 25 "Lower Level (-1 ~ -10)" 26 "Lower Level (-1 ~ -10)" 27 "RESERVED" 28 "RESERVED" 29 "RESERVED" 30 "RESERVED" 31 "Invalid" ;
VAL_ 172 TML_Rec_Req 0 "Default" 1 "Start Request" 2 "End Request" 3 "Invalid" ;
VAL_ 172 BLTN_CAM_SD_Card_UnMt_Mt_Req 0 "Default" 1 "UnMount Request" 2 "Mount Request" 3 "Invalid" ;
VAL_ 799 DRV_CrashUnlockCmd 0 "Off" 1 "Unlock(Crash)" ;
VAL_ 799 Warn_DrvDrSwSta_SBCM 0 "Close" 1 "Open" 2 "RESERVED" 3 "Error Indicator" ;
VAL_ 2227254529 BAT_SocVal 255 "Error indicator" ;
VAL_ 912 HU_BLTN_CAM_UI_Mode 0 "HU UI mode" 1 "Built-In Cam Mode(GUI or HU File Access)" 2 "Built-In Cam Setting Mode" 3 "RESERVED" 4 "RESERVED" 5 "RESERVED" 6 "RESERVED" 7 "RESERVED" 8 "RESERVED" 9 "RESERVED" 10 "RESERVED" 11 "RESERVED" 12 "RESERVED" 13 "RESERVED" 14 "RESERVED" 15 "Invalid" ;
VAL_ 912 HU_BLTN_CAM_Display 0 "AVN Mode" 1 "DVRS Mode" 2 "Popup Mode" 3 "RESERVED" 4 "RESERVED" 5 "Built-in Cam update mode" 6 "RESERVED" 7 "Invalid" ;
VAL_ 1266 HU_LanguageInfo 0 "Off" 1 "Korea" 2 "English(US)" 3 "English(UK)" 4 "Simplified chinese" 5 "Traditional chinese" 6 "French(EU)" 7 "Spanish(EU)" 8 "Arabic" 9 "Czech" 10 "Danish" 11 "German" 12 "Italian" 13 "Dutch" 14 "Polish" 15 "Portuguese" 16 "Russain" 17 "Slovak" 18 "Swedish" 19 "Turkish" 20 "French(US)" 21 "Spanish(US)" 22 "English(India)" 23 "Norwegian" 24 "Finnish" 25 "Indonesian" 26 "Brazilian Portuguese" 27 "Malay" 28 "Hungarian" 29 "English (Australia)" 30 "Japanese" 31 "Hindi" 32 "Hebrew" 33 "Greek" 34 "Ukrainian" 35 "Slovenian" 36 "Bulgarian" 37 "Croatian" 38 "Romanian" 39 "Bengali" 40 "Marathi" 41 "Telugu" 42 "Tamil" 43 "Gujarati" 44 "Kannada" 45 "Odia" 46 "Malayalam" 47 "Punjabi" 48 "Thai" 49 "Tagalog" 50 "Vietnamese" 51 "0x33~0xFE:RESERVED" 254 "0x33~0xFE:RESERVED" 255 "Invalid" ;
VAL_ 905 RR_CrashUnlockCmd 0 "Off" 1 "Unlock (Crash)" ;
VAL_ 905 Warn_RrRtDrSwSta_SBCM 0 "Close" 1 "Open" 2 "RESERVED" 3 "Error Indicator" ;
VAL_ 1264 HU_TimeSetting 0 "not used" 1 "User Time" 2 "GPS Time" 3 "invalid" ;
VAL_ 1264 HU_DisplayMinute 0 "0 minute" 1 "1~59 minute" 2 "1~59 minute" 3 "1~59 minute" 4 "1~59 minute" 5 "1~59 minute" 6 "1~59 minute" 7 "1~59 minute" 8 "1~59 minute" 9 "1~59 minute" 10 "1~59 minute" 11 "1~59 minute" 12 "1~59 minute" 13 "1~59 minute" 14 "1~59 minute" 15 "1~59 minute" 16 "1~59 minute" 17 "1~59 minute" 18 "1~59 minute" 19 "1~59 minute" 20 "1~59 minute" 21 "1~59 minute" 22 "1~59 minute" 23 "1~59 minute" 24 "1~59 minute" 25 "1~59 minute" 26 "1~59 minute" 27 "1~59 minute" 28 "1~59 minute" 29 "1~59 minute" 30 "1~59 minute" 31 "1~59 minute" 32 "1~59 minute" 33 "1~59 minute" 34 "1~59 minute" 35 "1~59 minute" 36 "1~59 minute" 37 "1~59 minute" 38 "1~59 minute" 39 "1~59 minute" 40 "1~59 minute" 41 "1~59 minute" 42 "1~59 minute" 43 "1~59 minute" 44 "1~59 minute" 45 "1~59 minute" 46 "1~59 minute" 47 "1~59 minute" 48 "1~59 minute" 49 "1~59 minute" 50 "1~59 minute" 51 "1~59 minute" 52 "1~59 minute" 53 "1~59 minute" 54 "1~59 minute" 55 "1~59 minute" 56 "1~59 minute" 57 "1~59 minute" 58 "1~59 minute" 59 "1~59 minute" 60 "0x3C~0xFE:RESERVED" 254 "0x3C~0xFE:RESERVED" 255 "Invalid" ;
VAL_ 1264 HU_Status 0 "Not used" 1 "Booting Head Unit" 2 "GPS receiving" 3 "Setting Mode" 4 "GPS Unavailable Mode" 5 "No GPS" 6 "RESERVED" 7 "RESERVED" 8 "RESERVED" 9 "RESERVED" 10 "RESERVED" 11 "RESERVED" 12 "RESERVED" 13 "RESERVED" 14 "RESERVED" 15 "Invalid" ;
VAL_ 1264 HU_DisplaySecond 0 "0 second" 1 "1~59 second" 2 "1~59 second" 3 "1~59 second" 4 "1~59 second" 5 "1~59 second" 6 "1~59 second" 7 "1~59 second" 8 "1~59 second" 9 "1~59 second" 10 "1~59 second" 11 "1~59 second" 12 "1~59 second" 13 "1~59 second" 14 "1~59 second" 15 "1~59 second" 16 "1~59 second" 17 "1~59 second" 18 "1~59 second" 19 "1~59 second" 20 "1~59 second" 21 "1~59 second" 22 "1~59 second" 23 "1~59 second" 24 "1~59 second" 25 "1~59 second" 26 "1~59 second" 27 "1~59 second" 28 "1~59 second" 29 "1~59 second" 30 "1~59 second" 31 "1~59 second" 32 "1~59 second" 33 "1~59 second" 34 "1~59 second" 35 "1~59 second" 36 "1~59 second" 37 "1~59 second" 38 "1~59 second" 39 "1~59 second" 40 "1~59 second" 41 "1~59 second" 42 "1~59 second" 43 "1~59 second" 44 "1~59 second" 45 "1~59 second" 46 "1~59 second" 47 "1~59 second" 48 "1~59 second" 49 "1~59 second" 50 "1~59 second" 51 "1~59 second" 52 "1~59 second" 53 "1~59 second" 54 "1~59 second" 55 "1~59 second" 56 "1~59 second" 57 "1~59 second" 58 "1~59 second" 59 "1~59 second" 60 "0x3C~0xFE:RESERVED" 254 "0x3C~0xFE:RESERVED" 255 "Invalid" ;
VAL_ 1264 HU_DisplayMonth 0 "Not used" 1 "1~12 month" 2 "1~12 month" 3 "1~12 month" 4 "1~12 month" 5 "1~12 month" 6 "1~12 month" 7 "1~12 month" 8 "1~12 month" 9 "1~12 month" 10 "1~12 month" 11 "1~12 month" 12 "1~12 month" 13 "RESERVED" 14 "RESERVED" 15 "Invalid" ;
VAL_ 1264 HU_DisplayYear1 0 "19" 1 "20" 2 "21" 3 "invalid" ;
VAL_ 1264 HU_DisplayYear2 0 "00 year" 1 "01~99 year" 2 "01~99 year" 3 "01~99 year" 4 "01~99 year" 5 "01~99 year" 6 "01~99 year" 7 "01~99 year" 8 "01~99 year" 9 "01~99 year" 10 "01~99 year" 11 "01~99 year" 12 "01~99 year" 13 "01~99 year" 14 "01~99 year" 15 "01~99 year" 16 "01~99 year" 17 "01~99 year" 18 "01~99 year" 19 "01~99 year" 20 "01~99 year" 21 "01~99 year" 22 "01~99 year" 23 "01~99 year" 24 "01~99 year" 25 "01~99 year" 26 "01~99 year" 27 "01~99 year" 28 "01~99 year" 29 "01~99 year" 30 "01~99 year" 31 "01~99 year" 32 "01~99 year" 33 "01~99 year" 34 "01~99 year" 35 "01~99 year" 36 "01~99 year" 37 "01~99 year" 38 "01~99 year" 39 "01~99 year" 40 "01~99 year" 41 "01~99 year" 42 "01~99 year" 43 "01~99 year" 44 "01~99 year" 45 "01~99 year" 46 "01~99 year" 47 "01~99 year" 48 "01~99 year" 49 "01~99 year" 50 "01~99 year" 51 "01~99 year" 52 "01~99 year" 53 "01~99 year" 54 "01~99 year" 55 "01~99 year" 56 "01~99 year" 57 "01~99 year" 58 "01~99 year" 59 "01~99 year" 60 "01~99 year" 61 "01~99 year" 62 "01~99 year" 63 "01~99 year" 64 "01~99 year" 65 "01~99 year" 66 "01~99 year" 67 "01~99 year" 68 "01~99 year" 69 "01~99 year" 70 "01~99 year" 71 "01~99 year" 72 "01~99 year" 73 "01~99 year" 74 "01~99 year" 75 "01~99 year" 76 "01~99 year" 77 "01~99 year" 78 "01~99 year" 79 "01~99 year" 80 "01~99 year" 81 "01~99 year" 82 "01~99 year" 83 "01~99 year" 84 "01~99 year" 85 "01~99 year" 86 "01~99 year" 87 "01~99 year" 88 "01~99 year" 89 "01~99 year" 90 "01~99 year" 91 "01~99 year" 92 "01~99 year" 93 "01~99 year" 94 "01~99 year" 95 "01~99 year" 96 "01~99 year" 97 "01~99 year" 98 "01~99 year" 99 "01~99 year" 100 "0x64~0xFE:RESERVED" 254 "0x64~0xFE:RESERVED" 255 "Invalid" ;
VAL_ 1264 HU_DisplayDay 0 "Not used" 1 "1~31 day" 2 "1~31 day" 3 "1~31 day" 4 "1~31 day" 5 "1~31 day" 6 "1~31 day" 7 "1~31 day" 8 "1~31 day" 9 "1~31 day" 10 "1~31 day" 11 "1~31 day" 12 "1~31 day" 13 "1~31 day" 14 "1~31 day" 15 "1~31 day" 16 "1~31 day" 17 "1~31 day" 18 "1~31 day" 19 "1~31 day" 20 "1~31 day" 21 "1~31 day" 22 "1~31 day" 23 "1~31 day" 24 "1~31 day" 25 "1~31 day" 26 "1~31 day" 27 "1~31 day" 28 "1~31 day" 29 "1~31 day" 30 "1~31 day" 31 "1~31 day" 32 "0x20~0xFE:RESERVED" 254 "0x20~0xFE:RESERVED" 255 "Invalid" ;
VAL_ 1264 HU_AM_PM_INFO 0 "Not Used" 1 "AM" 2 "PM" 3 "invalid" ;
VAL_ 1264 HU_TimeFormat 0 "Not used" 1 "12Hour" 2 "24Hour" 3 "invalid" ;
VAL_ 1264 HU_ComRefresh 0 "Not Used" 1 "Internal Clock None" 2 "Internal Clock Exist" 3 "Invalid" ;
VAL_ 1264 HU_ClockInfo 0 "Not Used" 1 "ACLOCK Refresh" 2 "Not Used" 3 "invalid" ;
VAL_ 1264 HU_DisplayHour 0 "0 hour" 1 "1~23 hour" 2 "1~23 hour" 3 "1~23 hour" 4 "1~23 hour" 5 "1~23 hour" 6 "1~23 hour" 7 "1~23 hour" 8 "1~23 hour" 9 "1~23 hour" 10 "1~23 hour" 11 "1~23 hour" 12 "1~23 hour" 13 "1~23 hour" 14 "1~23 hour" 15 "1~23 hour" 16 "1~23 hour" 17 "1~23 hour" 18 "1~23 hour" 19 "1~23 hour" 20 "1~23 hour" 21 "1~23 hour" 22 "1~23 hour" 23 "1~23 hour" 24 "0x18~0xFE:RESERVED" 254 "0x18~0xFE:RESERVED" 255 "Invalid" ;
VAL_ 1265 HU_Background 0 "Default" 1 "Day" 2 "Night" 3 "RESERVED" 4 "RESERVED" 5 "RESERVED" 6 "RESERVED" 7 "Invalid" ;
VAL_ 1265 HU_BackgroundFadeInOut 0 "0x0x0~0x3E8:0.0~100.0%" 1000 "0x0x0~0x3E8:0.0~100.0%" 1001 "RESERVED" 1002 "RESERVED" 1003 "RESERVED" 1004 "RESERVED" 1005 "RESERVED" 1006 "RESERVED" 1007 "RESERVED" 1008 "RESERVED" 1009 "RESERVED" 1010 "RESERVED" 1011 "RESERVED" 1012 "RESERVED" 1013 "RESERVED" 1014 "RESERVED" 1015 "RESERVED" 1016 "RESERVED" 1017 "RESERVED" 1018 "RESERVED" 1019 "RESERVED" 1020 "RESERVED" 1021 "RESERVED" 1022 "Default" 1023 "Invalid" ;
VAL_ 1278 HU_Type 0 "RESERVED" 1 "RESERVED" 2 "RESERVED" 3 "RESERVED" 4 "RESERVED" 5 "RESERVED" 6 "RESERVED" 7 "RESERVED" 8 "RESERVED" 9 "RESERVED" 10 "RESERVED" 11 "RESERVED" 12 "RESERVED" 13 "RESERVED" 14 "RESERVED" 15 "RESERVED" 16 "AVN(Tuner DVD KOR)" 17 "AVN(Tuner DVD EUR)" 18 "AVN(Tuner DVD China)" 19 "AVN(Tuner DVD Japan)" 20 "AVN(Tuner DVD EUR)" 21 "AVN(Tuner CDP KOR)" 22 "AVN(Tuner CDP EUR)" 23 "AVN(Tuner CDP China)" 24 "AVN(Tuner CDP Japan)" 25 "AVN(Tuner CDP EUR)" 26 "RESERVED" 27 "RESERVED" 28 "RESERVED" 29 "RESERVED" 30 "RESERVED" 31 "RESERVED" 32 "AVNT (Open)" 33 "AVNT (Not open)" 34 "RESERVED" 35 "RESERVED" 36 "RESERVED" 37 "RESERVED" 38 "RESERVED" 39 "RESERVED" 40 "RESERVED" 41 "RESERVED" 42 "RESERVED" 43 "RESERVED" 44 "RESERVED" 45 "RESERVED" 46 "RESERVED" 47 "RESERVED" 48 "Economic Audio" 49 "RESERVED" 50 "RESERVED" 51 "RESERVED" 52 "RESERVED" 53 "RESERVED" 54 "RESERVED" 55 "RESERVED" 56 "RESERVED" 57 "RESERVED" 58 "RESERVED" 59 "RESERVED" 60 "RESERVED" 61 "RESERVED" 62 "RESERVED" 63 "RESERVED" 64 "Standard Audio (3.0 below)" 65 "Standard Audio 4.0" 66 "STD Audio-3.0Below,No interwork" 67 "Audio 4.0 Value" 68 "RESERVED" 69 "RESERVED" 70 "RESERVED" 71 "RESERVED" 72 "RESERVED" 73 "RESERVED" 74 "RESERVED" 75 "RESERVED" 76 "RESERVED" 77 "RESERVED" 78 "RESERVED" 79 "RESERVED" 80 "AV(Tuner DVD KOR)" 81 "AV(Tuner DVD EUR)" 82 "AV(Tuner DVD China)" 83 "AV(Tuner DVD Japan)" 84 "AV(Tuner DVD EUR)" 85 "AV(Tuner CDP KOR)" 86 "AV(Tuner CDP EUR)" 87 "AV(Tuner CDP China)" 88 "AV(Tuner CDP Japan)" 89 "AV(Tuner CDP EUR)" 90 "RESERVED" 91 "RESERVED" 92 "RESERVED" 93 "RESERVED" 94 "RESERVED" 95 "RESERVED" 96 "AVN 4.0" 97 "Premium AVN2.0" 98 "EU AVN 2.0" 99 "Super Premium w Navi" 100 "Super Premium w_o Navi" 101 "Premium w Navi" 102 "Premium w_o Navi" 103 "Display Audio w_o Navi" 104 "Integrated AVN 1.0 Mobis" 105 "Gen5 Standard Nav Wide" 106 "RESERVED" 107 "RESERVED" 108 "RESERVED" 109 "RESERVED" 110 "RESERVED" 111 "RESERVED" 112 "Compact AVN & Integrated AVN 1.0 LG" 113 "RESERVED" 114 "RESERVED" 115 "RESERVED" 116 "RESERVED" 117 "RESERVED" 118 "RESERVED" 119 "RESERVED" 120 "RESERVED" 121 "RESERVED" 122 "RESERVED" 123 "RESERVED" 124 "RESERVED" 125 "RESERVED" 126 "RESERVED" 127 "RESERVED" 128 "Premium Navi 5th Gen(w_Navi)" 129 "Premium Navi 5th Gen(w_o Navi)" 130 "Premium Navi 6th Gen(w_Navi)" 131 "Premium Navi 6th Gen(w_o Navi)" 132 "ccNC(w Navi)" 133 "ccNC(w_o Navi)" 134 "ccIC(w Navi)" 135 "ccIC(w_o Navi)" 136 "RESERVED" 137 "RESERVED" 138 "RESERVED" 139 "RESERVED" 140 "RESERVED" 141 "RESERVED" 142 "RESERVED" 143 "RESERVED" 144 "RESERVED" 145 "RESERVED" 146 "RESERVED" 147 "RESERVED" 148 "RESERVED" 149 "RESERVED" 150 "RESERVED" 151 "RESERVED" 152 "RESERVED" 153 "RESERVED" 154 "RESERVED" 155 "RESERVED" 156 "RESERVED" 157 "RESERVED" 158 "RESERVED" 159 "RESERVED" 160 "RESERVED" 161 "RESERVED" 162 "RESERVED" 163 "RESERVED" 164 "RESERVED" 165 "RESERVED" 166 "RESERVED" 167 "RESERVED" 168 "RESERVED" 169 "RESERVED" 170 "RESERVED" 171 "RESERVED" 172 "RESERVED" 173 "RESERVED" 174 "RESERVED" 175 "RESERVED" 176 "RESERVED" 177 "RESERVED" 178 "RESERVED" 179 "RESERVED" 180 "RESERVED" 181 "RESERVED" 182 "RESERVED" 183 "RESERVED" 184 "RESERVED" 185 "RESERVED" 186 "RESERVED" 187 "RESERVED" 188 "RESERVED" 189 "RESERVED" 190 "RESERVED" 191 "RESERVED" 192 "RESERVED" 193 "RESERVED" 194 "RESERVED" 195 "RESERVED" 196 "RESERVED" 197 "RESERVED" 198 "RESERVED" 199 "RESERVED" 200 "RESERVED" 201 "RESERVED" 202 "RESERVED" 203 "RESERVED" 204 "RESERVED" 205 "RESERVED" 206 "RESERVED" 207 "RESERVED" 208 "RESERVED" 209 "RESERVED" 210 "RESERVED" 211 "RESERVED" 212 "RESERVED" 213 "RESERVED" 214 "RESERVED" 215 "RESERVED" 216 "RESERVED" 217 "RESERVED" 218 "RESERVED" 219 "RESERVED" 220 "RESERVED" 221 "RESERVED" 222 "RESERVED" 223 "RESERVED" 224 "RESERVED" 225 "RESERVED" 226 "RESERVED" 227 "RESERVED" 228 "RESERVED" 229 "RESERVED" 230 "RESERVED" 231 "RESERVED" 232 "RESERVED" 233 "RESERVED" 234 "RESERVED" 235 "RESERVED" 236 "RESERVED" 237 "RESERVED" 238 "India PIO w_o CLU interface" 239 "India PIO w_CLU interface" 240 "RESERVED" 241 "Gen 1 China OEM Navigation" 242 "RESERVED" 243 "RESERVED" 244 "RESERVED" 245 "RESERVED" 246 "RESERVED" 247 "RESERVED" 248 "RESERVED" 249 "RESERVED" 250 "PIO AVN" 251 "China  Local OEM Display Audio" 252 "China OPIO w_o CLU interface" 253 "China OPIO w_CLU interface" 254 "China Local OEM AVNT" 255 "Invalid" ;
VAL_ 1278 HU_DistributeInfo 0 "Default (Korea)" 1 "Korea" 2 "North America" 3 "Canada" 4 "East Europe" 5 "West Europe" 6 "China" 7 "India" 8 "Australia" 9 "Middle East" 10 "Africa" 11 "South America" 12 "Russia" 13 "Japan" 14 "General" 15 "0x0F~0xFE:Reserved" 254 "0x0F~0xFE:Reserved" 255 "Invalid" ;
VAL_ 1278 HU_OptionInfo 0 "0x0x0000~0x01FF:Bit allocation" 511 "0x0x0000~0x01FF:Bit allocation" 512 "0x0200~0x7FFF:RESERVED" 32767 "0x0200~0x7FFF:RESERVED" 32768 "Invalid" 32769 "0x8001~0xFFFF:Not used" 65535 "0x8001~0xFFFF:Not used" ;
VAL_ 2256644609 CLU_SpdUnitTyp 0 "km/h" 1 "MPH" 2 "Not used" 3 "Error Indicator" ;
VAL_ 2256644609 CLU_DisSpdVal 1023 "Error" ;
VAL_ 1016 GNSS_MM_type 0 "WGS84" 1 "Bessel" 2 "Coordshift(for china)" 15 "invalid" ;
VAL_ 883 HU_GNSS_DST 0 "DST OFF" 1 "DST ON" 2 "RESERVED" 3 "Invalid" ;
VAL_ 2256644610 CLU_AutoBrightSta 0 "Reserved (Not Used)" 1 "0x01~0xC8:Bright State (1~200 Step)" 200 "0x01~0xC8:Bright State (1~200 Step)" ;
VAL_ 2214658049 ENG_BrkSwSta 0 "Brake switch is not pressed (OFF)" 1 "Brake switch is pressed (ON)" 2 "EMS does not support this function." 3 "Brake switch failure" ;
VAL_ 2214658049 ENG_EngSta 0 "Engine Stop" 1 "Cranking" 2 "Stalled" 3 "Running" 4 "Reserved" 5 "Reserved" 6 "Reserved" 7 "Fault" ;
VAL_ 2223056129 SAS_AnglVal 0 "0x0x0000~0x7FFE:real value" 32766 "0x0x0000~0x7FFE:real value" 32767 "Error Indicator" 32768 "0x8000~0xFFFF:real value" 65535 "0x8000~0xFFFF:real value" ;
